VERSION ""

NS_ :

BS_:

BU_: L_DHRR_FD L_UWB_BLE_MST_FD L_UWB_RR_FD L_UWB_BLE_SLV_FD L_UWB_FR_FD L_ROA_FR_FD L_ROA_FD L_DHRL_FD L_UWB_TRNK_FD L_UWB_FRNK_FD L_EDT_FD L_UWB_FL_FD GW_BDC_FD L_UWB_RL_FD L_SAL_FD L_WPC_FD L_TPMS_FD L_DHL_FD L_DHR_FD

BO_ 2348810498 L_TP_BDC_FD_L_UWB_BLE_SLV_FD: 32 GW_BDC_FD
 SG_ L_TP_BDC_FD_L_UWB_BLE_SLV_FD_Byt : 0|8@1+ (1,0) [0|0] ""  L_UWB_BLE_SLV_FD
 SG_ L_TP_BDC_FD_L_UWB_BLE_SLV_F_0000 : 104|8@1+ (1,0) [0|0] ""  L_UWB_BLE_SLV_FD
 SG_ L_TP_BDC_FD_L_UWB_BLE_SLV_F_0001 : 112|8@1+ (1,0) [0|0] ""  L_UWB_BLE_SLV_FD
 SG_ L_TP_BDC_FD_L_UWB_BLE_SLV_F_0002 : 120|8@1+ (1,0) [0|0] ""  L_UWB_BLE_SLV_FD
 SG_ L_TP_BDC_FD_L_UWB_BLE_SLV_F_0003 : 128|8@1+ (1,0) [0|0] ""  L_UWB_BLE_SLV_FD
 SG_ L_TP_BDC_FD_L_UWB_BLE_SLV_F_0004 : 136|8@1+ (1,0) [0|0] ""  L_UWB_BLE_SLV_FD
 SG_ L_TP_BDC_FD_L_UWB_BLE_SLV_F_0005 : 144|8@1+ (1,0) [0|0] ""  L_UWB_BLE_SLV_FD
 SG_ L_TP_BDC_FD_L_UWB_BLE_SLV_F_0006 : 152|8@1+ (1,0) [0|0] ""  L_UWB_BLE_SLV_FD
 SG_ L_TP_BDC_FD_L_UWB_BLE_SLV_F_0007 : 16|8@1+ (1,0) [0|0] ""  L_UWB_BLE_SLV_FD
 SG_ L_TP_BDC_FD_L_UWB_BLE_SLV_F_0008 : 160|8@1+ (1,0) [0|0] ""  L_UWB_BLE_SLV_FD
 SG_ L_TP_BDC_FD_L_UWB_BLE_SLV_F_0009 : 168|8@1+ (1,0) [0|0] ""  L_UWB_BLE_SLV_FD
 SG_ L_TP_BDC_FD_L_UWB_BLE_SLV_F_0010 : 176|8@1+ (1,0) [0|0] ""  L_UWB_BLE_SLV_FD
 SG_ L_TP_BDC_FD_L_UWB_BLE_SLV_F_0011 : 184|8@1+ (1,0) [0|0] ""  L_UWB_BLE_SLV_FD
 SG_ L_TP_BDC_FD_L_UWB_BLE_SLV_F_0012 : 192|8@1+ (1,0) [0|0] ""  L_UWB_BLE_SLV_FD
 SG_ L_TP_BDC_FD_L_UWB_BLE_SLV_F_0013 : 200|8@1+ (1,0) [0|0] ""  L_UWB_BLE_SLV_FD
 SG_ L_TP_BDC_FD_L_UWB_BLE_SLV_F_0014 : 208|8@1+ (1,0) [0|0] ""  L_UWB_BLE_SLV_FD
 SG_ L_TP_BDC_FD_L_UWB_BLE_SLV_F_0015 : 216|8@1+ (1,0) [0|0] ""  L_UWB_BLE_SLV_FD
 SG_ L_TP_BDC_FD_L_UWB_BLE_SLV_F_0016 : 224|8@1+ (1,0) [0|0] ""  L_UWB_BLE_SLV_FD
 SG_ L_TP_BDC_FD_L_UWB_BLE_SLV_F_0017 : 232|8@1+ (1,0) [0|0] ""  L_UWB_BLE_SLV_FD
 SG_ L_TP_BDC_FD_L_UWB_BLE_SLV_F_0018 : 24|8@1+ (1,0) [0|0] ""  L_UWB_BLE_SLV_FD
 SG_ L_TP_BDC_FD_L_UWB_BLE_SLV_F_0019 : 240|8@1+ (1,0) [0|0] ""  L_UWB_BLE_SLV_FD
 SG_ L_TP_BDC_FD_L_UWB_BLE_SLV_F_0020 : 248|8@1+ (1,0) [0|0] ""  L_UWB_BLE_SLV_FD
 SG_ L_TP_BDC_FD_L_UWB_BLE_SLV_F_0021 : 32|8@1+ (1,0) [0|0] ""  L_UWB_BLE_SLV_FD
 SG_ L_TP_BDC_FD_L_UWB_BLE_SLV_F_0022 : 40|8@1+ (1,0) [0|0] ""  L_UWB_BLE_SLV_FD
 SG_ L_TP_BDC_FD_L_UWB_BLE_SLV_F_0023 : 48|8@1+ (1,0) [0|0] ""  L_UWB_BLE_SLV_FD
 SG_ L_TP_BDC_FD_L_UWB_BLE_SLV_F_0024 : 56|8@1+ (1,0) [0|0] ""  L_UWB_BLE_SLV_FD
 SG_ L_TP_BDC_FD_L_UWB_BLE_SLV_F_0025 : 64|8@1+ (1,0) [0|0] ""  L_UWB_BLE_SLV_FD
 SG_ L_TP_BDC_FD_L_UWB_BLE_SLV_F_0026 : 72|8@1+ (1,0) [0|0] ""  L_UWB_BLE_SLV_FD
 SG_ L_TP_BDC_FD_L_UWB_BLE_SLV_F_0027 : 8|8@1+ (1,0) [0|0] ""  L_UWB_BLE_SLV_FD
 SG_ L_TP_BDC_FD_L_UWB_BLE_SLV_F_0028 : 80|8@1+ (1,0) [0|0] ""  L_UWB_BLE_SLV_FD
 SG_ L_TP_BDC_FD_L_UWB_BLE_SLV_F_0029 : 88|8@1+ (1,0) [0|0] ""  L_UWB_BLE_SLV_FD
 SG_ L_TP_BDC_FD_L_UWB_BLE_SLV_F_0030 : 96|8@1+ (1,0) [0|0] ""  L_UWB_BLE_SLV_FD

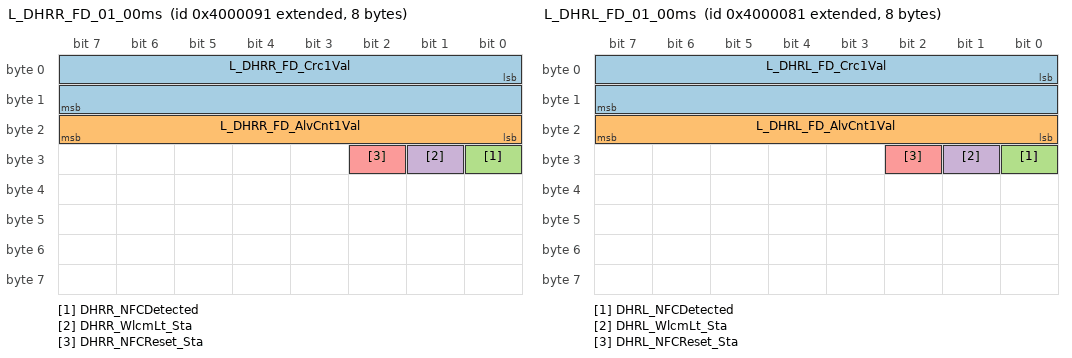
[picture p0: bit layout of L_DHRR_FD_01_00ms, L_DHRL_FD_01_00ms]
BO_ 2214592657 L_DHRR_FD_01_00ms: 8 L_DHRR_FD
 SG_ L_DHRR_FD_Crc1Val : 0|16@1+ (1,0) [0|0] "0" Vector__XXX
 SG_ L_DHRR_FD_AlvCnt1Val : 16|8@1+ (1,0) [0|0] "0" Vector__XXX
 SG_ DHRR_NFCDetected : 24|1@1+ (1,0) [0|0] ""  GW_BDC_FD
 SG_ DHRR_WlcmLt_Sta : 25|1@1+ (1,0) [0|0] ""  GW_BDC_FD
 SG_ DHRR_NFCReset_Sta : 26|1@1+ (1,0) [0|0] ""  GW_BDC_FD

BO_ 2348810497 L_TP_L_UWB_BLE_MST_FD_BDC_FD: 32 L_UWB_BLE_MST_FD
 SG_ L_TP_L_UWB_BLE_MST_FD_BDC_FD_Byt : 0|8@1+ (1,0) [0|0] ""  GW_BDC_FD
 SG_ L_TP_L_UWB_BLE_MST_FD_BDC_F_0000 : 104|8@1+ (1,0) [0|0] ""  GW_BDC_FD
 SG_ L_TP_L_UWB_BLE_MST_FD_BDC_F_0001 : 112|8@1+ (1,0) [0|0] ""  GW_BDC_FD
 SG_ L_TP_L_UWB_BLE_MST_FD_BDC_F_0002 : 120|8@1+ (1,0) [0|0] ""  GW_BDC_FD
 SG_ L_TP_L_UWB_BLE_MST_FD_BDC_F_0003 : 128|8@1+ (1,0) [0|0] ""  GW_BDC_FD
 SG_ L_TP_L_UWB_BLE_MST_FD_BDC_F_0004 : 136|8@1+ (1,0) [0|0] ""  GW_BDC_FD
 SG_ L_TP_L_UWB_BLE_MST_FD_BDC_F_0005 : 144|8@1+ (1,0) [0|0] ""  GW_BDC_FD
 SG_ L_TP_L_UWB_BLE_MST_FD_BDC_F_0006 : 152|8@1+ (1,0) [0|0] ""  GW_BDC_FD
 SG_ L_TP_L_UWB_BLE_MST_FD_BDC_F_0007 : 16|8@1+ (1,0) [0|0] ""  GW_BDC_FD
 SG_ L_TP_L_UWB_BLE_MST_FD_BDC_F_0008 : 160|8@1+ (1,0) [0|0] ""  GW_BDC_FD
 SG_ L_TP_L_UWB_BLE_MST_FD_BDC_F_0009 : 168|8@1+ (1,0) [0|0] ""  GW_BDC_FD
 SG_ L_TP_L_UWB_BLE_MST_FD_BDC_F_0010 : 176|8@1+ (1,0) [0|0] ""  GW_BDC_FD
 SG_ L_TP_L_UWB_BLE_MST_FD_BDC_F_0011 : 184|8@1+ (1,0) [0|0] ""  GW_BDC_FD
 SG_ L_TP_L_UWB_BLE_MST_FD_BDC_F_0012 : 192|8@1+ (1,0) [0|0] ""  GW_BDC_FD
 SG_ L_TP_L_UWB_BLE_MST_FD_BDC_F_0013 : 200|8@1+ (1,0) [0|0] ""  GW_BDC_FD
 SG_ L_TP_L_UWB_BLE_MST_FD_BDC_F_0014 : 208|8@1+ (1,0) [0|0] ""  GW_BDC_FD
 SG_ L_TP_L_UWB_BLE_MST_FD_BDC_F_0015 : 216|8@1+ (1,0) [0|0] ""  GW_BDC_FD
 SG_ L_TP_L_UWB_BLE_MST_FD_BDC_F_0016 : 224|8@1+ (1,0) [0|0] ""  GW_BDC_FD
 SG_ L_TP_L_UWB_BLE_MST_FD_BDC_F_0017 : 232|8@1+ (1,0) [0|0] ""  GW_BDC_FD
 SG_ L_TP_L_UWB_BLE_MST_FD_BDC_F_0018 : 24|8@1+ (1,0) [0|0] ""  GW_BDC_FD
 SG_ L_TP_L_UWB_BLE_MST_FD_BDC_F_0019 : 240|8@1+ (1,0) [0|0] ""  GW_BDC_FD
 SG_ L_TP_L_UWB_BLE_MST_FD_BDC_F_0020 : 248|8@1+ (1,0) [0|0] ""  GW_BDC_FD
 SG_ L_TP_L_UWB_BLE_MST_FD_BDC_F_0021 : 32|8@1+ (1,0) [0|0] ""  GW_BDC_FD
 SG_ L_TP_L_UWB_BLE_MST_FD_BDC_F_0022 : 40|8@1+ (1,0) [0|0] ""  GW_BDC_FD
 SG_ L_TP_L_UWB_BLE_MST_FD_BDC_F_0023 : 48|8@1+ (1,0) [0|0] ""  GW_BDC_FD
 SG_ L_TP_L_UWB_BLE_MST_FD_BDC_F_0024 : 56|8@1+ (1,0) [0|0] ""  GW_BDC_FD
 SG_ L_TP_L_UWB_BLE_MST_FD_BDC_F_0025 : 64|8@1+ (1,0) [0|0] ""  GW_BDC_FD
 SG_ L_TP_L_UWB_BLE_MST_FD_BDC_F_0026 : 72|8@1+ (1,0) [0|0] ""  GW_BDC_FD
 SG_ L_TP_L_UWB_BLE_MST_FD_BDC_F_0027 : 8|8@1+ (1,0) [0|0] ""  GW_BDC_FD
 SG_ L_TP_L_UWB_BLE_MST_FD_BDC_F_0028 : 80|8@1+ (1,0) [0|0] ""  GW_BDC_FD
 SG_ L_TP_L_UWB_BLE_MST_FD_BDC_F_0029 : 88|8@1+ (1,0) [0|0] ""  GW_BDC_FD
 SG_ L_TP_L_UWB_BLE_MST_FD_BDC_F_0030 : 96|8@1+ (1,0) [0|0] ""  GW_BDC_FD

BO_ 2348810496 L_TP_BDC_FD_L_UWB_BLE_MST_FD: 32 GW_BDC_FD
 SG_ L_TP_BDC_FD_L_UWB_BLE_MST_FD_Byt : 0|8@1+ (1,0) [0|0] ""  L_UWB_BLE_MST_FD
 SG_ L_TP_BDC_FD_L_UWB_BLE_MST_F_0000 : 104|8@1+ (1,0) [0|0] ""  L_UWB_BLE_MST_FD
 SG_ L_TP_BDC_FD_L_UWB_BLE_MST_F_0001 : 112|8@1+ (1,0) [0|0] ""  L_UWB_BLE_MST_FD
 SG_ L_TP_BDC_FD_L_UWB_BLE_MST_F_0002 : 120|8@1+ (1,0) [0|0] ""  L_UWB_BLE_MST_FD
 SG_ L_TP_BDC_FD_L_UWB_BLE_MST_F_0003 : 128|8@1+ (1,0) [0|0] ""  L_UWB_BLE_MST_FD
 SG_ L_TP_BDC_FD_L_UWB_BLE_MST_F_0004 : 136|8@1+ (1,0) [0|0] ""  L_UWB_BLE_MST_FD
 SG_ L_TP_BDC_FD_L_UWB_BLE_MST_F_0005 : 144|8@1+ (1,0) [0|0] ""  L_UWB_BLE_MST_FD
 SG_ L_TP_BDC_FD_L_UWB_BLE_MST_F_0006 : 152|8@1+ (1,0) [0|0] ""  L_UWB_BLE_MST_FD
 SG_ L_TP_BDC_FD_L_UWB_BLE_MST_F_0007 : 16|8@1+ (1,0) [0|0] ""  L_UWB_BLE_MST_FD
 SG_ L_TP_BDC_FD_L_UWB_BLE_MST_F_0008 : 160|8@1+ (1,0) [0|0] ""  L_UWB_BLE_MST_FD
 SG_ L_TP_BDC_FD_L_UWB_BLE_MST_F_0009 : 168|8@1+ (1,0) [0|0] ""  L_UWB_BLE_MST_FD
 SG_ L_TP_BDC_FD_L_UWB_BLE_MST_F_0010 : 176|8@1+ (1,0) [0|0] ""  L_UWB_BLE_MST_FD
 SG_ L_TP_BDC_FD_L_UWB_BLE_MST_F_0011 : 184|8@1+ (1,0) [0|0] ""  L_UWB_BLE_MST_FD
 SG_ L_TP_BDC_FD_L_UWB_BLE_MST_F_0012 : 192|8@1+ (1,0) [0|0] ""  L_UWB_BLE_MST_FD
 SG_ L_TP_BDC_FD_L_UWB_BLE_MST_F_0013 : 200|8@1+ (1,0) [0|0] ""  L_UWB_BLE_MST_FD
 SG_ L_TP_BDC_FD_L_UWB_BLE_MST_F_0014 : 208|8@1+ (1,0) [0|0] ""  L_UWB_BLE_MST_FD
 SG_ L_TP_BDC_FD_L_UWB_BLE_MST_F_0015 : 216|8@1+ (1,0) [0|0] ""  L_UWB_BLE_MST_FD
 SG_ L_TP_BDC_FD_L_UWB_BLE_MST_F_0016 : 224|8@1+ (1,0) [0|0] ""  L_UWB_BLE_MST_FD
 SG_ L_TP_BDC_FD_L_UWB_BLE_MST_F_0017 : 232|8@1+ (1,0) [0|0] ""  L_UWB_BLE_MST_FD
 SG_ L_TP_BDC_FD_L_UWB_BLE_MST_F_0018 : 24|8@1+ (1,0) [0|0] ""  L_UWB_BLE_MST_FD
 SG_ L_TP_BDC_FD_L_UWB_BLE_MST_F_0019 : 240|8@1+ (1,0) [0|0] ""  L_UWB_BLE_MST_FD
 SG_ L_TP_BDC_FD_L_UWB_BLE_MST_F_0020 : 248|8@1+ (1,0) [0|0] ""  L_UWB_BLE_MST_FD
 SG_ L_TP_BDC_FD_L_UWB_BLE_MST_F_0021 : 32|8@1+ (1,0) [0|0] ""  L_UWB_BLE_MST_FD
 SG_ L_TP_BDC_FD_L_UWB_BLE_MST_F_0022 : 40|8@1+ (1,0) [0|0] ""  L_UWB_BLE_MST_FD
 SG_ L_TP_BDC_FD_L_UWB_BLE_MST_F_0023 : 48|8@1+ (1,0) [0|0] ""  L_UWB_BLE_MST_FD
 SG_ L_TP_BDC_FD_L_UWB_BLE_MST_F_0024 : 56|8@1+ (1,0) [0|0] ""  L_UWB_BLE_MST_FD
 SG_ L_TP_BDC_FD_L_UWB_BLE_MST_F_0025 : 64|8@1+ (1,0) [0|0] ""  L_UWB_BLE_MST_FD
 SG_ L_TP_BDC_FD_L_UWB_BLE_MST_F_0026 : 72|8@1+ (1,0) [0|0] ""  L_UWB_BLE_MST_FD
 SG_ L_TP_BDC_FD_L_UWB_BLE_MST_F_0027 : 8|8@1+ (1,0) [0|0] ""  L_UWB_BLE_MST_FD
 SG_ L_TP_BDC_FD_L_UWB_BLE_MST_F_0028 : 80|8@1+ (1,0) [0|0] ""  L_UWB_BLE_MST_FD
 SG_ L_TP_BDC_FD_L_UWB_BLE_MST_F_0029 : 88|8@1+ (1,0) [0|0] ""  L_UWB_BLE_MST_FD
 SG_ L_TP_BDC_FD_L_UWB_BLE_MST_F_0030 : 96|8@1+ (1,0) [0|0] ""  L_UWB_BLE_MST_FD

BO_ 2214592645 L_DHRL_FD_Dvp_01_00ms: 32 L_DHRL_FD
 SG_ DHRL_Dvp_Msg : 0|255@1+ (1,0) [0|0] ""  L_EDT_FD

BO_ 2214592644 L_DHL_FD_Dvp_01_00ms: 32 L_DHL_FD
 SG_ DHL_Dvp_Msg : 0|255@1+ (1,0) [0|0] ""  L_EDT_FD

BO_ 2214592641 L_DHRL_FD_01_00ms: 8 L_DHRL_FD
 SG_ L_DHRL_FD_Crc1Val : 0|16@1+ (1,0) [0|0] "0" Vector__XXX
 SG_ L_DHRL_FD_AlvCnt1Val : 16|8@1+ (1,0) [0|0] "0" Vector__XXX
 SG_ DHRL_NFCDetected : 24|1@1+ (1,0) [0|0] ""  GW_BDC_FD
 SG_ DHRL_WlcmLt_Sta : 25|1@1+ (1,0) [0|0] ""  GW_BDC_FD
 SG_ DHRL_NFCReset_Sta : 26|1@1+ (1,0) [0|0] ""  GW_BDC_FD

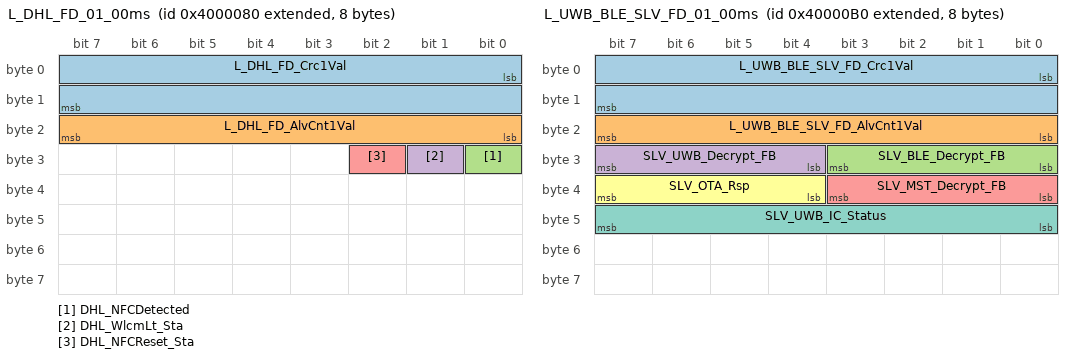
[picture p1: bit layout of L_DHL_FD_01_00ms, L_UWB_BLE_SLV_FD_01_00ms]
BO_ 2214592640 L_DHL_FD_01_00ms: 8 L_DHL_FD
 SG_ L_DHL_FD_Crc1Val : 0|16@1+ (1,0) [0|0] "0" Vector__XXX
 SG_ L_DHL_FD_AlvCnt1Val : 16|8@1+ (1,0) [0|0] "0" Vector__XXX
 SG_ DHL_NFCDetected : 24|1@1+ (1,0) [0|0] ""  GW_BDC_FD
 SG_ DHL_WlcmLt_Sta : 25|1@1+ (1,0) [0|0] ""  GW_BDC_FD
 SG_ DHL_NFCReset_Sta : 26|1@1+ (1,0) [0|0] ""  GW_BDC_FD

BO_ 2529538305 L_UWB_RL_FD_05_00ms: 32 L_UWB_RL_FD
 SG_ L_UWB_RL_FD_Crc5Val : 0|16@1+ (1,0) [0|0] "" Vector__XXX
 SG_ L_UWB_RL_FD_AlvCnt5Val : 16|8@1+ (1,0) [0|0] "" Vector__XXX
 SG_ RL_SWID_3_IVD_2 : 24|24@1+ (1,0) [0|0] ""  L_UWB_BLE_MST_FD

BO_ 2533736705 L_UWB_TRNK_FD_05_00ms: 32 L_UWB_TRNK_FD
 SG_ L_UWB_TRNK_FD_Crc5Val : 0|16@1+ (1,0) [0|0] "" Vector__XXX
 SG_ L_UWB_TRNK_FD_AlvCnt5Val : 16|8@1+ (1,0) [0|0] "" Vector__XXX
 SG_ TRNK_SWID_3_IVD_2 : 24|24@1+ (1,0) [0|0] ""  L_UWB_BLE_MST_FD

BO_ 2214592703 L_UWB_BLE_SLV_FD_Dvp_01_00ms: 32 L_UWB_BLE_SLV_FD
 SG_ SLV_Dvp_Data : 0|255@1+ (1,0) [0|0] ""  L_EDT_FD

BO_ 2214592698 L_UWB_BLE_MST_FD_Dvp_02_00ms: 32 L_UWB_BLE_MST_FD
 SG_ MST_Dvp_Data_02 : 0|255@1+ (1,0) [0|0] "" Vector__XXX

BO_ 2214592699 L_UWB_BLE_MST_FD_Dvp_03_00ms: 32 L_UWB_BLE_MST_FD
 SG_ MST_Dvp_Data_03 : 0|255@1+ (1,0) [0|0] "" Vector__XXX

BO_ 2214592694 L_UWB_BLE_SLV_FD_07_00ms: 32 L_UWB_BLE_SLV_FD
 SG_ L_UWB_BLE_SLV_FD_Crc7Val : 0|16@1+ (1,0) [0|0] "0" Vector__XXX
 SG_ L_UWB_BLE_SLV_FD_AlvCnt7Val : 16|8@1+ (1,0) [0|0] "0" Vector__XXX
 SG_ SLV_To_MST_Enc_Data4 : 24|232@1+ (1,0) [0|0] ""  L_UWB_BLE_MST_FD

BO_ 2214592695 L_UWB_BLE_SLV_FD_08_00ms: 32 L_UWB_BLE_SLV_FD
 SG_ L_UWB_BLE_SLV_FD_Crc8Val : 0|16@1+ (1,0) [0|0] "0" Vector__XXX
 SG_ L_UWB_BLE_SLV_FD_AlvCnt8Val : 16|8@1+ (1,0) [0|0] "0" Vector__XXX
 SG_ SLV_To_MST_Enc_Data5 : 24|232@1+ (1,0) [0|0] ""  L_UWB_BLE_MST_FD

BO_ 2214592692 L_UWB_BLE_SLV_FD_05_00ms: 32 L_UWB_BLE_SLV_FD
 SG_ L_UWB_BLE_SLV_FD_Crc5Val : 0|16@1+ (1,0) [0|0] "0" Vector__XXX
 SG_ L_UWB_BLE_SLV_FD_AlvCnt5Val : 16|8@1+ (1,0) [0|0] "0" Vector__XXX
 SG_ SLV_To_MST_Enc_Data2 : 24|232@1+ (1,0) [0|0] ""  L_UWB_BLE_MST_FD

BO_ 2214592693 L_UWB_BLE_SLV_FD_06_00ms: 32 L_UWB_BLE_SLV_FD
 SG_ L_UWB_BLE_SLV_FD_Crc6Val : 0|16@1+ (1,0) [0|0] "0" Vector__XXX
 SG_ L_UWB_BLE_SLV_FD_AlvCnt6Val : 16|8@1+ (1,0) [0|0] "0" Vector__XXX
 SG_ SLV_To_MST_Enc_Data3 : 24|232@1+ (1,0) [0|0] ""  L_UWB_BLE_MST_FD

BO_ 2214592690 L_UWB_BLE_SLV_FD_03_00ms: 32 L_UWB_BLE_SLV_FD
 SG_ L_UWB_BLE_SLV_FD_Crc3Val : 0|16@1+ (1,0) [0|0] "0" Vector__XXX
 SG_ L_UWB_BLE_SLV_FD_AlvCnt3Val : 16|8@1+ (1,0) [0|0] "0" Vector__XXX
 SG_ SLV_UWB_Ranging_Enc_Result2 : 216|40@1+ (1,0) [0|0] ""  GW_BDC_FD,L_UWB_BLE_MST_FD
 SG_ SLV_UWB_Ranging_Enc_Result : 24|192@1+ (1,0) [0|0] ""  GW_BDC_FD,L_UWB_BLE_MST_FD

BO_ 2214592691 L_UWB_BLE_SLV_FD_04_00ms: 32 L_UWB_BLE_SLV_FD
 SG_ L_UWB_BLE_SLV_FD_Crc4Val : 0|16@1+ (1,0) [0|0] "0" Vector__XXX
 SG_ L_UWB_BLE_SLV_FD_AlvCnt4Val : 16|8@1+ (1,0) [0|0] "0" Vector__XXX
 SG_ SLV_To_MST_Enc_Data1 : 24|232@1+ (1,0) [0|0] ""  L_UWB_BLE_MST_FD

BO_ 2214592688 L_UWB_BLE_SLV_FD_01_00ms: 8 L_UWB_BLE_SLV_FD
 SG_ L_UWB_BLE_SLV_FD_Crc1Val : 0|16@1+ (1,0) [0|0] "0" Vector__XXX
 SG_ L_UWB_BLE_SLV_FD_AlvCnt1Val : 16|8@1+ (1,0) [0|0] "0" Vector__XXX
 SG_ SLV_BLE_Decrypt_FB : 24|4@1+ (1,0) [0|0] ""  GW_BDC_FD
 SG_ SLV_UWB_Decrypt_FB : 28|4@1+ (1,0) [0|0] ""  GW_BDC_FD
 SG_ SLV_MST_Decrypt_FB : 32|4@1+ (1,0) [0|0] ""  L_UWB_BLE_MST_FD
 SG_ SLV_OTA_Rsp : 36|4@1+ (1,0) [0|0] ""  L_UWB_BLE_MST_FD
 SG_ SLV_UWB_IC_Status : 40|8@1+ (1,0) [0|0] ""  L_EDT_FD

BO_ 2214592689 L_UWB_BLE_SLV_FD_02_00ms: 16 L_UWB_BLE_SLV_FD
 SG_ L_UWB_BLE_SLV_FD_Crc2Val : 0|16@1+ (1,0) [0|0] "0" Vector__XXX
 SG_ L_UWB_BLE_SLV_FD_AlvCnt2Val : 16|8@1+ (1,0) [0|0] "0" Vector__XXX
 SG_ SLV_UWB_FOB_RSD_Enc_Result : 24|64@1+ (1,0) [0|0] ""  GW_BDC_FD

BO_ 2214592687 L_UWB_BLE_MST_FD_Dvp_01_00ms: 32 L_UWB_BLE_MST_FD
 SG_ MST_Dvp_Data : 0|255@1+ (1,0) [0|0] ""  L_EDT_FD

BO_ 2214592686 L_UWB_BLE_MST_FD_15_00ms: 32 L_UWB_BLE_MST_FD
 SG_ L_UWB_BLE_MST_FD_Crc15Val : 0|16@1+ (1,0) [0|0] "0" Vector__XXX
 SG_ L_UWB_BLE_MST_FD_AlvCnt15Val : 16|8@1+ (1,0) [0|0] "0" Vector__XXX
 SG_ MST_Download_Data : 24|232@1+ (1,0) [0|0] ""  L_UWB_BLE_SLV_FD,L_UWB_FL_FD,L_UWB_FRNK_FD,L_UWB_FR_FD,L_UWB_RL_FD,L_UWB_RR_FD,L_UWB_TRNK_FD

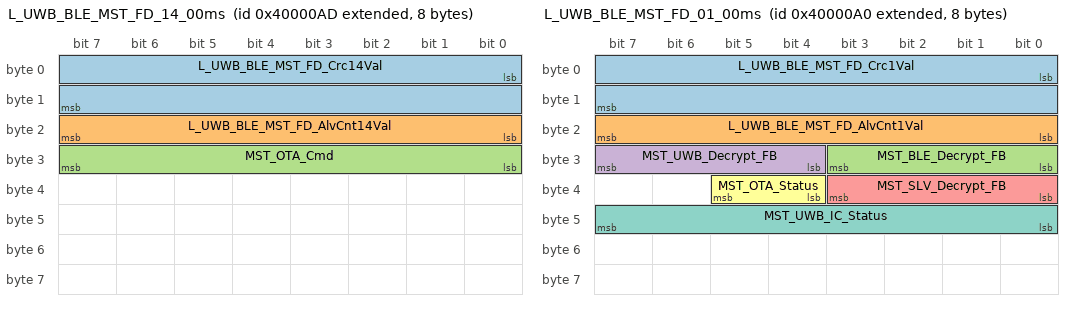
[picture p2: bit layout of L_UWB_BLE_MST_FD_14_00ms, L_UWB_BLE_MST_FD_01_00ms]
BO_ 2214592685 L_UWB_BLE_MST_FD_14_00ms: 8 L_UWB_BLE_MST_FD
 SG_ L_UWB_BLE_MST_FD_Crc14Val : 0|16@1+ (1,0) [0|0] "0" Vector__XXX
 SG_ L_UWB_BLE_MST_FD_AlvCnt14Val : 16|8@1+ (1,0) [0|0] "0" Vector__XXX
 SG_ MST_OTA_Cmd : 24|8@1+ (1,0) [0|0] ""  L_UWB_BLE_SLV_FD,L_UWB_FL_FD,L_UWB_FRNK_FD,L_UWB_FR_FD,L_UWB_RL_FD,L_UWB_RR_FD,L_UWB_TRNK_FD

BO_ 2214592684 L_UWB_BLE_MST_FD_13_200ms: 32 L_UWB_BLE_MST_FD
 SG_ L_UWB_BLE_MST_FD_Crc13Val : 0|16@1+ (1,0) [0|0] "0" Vector__XXX
 SG_ L_UWB_BLE_MST_FD_AlvCnt13Val : 16|8@1+ (1,0) [0|0] "0" Vector__XXX
 SG_ MST_To_BDC_Loc_Enc_Data2 : 24|232@1+ (1,0) [0|0] ""  GW_BDC_FD

BO_ 2214592683 L_UWB_BLE_MST_FD_12_200ms: 32 L_UWB_BLE_MST_FD
 SG_ L_UWB_BLE_MST_FD_Crc12Val : 0|16@1+ (1,0) [0|0] "0" Vector__XXX
 SG_ L_UWB_BLE_MST_FD_AlvCnt12Val : 16|8@1+ (1,0) [0|0] "0" Vector__XXX
 SG_ MST_To_BDC_Loc_Enc_Data1 : 24|232@1+ (1,0) [0|0] ""  GW_BDC_FD

BO_ 2214592682 L_UWB_BLE_MST_FD_11_00ms: 32 L_UWB_BLE_MST_FD
 SG_ L_UWB_BLE_MST_FD_Crc11Val : 0|16@1+ (1,0) [0|0] "0" Vector__XXX
 SG_ L_UWB_BLE_MST_FD_AlvCnt11Val : 16|8@1+ (1,0) [0|0] "0" Vector__XXX
 SG_ MST_BLE_To_BDC_Enc_Data2 : 24|232@1+ (1,0) [0|0] ""  GW_BDC_FD

BO_ 2214592681 L_UWB_BLE_MST_FD_10_00ms: 32 L_UWB_BLE_MST_FD
 SG_ L_UWB_BLE_MST_FD_Crc10Val : 0|16@1+ (1,0) [0|0] "0" Vector__XXX
 SG_ L_UWB_BLE_MST_FD_AlvCnt10Val : 16|8@1+ (1,0) [0|0] "0" Vector__XXX
 SG_ MST_BLE_To_BDC_Enc_Data1 : 24|232@1+ (1,0) [0|0] ""  GW_BDC_FD

BO_ 2214592680 L_UWB_BLE_MST_FD_09_00ms: 32 L_UWB_BLE_MST_FD
 SG_ L_UWB_BLE_MST_FD_Crc9Val : 0|16@1+ (1,0) [0|0] "0" Vector__XXX
 SG_ L_UWB_BLE_MST_FD_AlvCnt9Val : 16|8@1+ (1,0) [0|0] "0" Vector__XXX
 SG_ MST_To_UWB_Enc_Data5 : 24|232@1+ (1,0) [0|0] ""  L_UWB_BLE_SLV_FD,L_UWB_FL_FD,L_UWB_FRNK_FD,L_UWB_FR_FD,L_UWB_RL_FD,L_UWB_RR_FD,L_UWB_TRNK_FD

BO_ 2214592679 L_UWB_BLE_MST_FD_08_00ms: 32 L_UWB_BLE_MST_FD
 SG_ L_UWB_BLE_MST_FD_Crc8Val : 0|16@1+ (1,0) [0|0] "0" Vector__XXX
 SG_ L_UWB_BLE_MST_FD_AlvCnt8Val : 16|8@1+ (1,0) [0|0] "0" Vector__XXX
 SG_ MST_To_UWB_Enc_Data4 : 24|232@1+ (1,0) [0|0] ""  L_UWB_BLE_SLV_FD,L_UWB_FL_FD,L_UWB_FRNK_FD,L_UWB_FR_FD,L_UWB_RL_FD,L_UWB_RR_FD,L_UWB_TRNK_FD

BO_ 2214592678 L_UWB_BLE_MST_FD_07_00ms: 32 L_UWB_BLE_MST_FD
 SG_ L_UWB_BLE_MST_FD_Crc7Val : 0|16@1+ (1,0) [0|0] "0" Vector__XXX
 SG_ L_UWB_BLE_MST_FD_AlvCnt7Val : 16|8@1+ (1,0) [0|0] "0" Vector__XXX
 SG_ MST_To_UWB_Enc_Data3 : 24|232@1+ (1,0) [0|0] ""  L_UWB_BLE_SLV_FD,L_UWB_FL_FD,L_UWB_FRNK_FD,L_UWB_FR_FD,L_UWB_RL_FD,L_UWB_RR_FD,L_UWB_TRNK_FD

BO_ 2529538817 L_UWB_RL_FD_07_00ms: 32 L_UWB_RL_FD
 SG_ L_UWB_RL_FD_Crc7Val : 0|16@1+ (1,0) [0|0] "" Vector__XXX
 SG_ L_UWB_RL_FD_AlvCnt7Val : 16|8@1+ (1,0) [0|0] "" Vector__XXX
 SG_ RL_SWID_4_IVD_2 : 24|24@1+ (1,0) [0|0] ""  L_UWB_BLE_MST_FD

BO_ 2214592677 L_UWB_BLE_MST_FD_06_00ms: 32 L_UWB_BLE_MST_FD
 SG_ L_UWB_BLE_MST_FD_Crc6Val : 0|16@1+ (1,0) [0|0] "0" Vector__XXX
 SG_ L_UWB_BLE_MST_FD_AlvCnt6Val : 16|8@1+ (1,0) [0|0] "0" Vector__XXX
 SG_ MST_To_UWB_Enc_Data2 : 24|232@1+ (1,0) [0|0] ""  L_UWB_BLE_SLV_FD,L_UWB_FL_FD,L_UWB_FRNK_FD,L_UWB_FR_FD,L_UWB_RL_FD,L_UWB_RR_FD,L_UWB_TRNK_FD

BO_ 2214592676 L_UWB_BLE_MST_FD_05_00ms: 32 L_UWB_BLE_MST_FD
 SG_ L_UWB_BLE_MST_FD_Crc5Val : 0|16@1+ (1,0) [0|0] "0" Vector__XXX
 SG_ L_UWB_BLE_MST_FD_AlvCnt5Val : 16|8@1+ (1,0) [0|0] "0" Vector__XXX
 SG_ MST_To_UWB_Enc_Data1 : 24|232@1+ (1,0) [0|0] ""  L_UWB_BLE_SLV_FD,L_UWB_FL_FD,L_UWB_FRNK_FD,L_UWB_FR_FD,L_UWB_RL_FD,L_UWB_RR_FD,L_UWB_TRNK_FD

BO_ 2533737217 L_UWB_TRNK_FD_07_00ms: 32 L_UWB_TRNK_FD
 SG_ L_UWB_TRNK_FD_Crc7Val : 0|16@1+ (1,0) [0|0] "" Vector__XXX
 SG_ L_UWB_TRNK_FD_AlvCnt7Val : 16|8@1+ (1,0) [0|0] "" Vector__XXX
 SG_ TRNK_SWID_4_IVD_2 : 24|24@1+ (1,0) [0|0] ""  L_UWB_BLE_MST_FD

BO_ 2214592675 L_UWB_BLE_MST_FD_04_00ms: 16 L_UWB_BLE_MST_FD
 SG_ L_UWB_BLE_MST_FD_Crc4Val : 0|16@1+ (1,0) [0|0] "0" Vector__XXX
 SG_ L_UWB_BLE_MST_FD_AlvCnt4Val : 16|8@1+ (1,0) [0|0] "0" Vector__XXX
 SG_ MST_RndNum_Trgt : 24|4@1+ (1,0) [0|0] ""  L_UWB_BLE_SLV_FD,L_UWB_FL_FD,L_UWB_FRNK_FD,L_UWB_FR_FD,L_UWB_RL_FD,L_UWB_RR_FD,L_UWB_TRNK_FD
 SG_ MST_RndNum_TRCode : 28|4@1+ (1,0) [0|0] ""  L_UWB_BLE_SLV_FD,L_UWB_FL_FD,L_UWB_FRNK_FD,L_UWB_FR_FD,L_UWB_RL_FD,L_UWB_RR_FD,L_UWB_TRNK_FD
 SG_ MST_RndNum_Cmd : 32|4@1+ (1,0) [0|0] ""  L_UWB_BLE_SLV_FD,L_UWB_FL_FD,L_UWB_FRNK_FD,L_UWB_FR_FD,L_UWB_RL_FD,L_UWB_RR_FD,L_UWB_TRNK_FD
 SG_ MST_RndNum : 40|48@1+ (1,0) [0|0] ""  L_UWB_BLE_SLV_FD,L_UWB_FL_FD,L_UWB_FRNK_FD,L_UWB_FR_FD,L_UWB_RL_FD,L_UWB_RR_FD,L_UWB_TRNK_FD

BO_ 2214592674 L_UWB_BLE_MST_FD_03_00ms: 32 L_UWB_BLE_MST_FD
 SG_ L_UWB_BLE_MST_FD_Crc3Val : 0|16@1+ (1,0) [0|0] "0" Vector__XXX
 SG_ L_UWB_BLE_MST_FD_AlvCnt3Val : 16|8@1+ (1,0) [0|0] "0" Vector__XXX
 SG_ MST_UWB_Ranging_Enc_Result2 : 216|40@1+ (1,0) [0|0] ""  GW_BDC_FD
 SG_ MST_UWB_Ranging_Enc_Result : 24|192@1+ (1,0) [0|0] ""  GW_BDC_FD

BO_ 2214592673 L_UWB_BLE_MST_FD_02_00ms: 16 L_UWB_BLE_MST_FD
 SG_ L_UWB_BLE_MST_FD_Crc2Val : 0|16@1+ (1,0) [0|0] "0" Vector__XXX
 SG_ L_UWB_BLE_MST_FD_AlvCnt2Val : 16|8@1+ (1,0) [0|0] "0" Vector__XXX
 SG_ MST_UWB_FOB_RSD_Enc_Result : 24|64@1+ (1,0) [0|0] ""  GW_BDC_FD

BO_ 2214592672 L_UWB_BLE_MST_FD_01_00ms: 8 L_UWB_BLE_MST_FD
 SG_ L_UWB_BLE_MST_FD_Crc1Val : 0|16@1+ (1,0) [0|0] "0" Vector__XXX
 SG_ L_UWB_BLE_MST_FD_AlvCnt1Val : 16|8@1+ (1,0) [0|0] "0" Vector__XXX
 SG_ MST_BLE_Decrypt_FB : 24|4@1+ (1,0) [0|0] ""  GW_BDC_FD
 SG_ MST_UWB_Decrypt_FB : 28|4@1+ (1,0) [0|0] ""  GW_BDC_FD
 SG_ MST_SLV_Decrypt_FB : 32|4@1+ (1,0) [0|0] ""  L_UWB_BLE_SLV_FD
 SG_ MST_OTA_Status : 36|2@1+ (1,0) [0|0] ""  GW_BDC_FD
 SG_ MST_UWB_IC_Status : 40|8@1+ (1,0) [0|0] ""  L_EDT_FD

BO_ 2525342465 L_UWB_FR_FD_07_00ms: 32 L_UWB_FR_FD
 SG_ L_UWB_FR_FD_Crc7Val : 0|16@1+ (1,0) [0|0] "" Vector__XXX
 SG_ L_UWB_FR_FD_AlvCnt7Val : 16|8@1+ (1,0) [0|0] "" Vector__XXX
 SG_ FR_SWID_4_IVD_2 : 24|24@1+ (1,0) [0|0] ""  L_UWB_BLE_MST_FD

BO_ 829 SBCM_RR_FD_01_200ms: 24 GW_BDC_FD
 SG_ SBCM_RR_FD_Crc1Val : 0|16@1+ (1,0) [0|0] "" Vector__XXX
 SG_ USM_RRGhostDoorSta_Copy_0 : 100|2@1+ (1,0) [0|0] "" Vector__XXX
 SG_ DoorLock_PDSLkSwSta_RR_Copy_0 : 104|2@1+ (1,0) [0|0] "" Vector__XXX
 SG_ PDS_TypeOption_RR_Copy_0 : 106|2@1+ (1,0) [0|0] "" Vector__XXX
 SG_ RR_CrashMRActAlarm_Copy_0 : 138|2@1+ (1,0) [0|0] "" Vector__XXX
 SG_ PwrDRBuzzerOut_RR_Copy_0 : 140|2@1+ (1,0) [0|0] "" Vector__XXX
 SG_ PwrDRClosingRRDrSta_Copy_0 : 144|3@1+ (1,0) [0|0] "" Vector__XXX
 SG_ AFH_RR_FldUnfldSta_Copy_0 : 150|2@1+ (1,0) [0|0] "" Vector__XXX
 SG_ SBCM_RR_FD_AlvCnt1Val : 16|8@1+ (1,0) [0|0] "" Vector__XXX
 SG_ DoorLock_RrRtLkOutSta_SBCM_Copy_ : 166|2@1+ (1,0) [0|0] "" Vector__XXX
 SG_ RrRt_DrLkRetryFail_SBCM_Copy_0 : 171|2@1+ (1,0) [0|0] "" Vector__XXX
 SG_ RR_DetectObj_warn : 24|2@1+ (1,0) [0|0] "" Vector__XXX
 SG_ RRRrDrCurtainPosition : 26|2@1+ (1,0) [0|0] "" Vector__XXX
 SG_ RRRrDrCurtainDownInitState : 28|2@1+ (1,0) [0|0] "" Vector__XXX
 SG_ PwrDrSta_RrRt : 30|2@1+ (1,0) [0|0] "" Vector__XXX
 SG_ PwrDRBuzzerOut_RR_New : 32|3@1+ (1,0) [0|0] "" Vector__XXX
 SG_ SBCM_RR_SlidePosition : 40|8@1+ (1,0) [0|0] "%" Vector__XXX
 SG_ SBCM_RR_DoorAngle : 48|7@1+ (1,0) [0|0] "вк" Vector__XXX
 SG_ RRDoorPushAlarm_Copy_0 : 72|2@1+ (1,0) [0|0] "" Vector__XXX
 SG_ RR_CrashUnlockCmd_Copy_0 : 74|1@1+ (1,0) [0|0] "" Vector__XXX
 SG_ Warn_RrRtDrSwSta_SBCM_Copy_0 : 80|2@1+ (1,0) [0|0] ""  L_UWB_BLE_MST_FD
 SG_ DoorLock_RrRtDrUnLkSta_SBCM_Copy : 82|2@1+ (1,0) [0|0] ""  L_UWB_BLE_MST_FD
 SG_ RR_SEAActivated_Copy_0 : 84|2@1+ (1,0) [0|0] "" Vector__XXX
 SG_ RR_SEAWarn_Copy_0 : 86|2@1+ (1,0) [0|0] "" Vector__XXX
 SG_ RR_SEWWarn_Copy_0 : 88|2@1+ (1,0) [0|0] "" Vector__XXX
 SG_ RR_ReleaseWarn_Copy_0 : 90|2@1+ (1,0) [0|0] "" Vector__XXX
 SG_ RR_SWFailAlarm_Copy_0 : 92|2@1+ (1,0) [0|0] "" Vector__XXX
 SG_ RR_ChildLock_ActnFlSta_Copy_0 : 94|2@1+ (1,0) [0|0] "" Vector__XXX
 SG_ RR_MRActivationAlarm_Copy_0 : 96|2@1+ (1,0) [0|0] "" Vector__XXX
 SG_ RR_ChildLock_Status_Copy_0 : 98|2@1+ (1,0) [0|0] "" Vector__XXX

CM_ BO_ 2348810498 "[TP] Transport Protocol";
CM_ BO_ 2214592657 "[EC] On Event and On Change";
CM_ SG_ 2214592657 L_DHRR_FD_Crc1Val "L_DHRR_FD_CyclicRedundancyCheck1Value";
CM_ SG_ 2214592657 L_DHRR_FD_AlvCnt1Val "L_DHRR_FD_AliveCounter1Value";
CM_ SG_ 2214592657 DHRR_NFCDetected "Rear RH Door NFC Sensor Input";
CM_ SG_ 2214592657 DHRR_WlcmLt_Sta "Rear RH Door Welcome Light Status";
CM_ SG_ 2214592657 DHRR_NFCReset_Sta "Rear RH Door NFC DeSelect Result";
CM_ BO_ 2348810497 "[TP] Transport Protocol";
CM_ BO_ 2348810496 "[TP] Transport Protocol";
CM_ BO_ 2214592645 "[EW] On Event and On Write";
CM_ SG_ 2214592645 DHRL_Dvp_Msg "Rear LH Door Development Message";
CM_ BO_ 2214592644 "[EW] On Event and On Write";
CM_ SG_ 2214592644 DHL_Dvp_Msg "Development Message";
CM_ BO_ 2214592641 "[EC] On Event and On Change";
CM_ SG_ 2214592641 L_DHRL_FD_Crc1Val "L_DHRL_FD_CyclicRedundancyCheck1Value";
CM_ SG_ 2214592641 L_DHRL_FD_AlvCnt1Val "L_DHRL_FD_AliveCounter1Value";
CM_ SG_ 2214592641 DHRL_NFCDetected "Rear LH Door NFC Sensor Input";
CM_ SG_ 2214592641 DHRL_WlcmLt_Sta "Rear LH Door Welcome Light Status";
CM_ SG_ 2214592641 DHRL_NFCReset_Sta "Rear LH Door NFC DeSelect Result";
CM_ BO_ 2214592640 "[EC] On Event and On Change";
CM_ SG_ 2214592640 L_DHL_FD_Crc1Val "L_DHL_FD_CyclicRedundancyCheck1Value";
CM_ SG_ 2214592640 L_DHL_FD_AlvCnt1Val "L_DHL_FD_AliveCounter1Value";
CM_ SG_ 2214592640 DHL_NFCDetected "LH Door NFC Sensor Input";
CM_ SG_ 2214592640 DHL_WlcmLt_Sta "LH Door Welcome Light Status";
CM_ SG_ 2214592640 DHL_NFCReset_Sta "LH Door NFC DeSelect Result";
CM_ BO_ 2529538305 "[EW] On Event and On Write";
CM_ SG_ 2529538305 L_UWB_RL_FD_Crc5Val "L_UWB_RL_FD_CyclicRedundancyCheck5Value";
CM_ SG_ 2529538305 L_UWB_RL_FD_AlvCnt5Val "L_UWB_RL_FD_AliveCounter5Value";
CM_ SG_ 2529538305 RL_SWID_3_IVD_2 "UWB RL SW Unit 3 IVD2";
CM_ BO_ 2533736705 "[EW] On Event and On Write";
CM_ SG_ 2533736705 L_UWB_TRNK_FD_Crc5Val "L_UWB_TRNK_FD_CyclicRedundancyCheck5Value";
CM_ SG_ 2533736705 L_UWB_TRNK_FD_AlvCnt5Val "L_UWB_TRNK_FD_AliveCounter5Value";
CM_ SG_ 2533736705 TRNK_SWID_3_IVD_2 "UWB TRNK SW Unit 3 IVD2";
CM_ BO_ 2214592703 "[EW] On Event and On Write";
CM_ SG_ 2214592703 SLV_Dvp_Data "Development Message";
CM_ BO_ 2214592698 "[EW] On Event and On Write";
CM_ SG_ 2214592698 MST_Dvp_Data_02 "Development Message";
CM_ BO_ 2214592699 "[EW] On Event and On Write";
CM_ SG_ 2214592699 MST_Dvp_Data_03 "Development Message";
CM_ BO_ 2214592694 "[EC] On Event and On Change";
CM_ SG_ 2214592694 L_UWB_BLE_SLV_FD_Crc7Val "L_UWB_BLE_SLV_FD_CyclicRedundancyCheck7Value";
CM_ SG_ 2214592694 L_UWB_BLE_SLV_FD_AlvCnt7Val "L_UWB_BLE_SLV_FD_AliveCounter7Value";
CM_ SG_ 2214592694 SLV_To_MST_Enc_Data4 "Encryption Data From Slave to Master";
CM_ BO_ 2214592695 "[EC] On Event and On Change";
CM_ SG_ 2214592695 L_UWB_BLE_SLV_FD_Crc8Val "L_UWB_BLE_SLV_FD_CyclicRedundancyCheck8Value";
CM_ SG_ 2214592695 L_UWB_BLE_SLV_FD_AlvCnt8Val "L_UWB_BLE_SLV_FD_AliveCounter8Value";
CM_ SG_ 2214592695 SLV_To_MST_Enc_Data5 "Encryption Data From Slave to Master";
CM_ BO_ 2214592692 "[EC] On Event and On Change";
CM_ SG_ 2214592692 L_UWB_BLE_SLV_FD_Crc5Val "L_UWB_BLE_SLV_FD_CyclicRedundancyCheck5Value";
CM_ SG_ 2214592692 L_UWB_BLE_SLV_FD_AlvCnt5Val "L_UWB_BLE_SLV_FD_AliveCounter5Value";
CM_ SG_ 2214592692 SLV_To_MST_Enc_Data2 "Encryption Data From Slave to Master";
CM_ BO_ 2214592693 "[EC] On Event and On Change";
CM_ SG_ 2214592693 L_UWB_BLE_SLV_FD_Crc6Val "L_UWB_BLE_SLV_FD_CyclicRedundancyCheck6Value";
CM_ SG_ 2214592693 L_UWB_BLE_SLV_FD_AlvCnt6Val "L_UWB_BLE_SLV_FD_AliveCounter6Value";
CM_ SG_ 2214592693 SLV_To_MST_Enc_Data3 "Encryption Data From Slave to Master";
CM_ BO_ 2214592690 "[EW] On Event and On Write";
CM_ SG_ 2214592690 L_UWB_BLE_SLV_FD_Crc3Val "L_UWB_BLE_SLV_FD_CyclicRedundancyCheck3Value";
CM_ SG_ 2214592690 L_UWB_BLE_SLV_FD_AlvCnt3Val "L_UWB_BLE_SLV_FD_AliveCounter3Value";
CM_ SG_ 2214592690 SLV_UWB_Ranging_Enc_Result2 "UWB Ranging Result2(Encrypted Data) with DK";
CM_ SG_ 2214592690 SLV_UWB_Ranging_Enc_Result "UWB Ranging Result with DK";
CM_ BO_ 2214592691 "[EC] On Event and On Change";
CM_ SG_ 2214592691 L_UWB_BLE_SLV_FD_Crc4Val "L_UWB_BLE_SLV_FD_CyclicRedundancyCheck4Value";
CM_ SG_ 2214592691 L_UWB_BLE_SLV_FD_AlvCnt4Val "L_UWB_BLE_SLV_FD_AliveCounter4Value";
CM_ SG_ 2214592691 SLV_To_MST_Enc_Data1 "Encryption Data From Slave to Master";
CM_ BO_ 2214592688 "[EC] On Event and On Change";
CM_ SG_ 2214592688 L_UWB_BLE_SLV_FD_Crc1Val "L_UWB_BLE_SLV_FD_CyclicRedundancyCheck1Value";
CM_ SG_ 2214592688 L_UWB_BLE_SLV_FD_AlvCnt1Val "L_UWB_BLE_SLV_FD_AliveCounter1Value";
CM_ SG_ 2214592688 SLV_BLE_Decrypt_FB "Decryption Feed back for BLE  (to BDC)";
CM_ SG_ 2214592688 SLV_UWB_Decrypt_FB "Decryption Feed back for UWB (to BDC)";
CM_ SG_ 2214592688 SLV_MST_Decrypt_FB "UWB Master Decryption Feed Back";
CM_ SG_ 2214592688 SLV_OTA_Rsp "Slave OTA response";
CM_ SG_ 2214592688 SLV_UWB_IC_Status "UWB IC Status Message";
CM_ BO_ 2214592689 "[EC] On Event and On Change";
CM_ SG_ 2214592689 L_UWB_BLE_SLV_FD_Crc2Val "L_UWB_BLE_SLV_FD_CyclicRedundancyCheck2Value";
CM_ SG_ 2214592689 L_UWB_BLE_SLV_FD_AlvCnt2Val "L_UWB_BLE_SLV_FD_AliveCounter2Value";
CM_ SG_ 2214592689 SLV_UWB_FOB_RSD_Enc_Result "UWB Ranging Result with FOB";
CM_ BO_ 2214592687 "[EW] On Event and On Write";
CM_ SG_ 2214592687 MST_Dvp_Data "Development Message";
CM_ BO_ 2214592686 "[EC] On Event and On Change";
CM_ SG_ 2214592686 L_UWB_BLE_MST_FD_Crc15Val "L_UWB_BLE_MST_FD_CyclicRedundancyCheck15Value";
CM_ SG_ 2214592686 L_UWB_BLE_MST_FD_AlvCnt15Val "L_UWB_BLE_MST_FD_AliveCounter15Value";
CM_ SG_ 2214592686 MST_Download_Data "Reprogramming Download Data";
CM_ BO_ 2214592685 "[EC] On Event and On Change";
CM_ SG_ 2214592685 L_UWB_BLE_MST_FD_Crc14Val "L_UWB_BLE_MST_FD_CyclicRedundancyCheck14Value";
CM_ SG_ 2214592685 L_UWB_BLE_MST_FD_AlvCnt14Val "L_UWB_BLE_MST_FD_AliveCounter14Value";
CM_ SG_ 2214592685 MST_OTA_Cmd "BDC Command for UWB BLE";
CM_ BO_ 2214592684 "[PE] Periodic and On Event";
CM_ SG_ 2214592684 L_UWB_BLE_MST_FD_Crc13Val "L_UWB_BLE_MST_FD_CyclicRedundancyCheck13Value";
CM_ SG_ 2214592684 L_UWB_BLE_MST_FD_AlvCnt13Val "L_UWB_BLE_MST_FD_AliveCounter13Value";
CM_ SG_ 2214592684 MST_To_BDC_Loc_Enc_Data2 "Encryption Data(Localization) From BLE to BDC";
CM_ BO_ 2214592683 "[PE] Periodic and On Event";
CM_ SG_ 2214592683 L_UWB_BLE_MST_FD_Crc12Val "L_UWB_BLE_MST_FD_CyclicRedundancyCheck12Value";
CM_ SG_ 2214592683 L_UWB_BLE_MST_FD_AlvCnt12Val "L_UWB_BLE_MST_FD_AliveCounter12Value";
CM_ SG_ 2214592683 MST_To_BDC_Loc_Enc_Data1 "Encryption Data(Localization) From BLE to BDC";
CM_ BO_ 2214592682 "[EC] On Event and On Change";
CM_ SG_ 2214592682 L_UWB_BLE_MST_FD_Crc11Val "L_UWB_BLE_MST_FD_CyclicRedundancyCheck11Value";
CM_ SG_ 2214592682 L_UWB_BLE_MST_FD_AlvCnt11Val "L_UWB_BLE_MST_FD_AliveCounter11Value";
CM_ SG_ 2214592682 MST_BLE_To_BDC_Enc_Data2 "Encryption Data From Master_BLE to BDC";
CM_ BO_ 2214592681 "[EC] On Event and On Change";
CM_ SG_ 2214592681 L_UWB_BLE_MST_FD_Crc10Val "L_UWB_BLE_MST_FD_CyclicRedundancyCheck10Value";
CM_ SG_ 2214592681 L_UWB_BLE_MST_FD_AlvCnt10Val "L_UWB_BLE_MST_FD_AliveCounter10Value";
CM_ SG_ 2214592681 MST_BLE_To_BDC_Enc_Data1 "Encryption Data From Master_BLE to BDC";
CM_ BO_ 2214592680 "[EC] On Event and On Change";
CM_ SG_ 2214592680 L_UWB_BLE_MST_FD_Crc9Val "L_UWB_BLE_MST_FD_CyclicRedundancyCheck9Value";
CM_ SG_ 2214592680 L_UWB_BLE_MST_FD_AlvCnt9Val "L_UWB_BLE_MST_FD_AliveCounter9Value";
CM_ SG_ 2214592680 MST_To_UWB_Enc_Data5 "Encryption Data From Master to Slave and UWB ALL";
CM_ BO_ 2214592679 "[EC] On Event and On Change";
CM_ SG_ 2214592679 L_UWB_BLE_MST_FD_Crc8Val "L_UWB_BLE_MST_FD_CyclicRedundancyCheck8Value";
CM_ SG_ 2214592679 L_UWB_BLE_MST_FD_AlvCnt8Val "L_UWB_BLE_MST_FD_AliveCounter8Value";
CM_ SG_ 2214592679 MST_To_UWB_Enc_Data4 "Encryption Data From Master to Slave and UWB ALL";
CM_ BO_ 2214592678 "[EC] On Event and On Change";
CM_ SG_ 2214592678 L_UWB_BLE_MST_FD_Crc7Val "L_UWB_BLE_MST_FD_CyclicRedundancyCheck7Value";
CM_ SG_ 2214592678 L_UWB_BLE_MST_FD_AlvCnt7Val "L_UWB_BLE_MST_FD_AliveCounter7Value";
CM_ SG_ 2214592678 MST_To_UWB_Enc_Data3 "Encryption Data From Master to Slave and UWB ALL";
CM_ BO_ 2529538817 "[EW] On Event and On Write";
CM_ SG_ 2529538817 L_UWB_RL_FD_Crc7Val "L_UWB_RL_FD_CyclicRedundancyCheck7Value";
CM_ SG_ 2529538817 L_UWB_RL_FD_AlvCnt7Val "L_UWB_RL_FD_AliveCounter7Value";
CM_ SG_ 2529538817 RL_SWID_4_IVD_2 "UWB RL SW Unit 4 IVD2";
CM_ BO_ 2214592677 "[EC] On Event and On Change";
CM_ SG_ 2214592677 L_UWB_BLE_MST_FD_Crc6Val "L_UWB_BLE_MST_FD_CyclicRedundancyCheck6Value";
CM_ SG_ 2214592677 L_UWB_BLE_MST_FD_AlvCnt6Val "L_UWB_BLE_MST_FD_AliveCounter6Value";
CM_ SG_ 2214592677 MST_To_UWB_Enc_Data2 "Encryption Data From Master to Slave and UWB ALL";
CM_ BO_ 2214592676 "[EC] On Event and On Change";
CM_ SG_ 2214592676 L_UWB_BLE_MST_FD_Crc5Val "L_UWB_BLE_MST_FD_CyclicRedundancyCheck5Value";
CM_ SG_ 2214592676 L_UWB_BLE_MST_FD_AlvCnt5Val "L_UWB_BLE_MST_FD_AliveCounter5Value";
CM_ SG_ 2214592676 MST_To_UWB_Enc_Data1 "Encryption Data From Master to Slave and UWB ALL";
CM_ BO_ 2533737217 "[EW] On Event and On Write";
CM_ SG_ 2533737217 L_UWB_TRNK_FD_Crc7Val "L_UWB_TRNK_FD_CyclicRedundancyCheck7Value";
CM_ SG_ 2533737217 L_UWB_TRNK_FD_AlvCnt7Val "L_UWB_TRNK_FD_AliveCounter7Value";
CM_ SG_ 2533737217 TRNK_SWID_4_IVD_2 "UWB TRNK SW Unit 4 IVD2";
CM_ BO_ 2214592675 "[EC] On Event and On Change";
CM_ SG_ 2214592675 L_UWB_BLE_MST_FD_Crc4Val "L_UWB_BLE_MST_FD_CyclicRedundancyCheck4Value";
CM_ SG_ 2214592675 L_UWB_BLE_MST_FD_AlvCnt4Val "L_UWB_BLE_MST_FD_AliveCounter4Value";
CM_ SG_ 2214592675 MST_RndNum_Trgt "Local Random Number Target Define";
CM_ SG_ 2214592675 MST_RndNum_TRCode "Local Random Number TRCode";
CM_ SG_ 2214592675 MST_RndNum_Cmd "Local Random Number CMD";
CM_ SG_ 2214592675 MST_RndNum "Random Number for Encyption to IAU Local CAN Modules";
CM_ BO_ 2214592674 "[EW] On Event and On Write";
CM_ SG_ 2214592674 L_UWB_BLE_MST_FD_Crc3Val "L_UWB_BLE_MST_FD_CyclicRedundancyCheck3Value";
CM_ SG_ 2214592674 L_UWB_BLE_MST_FD_AlvCnt3Val "L_UWB_BLE_MST_FD_AliveCounter3Value";
CM_ SG_ 2214592674 MST_UWB_Ranging_Enc_Result2 "UWB Ranging Result2(Encrypted Data) with DK";
CM_ SG_ 2214592674 MST_UWB_Ranging_Enc_Result "UWB Ranging Result with DK";
CM_ BO_ 2214592673 "[EC] On Event and On Change";
CM_ SG_ 2214592673 L_UWB_BLE_MST_FD_Crc2Val "L_UWB_BLE_MST_FD_CyclicRedundancyCheck2Value";
CM_ SG_ 2214592673 L_UWB_BLE_MST_FD_AlvCnt2Val "L_UWB_BLE_MST_FD_AliveCounter2Value";
CM_ SG_ 2214592673 MST_UWB_FOB_RSD_Enc_Result "UWB Ranging Result with FOB";
CM_ BO_ 2214592672 "[EC] On Event and On Change";
CM_ SG_ 2214592672 L_UWB_BLE_MST_FD_Crc1Val "L_UWB_BLE_MST_FD_CyclicRedundancyCheck1Value";
CM_ SG_ 2214592672 L_UWB_BLE_MST_FD_AlvCnt1Val "L_UWB_BLE_MST_FD_AliveCounter1Value";
CM_ SG_ 2214592672 MST_BLE_Decrypt_FB "Decryption Feed back for BLE  (to BDC)";
CM_ SG_ 2214592672 MST_UWB_Decrypt_FB "Decryption Feed back for UWB (to BDC)";
CM_ SG_ 2214592672 MST_SLV_Decrypt_FB "UWB Master Decryption Feed Back";
CM_ SG_ 2214592672 MST_OTA_Status "UWB_BLE_Master OTA Status";
CM_ SG_ 2214592672 MST_UWB_IC_Status "UWB IC Status Message";
CM_ BO_ 2525342465 "[EW] On Event and On Write";
CM_ SG_ 2525342465 L_UWB_FR_FD_Crc7Val "L_UWB_FR_FD_CyclicRedundancyCheck7Value";
CM_ SG_ 2525342465 L_UWB_FR_FD_AlvCnt7Val "L_UWB_FR_FD_AliveCounter7Value";
CM_ SG_ 2525342465 FR_SWID_4_IVD_2 "UWB FR SW Unit 4 IVD2";
CM_ BO_ 829 "[PE] Periodic and On Event";
CM_ SG_ 829 SBCM_RR_FD_Crc1Val "SBCM_RR_FD_CyclicRedundancyCheck1Value";
CM_ SG_ 829 SBCM_RR_FD_AlvCnt1Val "SBCM_RR_FD_AliveCounter1Value";
CM_ SG_ 829 RR_CrashUnlockCmd_Copy_0 "Rear Right Crash Unlock Command";
CM_ SG_ 829 Warn_RrRtDrSwSta_SBCM_Copy_0 "Warn_RearRightDoorSwitchStatus ##2G## -  - C_RRDrSw,CF_Gway_RRDrSw,Warn_RrRtDrSwSta";
CM_ SG_ 829 DoorLock_RrRtDrUnLkSta_SBCM_Copy "DoorLock_RearRightDoorUnLockStatus ##2G## -  - C_RRUnlockState,DoorLock_RrRtDrUnLkSta";
CM_ SG_ 829 RR_SEAActivated_Copy_0 "Rear Right SEA Activated";
CM_ SG_ 829 RR_SEAWarn_Copy_0 "Rear Righr SEA Warning";
BA_DEF_ BO_  "CANFD_BRS" ENUM  "0","1";
BA_DEF_ BO_  "GenMsgEVName" STRING ;
BA_DEF_ BO_  "NmAsrMessage" ENUM  "No","Yes";
BA_DEF_ BO_  "DiagState" ENUM  "No","Yes";
BA_DEF_ BO_  "DiagResponse" ENUM  "No","Yes";
BA_DEF_ BO_  "DiagRequest" ENUM  "No","Yes";
BA_DEF_ BO_  "TpMessage" ENUM  "No","Yes";
BA_DEF_ BO_  "UsrMsgIDSforwardDeviation" INT 0 100;
BA_DEF_ BO_  "UsrMsgIDSbackwardDeviation" INT 50 1000;
BA_DEF_ BO_  "GenMsgCycleTime" INT 0 2000;
BA_DEF_ BO_  "GenMsgStartDelayTime" INT 0 2000;
BA_DEF_ BO_  "GenMsgSendType" ENUM  "Cyclic","NoMsgSendType";
BA_DEF_ BO_  "GenMsgCycleTimeFast" INT 0 500;
BA_DEF_ BO_  "GenMsgDelayTime" INT 0 20;
BA_DEF_ BO_  "GenMsgILSupport" ENUM  "No","Yes";
BA_DEF_ BO_  "GenMsgNrOfRepetition" INT 0 3;
BA_DEF_ BO_  "TpTxIndex" INT 0 65535;
BA_DEF_ BO_  "VFrameFormat" ENUM  "StandardCAN","ExtendedCAN","reserved","reserved","reserved","reserved","reserved","reserved","reserved","reserved","reserved","reserved","reserved","reserved","StandardCAN_FD","ExtendedCAN_FD";
BA_DEF_ SG_  "UserSigValidity" ENUM  "B+","ACC","IG","IG1","IG2","IG3","IG1 or IG2","IG1 or IG3","Undef";
BA_DEF_ SG_  "TimeoutValue" STRING ;
BA_DEF_ SG_  "UsrSigPurpose" ENUM  "Undef","FN","DIAG","DIAG(Req)","DIAG(Res)","DIAG(Func)","DEV","CCP","NM","TP";
BA_DEF_ SG_  "GenSigStartValue" INT 0 1215752192;
BA_DEF_ SG_  "NetworkRequest" ENUM  "Yes","No";
BA_DEF_ SG_  "NetworkRequestHoldingTime" INT 0 65535;
BA_DEF_ SG_  "Description" STRING ;
BA_DEF_ SG_  "Version" STRING ;
BA_DEF_ SG_  "GenSigEnvVarType" ENUM  "Int","Float","Undef";
BA_DEF_ SG_  "GenSigSendType" ENUM  "Cyclic","OnWrite","OnWriteWithRepetition","OnChange","OnChangeWithRepetition","IfActive","IfActiveWithRepetition","NoSigSendType","OnChangeAndIfActive","OnChangeAndIfActiveWithRepetition";
BA_DEF_ SG_  "GwSigLatencyTime" INT 0 65536;
BA_DEF_ SG_  "GwSigMissingSourceType" ENUM  "Undef","OldValue","DefaultValue","InitialValue";
BA_DEF_ SG_  "NWM-WakeupAllowed" ENUM  "<n.a.>";
BA_DEF_ SG_  "RoutingFactor" INT 1 1215752192;
BA_DEF_ SG_  "SystemSignalLongSymbol" STRING ;
BA_DEF_REL_ BU_SG_REL_  "GenSigTimeoutTime" INT 0 7000;
BA_DEF_DEF_  "CANFD_BRS" "1";
BA_DEF_DEF_  "GenMsgEVName" "@Signame";
BA_DEF_DEF_  "NmAsrMessage" "No";
BA_DEF_DEF_  "DiagState" "No";
BA_DEF_DEF_  "DiagResponse" "No";
BA_DEF_DEF_  "DiagRequest" "No";
BA_DEF_DEF_  "TpMessage" "No";
BA_DEF_DEF_  "UsrMsgIDSforwardDeviation" 10;
BA_DEF_DEF_  "UsrMsgIDSbackwardDeviation" 100;
BA_DEF_DEF_  "GenMsgCycleTime" 200;
BA_DEF_DEF_  "GenMsgStartDelayTime" 0;
BA_DEF_DEF_  "GenMsgSendType" "NoMsgSendType";
BA_DEF_DEF_  "GenMsgCycleTimeFast" 40;
BA_DEF_DEF_  "GenMsgDelayTime" 20;
BA_DEF_DEF_  "GenMsgILSupport" "Yes";
BA_DEF_DEF_  "GenMsgNrOfRepetition" 3;
BA_DEF_DEF_  "TpTxIndex" 0;
BA_DEF_DEF_  "VFrameFormat" "StandardCAN";
BA_DEF_DEF_  "UserSigValidity" "IG";
BA_DEF_DEF_  "TimeoutValue" "";
BA_DEF_DEF_  "UsrSigPurpose" "FN";
BA_DEF_DEF_  "GenSigStartValue" 0;
BA_DEF_DEF_  "NetworkRequest" "No";
BA_DEF_DEF_  "NetworkRequestHoldingTime" 0;
BA_DEF_DEF_  "Description" "";
BA_DEF_DEF_  "Version" "";
BA_DEF_DEF_  "GenSigEnvVarType" "Undef";
BA_DEF_DEF_  "GenSigSendType" "NoSigSendType";
BA_DEF_DEF_  "GwSigLatencyTime" 40;
BA_DEF_DEF_  "GwSigMissingSourceType" "Undef";
BA_DEF_DEF_  "NWM-WakeupAllowed" "<n.a.>";
BA_DEF_DEF_  "RoutingFactor" 1;
BA_DEF_DEF_REL_ "GenSigTimeoutTime" 500;
BA_DEF_DEF_  "SystemSignalLongSymbol" "";
BA_ "TpTxIndex" BO_ 2348810498 271;
BA_ "TpMessage" BO_ 2348810498 1;
BA_ "GenMsgILSupport" BO_ 2348810498 0;
BA_ "GenMsgNrOfRepetition" BO_ 2348810498 0;
BA_ "GenMsgCycleTimeFast" BO_ 2348810498 0;
BA_ "GenMsgCycleTime" BO_ 2348810498 0;
BA_ "VFrameFormat" BO_ 2348810498 15;
BA_ "GenMsgCycleTime" BO_ 2214592657 0;
BA_ "VFrameFormat" BO_ 2214592657 15;
BA_ "TpTxIndex" BO_ 2348810497 270;
BA_ "TpMessage" BO_ 2348810497 1;
BA_ "GenMsgILSupport" BO_ 2348810497 0;
BA_ "GenMsgNrOfRepetition" BO_ 2348810497 0;
BA_ "GenMsgCycleTimeFast" BO_ 2348810497 0;
BA_ "GenMsgCycleTime" BO_ 2348810497 0;
BA_ "VFrameFormat" BO_ 2348810497 15;
BA_ "TpTxIndex" BO_ 2348810496 270;
BA_ "TpMessage" BO_ 2348810496 1;
BA_ "GenMsgILSupport" BO_ 2348810496 0;
BA_ "GenMsgNrOfRepetition" BO_ 2348810496 0;
BA_ "GenMsgCycleTimeFast" BO_ 2348810496 0;
BA_ "GenMsgCycleTime" BO_ 2348810496 0;
BA_ "VFrameFormat" BO_ 2348810496 15;
BA_ "GenMsgDelayTime" BO_ 2214592645 10;
BA_ "GenMsgCycleTime" BO_ 2214592645 0;
BA_ "VFrameFormat" BO_ 2214592645 15;
BA_ "GenMsgDelayTime" BO_ 2214592644 10;
BA_ "GenMsgCycleTime" BO_ 2214592644 0;
BA_ "VFrameFormat" BO_ 2214592644 15;
BA_ "GenMsgCycleTime" BO_ 2214592641 0;
BA_ "VFrameFormat" BO_ 2214592641 15;
BA_ "GenMsgCycleTime" BO_ 2214592640 0;
BA_ "VFrameFormat" BO_ 2214592640 15;
BA_ "GenMsgDelayTime" BO_ 2529538305 10;
BA_ "GenMsgCycleTime" BO_ 2529538305 0;
BA_ "VFrameFormat" BO_ 2529538305 15;
BA_ "GenMsgDelayTime" BO_ 2533736705 10;
BA_ "GenMsgCycleTime" BO_ 2533736705 0;
BA_ "VFrameFormat" BO_ 2533736705 15;
BA_ "GenMsgDelayTime" BO_ 2214592703 10;
BA_ "GenMsgCycleTime" BO_ 2214592703 0;
BA_ "VFrameFormat" BO_ 2214592703 15;
BA_ "GenMsgDelayTime" BO_ 2214592698 10;
BA_ "GenMsgCycleTime" BO_ 2214592698 0;
BA_ "VFrameFormat" BO_ 2214592698 15;
BA_ "GenMsgDelayTime" BO_ 2214592699 10;
BA_ "GenMsgCycleTime" BO_ 2214592699 0;
BA_ "VFrameFormat" BO_ 2214592699 15;
BA_ "GenMsgCycleTime" BO_ 2214592694 0;
BA_ "VFrameFormat" BO_ 2214592694 15;
BA_ "GenMsgCycleTime" BO_ 2214592695 0;
BA_ "VFrameFormat" BO_ 2214592695 15;
BA_ "GenMsgCycleTime" BO_ 2214592692 0;
BA_ "VFrameFormat" BO_ 2214592692 15;
BA_ "GenMsgCycleTime" BO_ 2214592693 0;
BA_ "VFrameFormat" BO_ 2214592693 15;
BA_ "GenMsgDelayTime" BO_ 2214592690 10;
BA_ "GenMsgCycleTime" BO_ 2214592690 0;
BA_ "VFrameFormat" BO_ 2214592690 15;
BA_ "GenMsgCycleTime" BO_ 2214592691 0;
BA_ "VFrameFormat" BO_ 2214592691 15;
BA_ "GenMsgCycleTime" BO_ 2214592688 0;
BA_ "VFrameFormat" BO_ 2214592688 15;
BA_ "GenMsgCycleTime" BO_ 2214592689 0;
BA_ "VFrameFormat" BO_ 2214592689 15;
BA_ "GenMsgDelayTime" BO_ 2214592687 10;
BA_ "GenMsgCycleTime" BO_ 2214592687 0;
BA_ "VFrameFormat" BO_ 2214592687 15;
BA_ "GenMsgCycleTime" BO_ 2214592686 0;
BA_ "VFrameFormat" BO_ 2214592686 15;
BA_ "GenMsgCycleTime" BO_ 2214592685 0;
BA_ "VFrameFormat" BO_ 2214592685 15;
BA_ "GenMsgSendType" BO_ 2214592684 0;
BA_ "VFrameFormat" BO_ 2214592684 15;
BA_ "GenMsgSendType" BO_ 2214592683 0;
BA_ "VFrameFormat" BO_ 2214592683 15;
BA_ "GenMsgCycleTime" BO_ 2214592682 0;
BA_ "VFrameFormat" BO_ 2214592682 15;
BA_ "GenMsgCycleTime" BO_ 2214592681 0;
BA_ "VFrameFormat" BO_ 2214592681 15;
BA_ "GenMsgCycleTime" BO_ 2214592680 0;
BA_ "VFrameFormat" BO_ 2214592680 15;
BA_ "GenMsgCycleTime" BO_ 2214592679 0;
BA_ "VFrameFormat" BO_ 2214592679 15;
BA_ "GenMsgCycleTime" BO_ 2214592678 0;
BA_ "VFrameFormat" BO_ 2214592678 15;
BA_ "GenMsgDelayTime" BO_ 2529538817 10;
BA_ "GenMsgCycleTime" BO_ 2529538817 0;
BA_ "VFrameFormat" BO_ 2529538817 15;
BA_ "GenMsgCycleTime" BO_ 2214592677 0;
BA_ "VFrameFormat" BO_ 2214592677 15;
BA_ "GenMsgCycleTime" BO_ 2214592676 0;
BA_ "VFrameFormat" BO_ 2214592676 15;
BA_ "GenMsgDelayTime" BO_ 2533737217 10;
BA_ "GenMsgCycleTime" BO_ 2533737217 0;
BA_ "VFrameFormat" BO_ 2533737217 15;
BA_ "GenMsgCycleTime" BO_ 2214592675 0;
BA_ "VFrameFormat" BO_ 2214592675 15;
BA_ "GenMsgDelayTime" BO_ 2214592674 10;
BA_ "GenMsgCycleTime" BO_ 2214592674 0;
BA_ "VFrameFormat" BO_ 2214592674 15;
BA_ "GenMsgCycleTime" BO_ 2214592673 0;
BA_ "VFrameFormat" BO_ 2214592673 15;
BA_ "GenMsgCycleTime" BO_ 2214592672 0;
BA_ "VFrameFormat" BO_ 2214592672 15;
BA_ "GenMsgDelayTime" BO_ 2525342465 10;
BA_ "GenMsgCycleTime" BO_ 2525342465 0;
BA_ "VFrameFormat" BO_ 2525342465 15;
BA_ "GenMsgSendType" BO_ 829 0;
BA_ "VFrameFormat" BO_ 829 14;
BA_ "Version" SG_ 2348810498 L_TP_BDC_FD_L_UWB_BLE_SLV_FD_Byt "23.01.02";
BA_ "NetworkRequestHoldingTime" SG_ 2348810498 L_TP_BDC_FD_L_UWB_BLE_SLV_FD_Byt 5000;
BA_ "NetworkRequest" SG_ 2348810498 L_TP_BDC_FD_L_UWB_BLE_SLV_FD_Byt 0;
BA_ "UserSigValidity" SG_ 2348810498 L_TP_BDC_FD_L_UWB_BLE_SLV_FD_Byt 0;
BA_ "UsrSigPurpose" SG_ 2348810498 L_TP_BDC_FD_L_UWB_BLE_SLV_FD_Byt 9;
BA_ "Description" SG_ 2348810498 L_TP_BDC_FD_L_UWB_BLE_SLV_FD_Byt "TP Index : 271";
BA_ "SystemSignalLongSymbol" SG_ 2348810498 L_TP_BDC_FD_L_UWB_BLE_SLV_FD_Byt "L_TP_BDC_FD_L_UWB_BLE_SLV_FD_Byte0";
BA_ "Version" SG_ 2348810498 L_TP_BDC_FD_L_UWB_BLE_SLV_F_0000 "23.01.02";
BA_ "NetworkRequestHoldingTime" SG_ 2348810498 L_TP_BDC_FD_L_UWB_BLE_SLV_F_0000 5000;
BA_ "NetworkRequest" SG_ 2348810498 L_TP_BDC_FD_L_UWB_BLE_SLV_F_0000 0;
BA_ "UserSigValidity" SG_ 2348810498 L_TP_BDC_FD_L_UWB_BLE_SLV_F_0000 0;
BA_ "UsrSigPurpose" SG_ 2348810498 L_TP_BDC_FD_L_UWB_BLE_SLV_F_0000 9;
BA_ "Description" SG_ 2348810498 L_TP_BDC_FD_L_UWB_BLE_SLV_F_0000 "TP Index : 271";
BA_ "SystemSignalLongSymbol" SG_ 2348810498 L_TP_BDC_FD_L_UWB_BLE_SLV_F_0000 "L_TP_BDC_FD_L_UWB_BLE_SLV_FD_Byte13";
BA_ "Version" SG_ 2348810498 L_TP_BDC_FD_L_UWB_BLE_SLV_F_0001 "23.01.02";
BA_ "NetworkRequestHoldingTime" SG_ 2348810498 L_TP_BDC_FD_L_UWB_BLE_SLV_F_0001 5000;
BA_ "NetworkRequest" SG_ 2348810498 L_TP_BDC_FD_L_UWB_BLE_SLV_F_0001 0;
BA_ "UserSigValidity" SG_ 2348810498 L_TP_BDC_FD_L_UWB_BLE_SLV_F_0001 0;
BA_ "UsrSigPurpose" SG_ 2348810498 L_TP_BDC_FD_L_UWB_BLE_SLV_F_0001 9;
BA_ "Description" SG_ 2348810498 L_TP_BDC_FD_L_UWB_BLE_SLV_F_0001 "TP Index : 271";
BA_ "SystemSignalLongSymbol" SG_ 2348810498 L_TP_BDC_FD_L_UWB_BLE_SLV_F_0001 "L_TP_BDC_FD_L_UWB_BLE_SLV_FD_Byte14";
BA_ "Version" SG_ 2348810498 L_TP_BDC_FD_L_UWB_BLE_SLV_F_0002 "23.01.02";
BA_ "NetworkRequestHoldingTime" SG_ 2348810498 L_TP_BDC_FD_L_UWB_BLE_SLV_F_0002 5000;
BA_ "NetworkRequest" SG_ 2348810498 L_TP_BDC_FD_L_UWB_BLE_SLV_F_0002 0;
BA_ "UserSigValidity" SG_ 2348810498 L_TP_BDC_FD_L_UWB_BLE_SLV_F_0002 0;
BA_ "UsrSigPurpose" SG_ 2348810498 L_TP_BDC_FD_L_UWB_BLE_SLV_F_0002 9;
BA_ "Description" SG_ 2348810498 L_TP_BDC_FD_L_UWB_BLE_SLV_F_0002 "TP Index : 271";
BA_ "SystemSignalLongSymbol" SG_ 2348810498 L_TP_BDC_FD_L_UWB_BLE_SLV_F_0002 "L_TP_BDC_FD_L_UWB_BLE_SLV_FD_Byte15";
BA_ "Version" SG_ 2348810498 L_TP_BDC_FD_L_UWB_BLE_SLV_F_0003 "23.01.02";
BA_ "NetworkRequestHoldingTime" SG_ 2348810498 L_TP_BDC_FD_L_UWB_BLE_SLV_F_0003 5000;
BA_ "NetworkRequest" SG_ 2348810498 L_TP_BDC_FD_L_UWB_BLE_SLV_F_0003 0;
BA_ "UserSigValidity" SG_ 2348810498 L_TP_BDC_FD_L_UWB_BLE_SLV_F_0003 0;
BA_ "UsrSigPurpose" SG_ 2348810498 L_TP_BDC_FD_L_UWB_BLE_SLV_F_0003 9;
BA_ "Description" SG_ 2348810498 L_TP_BDC_FD_L_UWB_BLE_SLV_F_0003 "TP Index : 271";
BA_ "SystemSignalLongSymbol" SG_ 2348810498 L_TP_BDC_FD_L_UWB_BLE_SLV_F_0003 "L_TP_BDC_FD_L_UWB_BLE_SLV_FD_Byte16";
BA_ "Version" SG_ 2348810498 L_TP_BDC_FD_L_UWB_BLE_SLV_F_0004 "23.01.02";
BA_ "NetworkRequestHoldingTime" SG_ 2348810498 L_TP_BDC_FD_L_UWB_BLE_SLV_F_0004 5000;
BA_ "NetworkRequest" SG_ 2348810498 L_TP_BDC_FD_L_UWB_BLE_SLV_F_0004 0;
BA_ "UserSigValidity" SG_ 2348810498 L_TP_BDC_FD_L_UWB_BLE_SLV_F_0004 0;
BA_ "UsrSigPurpose" SG_ 2348810498 L_TP_BDC_FD_L_UWB_BLE_SLV_F_0004 9;
BA_ "Description" SG_ 2348810498 L_TP_BDC_FD_L_UWB_BLE_SLV_F_0004 "TP Index : 271";
BA_ "SystemSignalLongSymbol" SG_ 2348810498 L_TP_BDC_FD_L_UWB_BLE_SLV_F_0004 "L_TP_BDC_FD_L_UWB_BLE_SLV_FD_Byte17";
BA_ "Version" SG_ 2348810498 L_TP_BDC_FD_L_UWB_BLE_SLV_F_0005 "23.01.02";
BA_ "NetworkRequestHoldingTime" SG_ 2348810498 L_TP_BDC_FD_L_UWB_BLE_SLV_F_0005 5000;
BA_ "NetworkRequest" SG_ 2348810498 L_TP_BDC_FD_L_UWB_BLE_SLV_F_0005 0;
BA_ "UserSigValidity" SG_ 2348810498 L_TP_BDC_FD_L_UWB_BLE_SLV_F_0005 0;
BA_ "UsrSigPurpose" SG_ 2348810498 L_TP_BDC_FD_L_UWB_BLE_SLV_F_0005 9;
BA_ "Description" SG_ 2348810498 L_TP_BDC_FD_L_UWB_BLE_SLV_F_0005 "TP Index : 271";
BA_ "SystemSignalLongSymbol" SG_ 2348810498 L_TP_BDC_FD_L_UWB_BLE_SLV_F_0005 "L_TP_BDC_FD_L_UWB_BLE_SLV_FD_Byte18";
BA_ "Version" SG_ 2348810498 L_TP_BDC_FD_L_UWB_BLE_SLV_F_0006 "23.01.02";
BA_ "NetworkRequestHoldingTime" SG_ 2348810498 L_TP_BDC_FD_L_UWB_BLE_SLV_F_0006 5000;
BA_ "NetworkRequest" SG_ 2348810498 L_TP_BDC_FD_L_UWB_BLE_SLV_F_0006 0;
BA_ "UserSigValidity" SG_ 2348810498 L_TP_BDC_FD_L_UWB_BLE_SLV_F_0006 0;
BA_ "UsrSigPurpose" SG_ 2348810498 L_TP_BDC_FD_L_UWB_BLE_SLV_F_0006 9;
BA_ "Description" SG_ 2348810498 L_TP_BDC_FD_L_UWB_BLE_SLV_F_0006 "TP Index : 271";
BA_ "SystemSignalLongSymbol" SG_ 2348810498 L_TP_BDC_FD_L_UWB_BLE_SLV_F_0006 "L_TP_BDC_FD_L_UWB_BLE_SLV_FD_Byte19";
BA_ "Version" SG_ 2348810498 L_TP_BDC_FD_L_UWB_BLE_SLV_F_0007 "23.01.02";
BA_ "NetworkRequestHoldingTime" SG_ 2348810498 L_TP_BDC_FD_L_UWB_BLE_SLV_F_0007 5000;
BA_ "NetworkRequest" SG_ 2348810498 L_TP_BDC_FD_L_UWB_BLE_SLV_F_0007 0;
BA_ "UserSigValidity" SG_ 2348810498 L_TP_BDC_FD_L_UWB_BLE_SLV_F_0007 0;
BA_ "UsrSigPurpose" SG_ 2348810498 L_TP_BDC_FD_L_UWB_BLE_SLV_F_0007 9;
BA_ "Description" SG_ 2348810498 L_TP_BDC_FD_L_UWB_BLE_SLV_F_0007 "TP Index : 271";
BA_ "SystemSignalLongSymbol" SG_ 2348810498 L_TP_BDC_FD_L_UWB_BLE_SLV_F_0007 "L_TP_BDC_FD_L_UWB_BLE_SLV_FD_Byte2";
BA_ "Version" SG_ 2348810498 L_TP_BDC_FD_L_UWB_BLE_SLV_F_0008 "23.01.02";
BA_ "NetworkRequestHoldingTime" SG_ 2348810498 L_TP_BDC_FD_L_UWB_BLE_SLV_F_0008 5000;
BA_ "NetworkRequest" SG_ 2348810498 L_TP_BDC_FD_L_UWB_BLE_SLV_F_0008 0;
BA_ "UserSigValidity" SG_ 2348810498 L_TP_BDC_FD_L_UWB_BLE_SLV_F_0008 0;
BA_ "UsrSigPurpose" SG_ 2348810498 L_TP_BDC_FD_L_UWB_BLE_SLV_F_0008 9;
BA_ "Description" SG_ 2348810498 L_TP_BDC_FD_L_UWB_BLE_SLV_F_0008 "TP Index : 271";
BA_ "SystemSignalLongSymbol" SG_ 2348810498 L_TP_BDC_FD_L_UWB_BLE_SLV_F_0008 "L_TP_BDC_FD_L_UWB_BLE_SLV_FD_Byte20";
BA_ "Version" SG_ 2348810498 L_TP_BDC_FD_L_UWB_BLE_SLV_F_0009 "23.01.02";
BA_ "NetworkRequestHoldingTime" SG_ 2348810498 L_TP_BDC_FD_L_UWB_BLE_SLV_F_0009 5000;
BA_ "NetworkRequest" SG_ 2348810498 L_TP_BDC_FD_L_UWB_BLE_SLV_F_0009 0;
BA_ "UserSigValidity" SG_ 2348810498 L_TP_BDC_FD_L_UWB_BLE_SLV_F_0009 0;
BA_ "UsrSigPurpose" SG_ 2348810498 L_TP_BDC_FD_L_UWB_BLE_SLV_F_0009 9;
BA_ "Description" SG_ 2348810498 L_TP_BDC_FD_L_UWB_BLE_SLV_F_0009 "TP Index : 271";
BA_ "SystemSignalLongSymbol" SG_ 2348810498 L_TP_BDC_FD_L_UWB_BLE_SLV_F_0009 "L_TP_BDC_FD_L_UWB_BLE_SLV_FD_Byte21";
BA_ "Version" SG_ 2348810498 L_TP_BDC_FD_L_UWB_BLE_SLV_F_0010 "23.01.02";
BA_ "NetworkRequestHoldingTime" SG_ 2348810498 L_TP_BDC_FD_L_UWB_BLE_SLV_F_0010 5000;
BA_ "NetworkRequest" SG_ 2348810498 L_TP_BDC_FD_L_UWB_BLE_SLV_F_0010 0;
BA_ "UserSigValidity" SG_ 2348810498 L_TP_BDC_FD_L_UWB_BLE_SLV_F_0010 0;
BA_ "UsrSigPurpose" SG_ 2348810498 L_TP_BDC_FD_L_UWB_BLE_SLV_F_0010 9;
BA_ "Description" SG_ 2348810498 L_TP_BDC_FD_L_UWB_BLE_SLV_F_0010 "TP Index : 271";
BA_ "SystemSignalLongSymbol" SG_ 2348810498 L_TP_BDC_FD_L_UWB_BLE_SLV_F_0010 "L_TP_BDC_FD_L_UWB_BLE_SLV_FD_Byte22";
BA_ "Version" SG_ 2348810498 L_TP_BDC_FD_L_UWB_BLE_SLV_F_0011 "23.01.02";
BA_ "NetworkRequestHoldingTime" SG_ 2348810498 L_TP_BDC_FD_L_UWB_BLE_SLV_F_0011 5000;
BA_ "NetworkRequest" SG_ 2348810498 L_TP_BDC_FD_L_UWB_BLE_SLV_F_0011 0;
BA_ "UserSigValidity" SG_ 2348810498 L_TP_BDC_FD_L_UWB_BLE_SLV_F_0011 0;
BA_ "UsrSigPurpose" SG_ 2348810498 L_TP_BDC_FD_L_UWB_BLE_SLV_F_0011 9;
BA_ "Description" SG_ 2348810498 L_TP_BDC_FD_L_UWB_BLE_SLV_F_0011 "TP Index : 271";
BA_ "SystemSignalLongSymbol" SG_ 2348810498 L_TP_BDC_FD_L_UWB_BLE_SLV_F_0011 "L_TP_BDC_FD_L_UWB_BLE_SLV_FD_Byte23";
BA_ "Version" SG_ 2348810498 L_TP_BDC_FD_L_UWB_BLE_SLV_F_0012 "23.01.02";
BA_ "NetworkRequestHoldingTime" SG_ 2348810498 L_TP_BDC_FD_L_UWB_BLE_SLV_F_0012 5000;
BA_ "NetworkRequest" SG_ 2348810498 L_TP_BDC_FD_L_UWB_BLE_SLV_F_0012 0;
BA_ "UserSigValidity" SG_ 2348810498 L_TP_BDC_FD_L_UWB_BLE_SLV_F_0012 0;
BA_ "UsrSigPurpose" SG_ 2348810498 L_TP_BDC_FD_L_UWB_BLE_SLV_F_0012 9;
BA_ "Description" SG_ 2348810498 L_TP_BDC_FD_L_UWB_BLE_SLV_F_0012 "TP Index : 271";
BA_ "SystemSignalLongSymbol" SG_ 2348810498 L_TP_BDC_FD_L_UWB_BLE_SLV_F_0012 "L_TP_BDC_FD_L_UWB_BLE_SLV_FD_Byte24";
BA_ "Version" SG_ 2348810498 L_TP_BDC_FD_L_UWB_BLE_SLV_F_0013 "23.01.02";
BA_ "NetworkRequestHoldingTime" SG_ 2348810498 L_TP_BDC_FD_L_UWB_BLE_SLV_F_0013 5000;
BA_ "NetworkRequest" SG_ 2348810498 L_TP_BDC_FD_L_UWB_BLE_SLV_F_0013 0;
BA_ "UserSigValidity" SG_ 2348810498 L_TP_BDC_FD_L_UWB_BLE_SLV_F_0013 0;
BA_ "UsrSigPurpose" SG_ 2348810498 L_TP_BDC_FD_L_UWB_BLE_SLV_F_0013 9;
BA_ "Description" SG_ 2348810498 L_TP_BDC_FD_L_UWB_BLE_SLV_F_0013 "TP Index : 271";
BA_ "SystemSignalLongSymbol" SG_ 2348810498 L_TP_BDC_FD_L_UWB_BLE_SLV_F_0013 "L_TP_BDC_FD_L_UWB_BLE_SLV_FD_Byte25";
BA_ "Version" SG_ 2348810498 L_TP_BDC_FD_L_UWB_BLE_SLV_F_0014 "23.01.02";
BA_ "NetworkRequestHoldingTime" SG_ 2348810498 L_TP_BDC_FD_L_UWB_BLE_SLV_F_0014 5000;
BA_ "NetworkRequest" SG_ 2348810498 L_TP_BDC_FD_L_UWB_BLE_SLV_F_0014 0;
BA_ "UserSigValidity" SG_ 2348810498 L_TP_BDC_FD_L_UWB_BLE_SLV_F_0014 0;
BA_ "UsrSigPurpose" SG_ 2348810498 L_TP_BDC_FD_L_UWB_BLE_SLV_F_0014 9;
BA_ "Description" SG_ 2348810498 L_TP_BDC_FD_L_UWB_BLE_SLV_F_0014 "TP Index : 271";
BA_ "SystemSignalLongSymbol" SG_ 2348810498 L_TP_BDC_FD_L_UWB_BLE_SLV_F_0014 "L_TP_BDC_FD_L_UWB_BLE_SLV_FD_Byte26";
BA_ "Version" SG_ 2348810498 L_TP_BDC_FD_L_UWB_BLE_SLV_F_0015 "23.01.02";
BA_ "NetworkRequestHoldingTime" SG_ 2348810498 L_TP_BDC_FD_L_UWB_BLE_SLV_F_0015 5000;
BA_ "NetworkRequest" SG_ 2348810498 L_TP_BDC_FD_L_UWB_BLE_SLV_F_0015 0;
BA_ "UserSigValidity" SG_ 2348810498 L_TP_BDC_FD_L_UWB_BLE_SLV_F_0015 0;
BA_ "UsrSigPurpose" SG_ 2348810498 L_TP_BDC_FD_L_UWB_BLE_SLV_F_0015 9;
BA_ "Description" SG_ 2348810498 L_TP_BDC_FD_L_UWB_BLE_SLV_F_0015 "TP Index : 271";
BA_ "SystemSignalLongSymbol" SG_ 2348810498 L_TP_BDC_FD_L_UWB_BLE_SLV_F_0015 "L_TP_BDC_FD_L_UWB_BLE_SLV_FD_Byte27";
BA_ "Version" SG_ 2348810498 L_TP_BDC_FD_L_UWB_BLE_SLV_F_0016 "23.01.02";
BA_ "NetworkRequestHoldingTime" SG_ 2348810498 L_TP_BDC_FD_L_UWB_BLE_SLV_F_0016 5000;
BA_ "NetworkRequest" SG_ 2348810498 L_TP_BDC_FD_L_UWB_BLE_SLV_F_0016 0;
BA_ "UserSigValidity" SG_ 2348810498 L_TP_BDC_FD_L_UWB_BLE_SLV_F_0016 0;
BA_ "UsrSigPurpose" SG_ 2348810498 L_TP_BDC_FD_L_UWB_BLE_SLV_F_0016 9;
BA_ "Description" SG_ 2348810498 L_TP_BDC_FD_L_UWB_BLE_SLV_F_0016 "TP Index : 271";
BA_ "SystemSignalLongSymbol" SG_ 2348810498 L_TP_BDC_FD_L_UWB_BLE_SLV_F_0016 "L_TP_BDC_FD_L_UWB_BLE_SLV_FD_Byte28";
BA_ "Version" SG_ 2348810498 L_TP_BDC_FD_L_UWB_BLE_SLV_F_0017 "23.01.02";
BA_ "NetworkRequestHoldingTime" SG_ 2348810498 L_TP_BDC_FD_L_UWB_BLE_SLV_F_0017 5000;
BA_ "NetworkRequest" SG_ 2348810498 L_TP_BDC_FD_L_UWB_BLE_SLV_F_0017 0;
BA_ "UserSigValidity" SG_ 2348810498 L_TP_BDC_FD_L_UWB_BLE_SLV_F_0017 0;
BA_ "UsrSigPurpose" SG_ 2348810498 L_TP_BDC_FD_L_UWB_BLE_SLV_F_0017 9;
BA_ "Description" SG_ 2348810498 L_TP_BDC_FD_L_UWB_BLE_SLV_F_0017 "TP Index : 271";
BA_ "SystemSignalLongSymbol" SG_ 2348810498 L_TP_BDC_FD_L_UWB_BLE_SLV_F_0017 "L_TP_BDC_FD_L_UWB_BLE_SLV_FD_Byte29";
BA_ "Version" SG_ 2348810498 L_TP_BDC_FD_L_UWB_BLE_SLV_F_0018 "23.01.02";
BA_ "NetworkRequestHoldingTime" SG_ 2348810498 L_TP_BDC_FD_L_UWB_BLE_SLV_F_0018 5000;
BA_ "NetworkRequest" SG_ 2348810498 L_TP_BDC_FD_L_UWB_BLE_SLV_F_0018 0;
BA_ "UserSigValidity" SG_ 2348810498 L_TP_BDC_FD_L_UWB_BLE_SLV_F_0018 0;
BA_ "UsrSigPurpose" SG_ 2348810498 L_TP_BDC_FD_L_UWB_BLE_SLV_F_0018 9;
BA_ "Description" SG_ 2348810498 L_TP_BDC_FD_L_UWB_BLE_SLV_F_0018 "TP Index : 271";
BA_ "SystemSignalLongSymbol" SG_ 2348810498 L_TP_BDC_FD_L_UWB_BLE_SLV_F_0018 "L_TP_BDC_FD_L_UWB_BLE_SLV_FD_Byte3";
BA_ "Version" SG_ 2348810498 L_TP_BDC_FD_L_UWB_BLE_SLV_F_0019 "23.01.02";
BA_ "NetworkRequestHoldingTime" SG_ 2348810498 L_TP_BDC_FD_L_UWB_BLE_SLV_F_0019 5000;
BA_ "NetworkRequest" SG_ 2348810498 L_TP_BDC_FD_L_UWB_BLE_SLV_F_0019 0;
BA_ "UserSigValidity" SG_ 2348810498 L_TP_BDC_FD_L_UWB_BLE_SLV_F_0019 0;
BA_ "UsrSigPurpose" SG_ 2348810498 L_TP_BDC_FD_L_UWB_BLE_SLV_F_0019 9;
BA_ "Description" SG_ 2348810498 L_TP_BDC_FD_L_UWB_BLE_SLV_F_0019 "TP Index : 271";
BA_ "SystemSignalLongSymbol" SG_ 2348810498 L_TP_BDC_FD_L_UWB_BLE_SLV_F_0019 "L_TP_BDC_FD_L_UWB_BLE_SLV_FD_Byte30";
BA_ "Version" SG_ 2348810498 L_TP_BDC_FD_L_UWB_BLE_SLV_F_0020 "23.01.02";
BA_ "NetworkRequestHoldingTime" SG_ 2348810498 L_TP_BDC_FD_L_UWB_BLE_SLV_F_0020 5000;
BA_ "NetworkRequest" SG_ 2348810498 L_TP_BDC_FD_L_UWB_BLE_SLV_F_0020 0;
BA_ "UserSigValidity" SG_ 2348810498 L_TP_BDC_FD_L_UWB_BLE_SLV_F_0020 0;
BA_ "UsrSigPurpose" SG_ 2348810498 L_TP_BDC_FD_L_UWB_BLE_SLV_F_0020 9;
BA_ "Description" SG_ 2348810498 L_TP_BDC_FD_L_UWB_BLE_SLV_F_0020 "TP Index : 271";
BA_ "SystemSignalLongSymbol" SG_ 2348810498 L_TP_BDC_FD_L_UWB_BLE_SLV_F_0020 "L_TP_BDC_FD_L_UWB_BLE_SLV_FD_Byte31";
BA_ "Version" SG_ 2348810498 L_TP_BDC_FD_L_UWB_BLE_SLV_F_0021 "23.01.02";
BA_ "NetworkRequestHoldingTime" SG_ 2348810498 L_TP_BDC_FD_L_UWB_BLE_SLV_F_0021 5000;
BA_ "NetworkRequest" SG_ 2348810498 L_TP_BDC_FD_L_UWB_BLE_SLV_F_0021 0;
BA_ "UserSigValidity" SG_ 2348810498 L_TP_BDC_FD_L_UWB_BLE_SLV_F_0021 0;
BA_ "UsrSigPurpose" SG_ 2348810498 L_TP_BDC_FD_L_UWB_BLE_SLV_F_0021 9;
BA_ "Description" SG_ 2348810498 L_TP_BDC_FD_L_UWB_BLE_SLV_F_0021 "TP Index : 271";
BA_ "SystemSignalLongSymbol" SG_ 2348810498 L_TP_BDC_FD_L_UWB_BLE_SLV_F_0021 "L_TP_BDC_FD_L_UWB_BLE_SLV_FD_Byte4";
BA_ "Version" SG_ 2348810498 L_TP_BDC_FD_L_UWB_BLE_SLV_F_0022 "23.01.02";
BA_ "NetworkRequestHoldingTime" SG_ 2348810498 L_TP_BDC_FD_L_UWB_BLE_SLV_F_0022 5000;
BA_ "NetworkRequest" SG_ 2348810498 L_TP_BDC_FD_L_UWB_BLE_SLV_F_0022 0;
BA_ "UserSigValidity" SG_ 2348810498 L_TP_BDC_FD_L_UWB_BLE_SLV_F_0022 0;
BA_ "UsrSigPurpose" SG_ 2348810498 L_TP_BDC_FD_L_UWB_BLE_SLV_F_0022 9;
BA_ "Description" SG_ 2348810498 L_TP_BDC_FD_L_UWB_BLE_SLV_F_0022 "TP Index : 271";
BA_ "SystemSignalLongSymbol" SG_ 2348810498 L_TP_BDC_FD_L_UWB_BLE_SLV_F_0022 "L_TP_BDC_FD_L_UWB_BLE_SLV_FD_Byte5";
BA_ "Version" SG_ 2348810498 L_TP_BDC_FD_L_UWB_BLE_SLV_F_0023 "23.01.02";
BA_ "NetworkRequestHoldingTime" SG_ 2348810498 L_TP_BDC_FD_L_UWB_BLE_SLV_F_0023 5000;
BA_ "NetworkRequest" SG_ 2348810498 L_TP_BDC_FD_L_UWB_BLE_SLV_F_0023 0;
BA_ "UserSigValidity" SG_ 2348810498 L_TP_BDC_FD_L_UWB_BLE_SLV_F_0023 0;
BA_ "UsrSigPurpose" SG_ 2348810498 L_TP_BDC_FD_L_UWB_BLE_SLV_F_0023 9;
BA_ "Description" SG_ 2348810498 L_TP_BDC_FD_L_UWB_BLE_SLV_F_0023 "TP Index : 271";
BA_ "SystemSignalLongSymbol" SG_ 2348810498 L_TP_BDC_FD_L_UWB_BLE_SLV_F_0023 "L_TP_BDC_FD_L_UWB_BLE_SLV_FD_Byte6";
BA_ "Version" SG_ 2348810498 L_TP_BDC_FD_L_UWB_BLE_SLV_F_0024 "23.01.02";
BA_ "NetworkRequestHoldingTime" SG_ 2348810498 L_TP_BDC_FD_L_UWB_BLE_SLV_F_0024 5000;
BA_ "NetworkRequest" SG_ 2348810498 L_TP_BDC_FD_L_UWB_BLE_SLV_F_0024 0;
BA_ "UserSigValidity" SG_ 2348810498 L_TP_BDC_FD_L_UWB_BLE_SLV_F_0024 0;
BA_ "UsrSigPurpose" SG_ 2348810498 L_TP_BDC_FD_L_UWB_BLE_SLV_F_0024 9;
BA_ "Description" SG_ 2348810498 L_TP_BDC_FD_L_UWB_BLE_SLV_F_0024 "TP Index : 271";
BA_ "SystemSignalLongSymbol" SG_ 2348810498 L_TP_BDC_FD_L_UWB_BLE_SLV_F_0024 "L_TP_BDC_FD_L_UWB_BLE_SLV_FD_Byte7";
BA_ "Version" SG_ 2348810498 L_TP_BDC_FD_L_UWB_BLE_SLV_F_0025 "23.01.02";
BA_ "NetworkRequestHoldingTime" SG_ 2348810498 L_TP_BDC_FD_L_UWB_BLE_SLV_F_0025 5000;
BA_ "NetworkRequest" SG_ 2348810498 L_TP_BDC_FD_L_UWB_BLE_SLV_F_0025 0;
BA_ "UserSigValidity" SG_ 2348810498 L_TP_BDC_FD_L_UWB_BLE_SLV_F_0025 0;
BA_ "UsrSigPurpose" SG_ 2348810498 L_TP_BDC_FD_L_UWB_BLE_SLV_F_0025 9;
BA_ "Description" SG_ 2348810498 L_TP_BDC_FD_L_UWB_BLE_SLV_F_0025 "TP Index : 271";
BA_ "SystemSignalLongSymbol" SG_ 2348810498 L_TP_BDC_FD_L_UWB_BLE_SLV_F_0025 "L_TP_BDC_FD_L_UWB_BLE_SLV_FD_Byte8";
BA_ "Version" SG_ 2348810498 L_TP_BDC_FD_L_UWB_BLE_SLV_F_0026 "23.01.02";
BA_ "NetworkRequestHoldingTime" SG_ 2348810498 L_TP_BDC_FD_L_UWB_BLE_SLV_F_0026 5000;
BA_ "NetworkRequest" SG_ 2348810498 L_TP_BDC_FD_L_UWB_BLE_SLV_F_0026 0;
BA_ "UserSigValidity" SG_ 2348810498 L_TP_BDC_FD_L_UWB_BLE_SLV_F_0026 0;
BA_ "UsrSigPurpose" SG_ 2348810498 L_TP_BDC_FD_L_UWB_BLE_SLV_F_0026 9;
BA_ "Description" SG_ 2348810498 L_TP_BDC_FD_L_UWB_BLE_SLV_F_0026 "TP Index : 271";
BA_ "SystemSignalLongSymbol" SG_ 2348810498 L_TP_BDC_FD_L_UWB_BLE_SLV_F_0026 "L_TP_BDC_FD_L_UWB_BLE_SLV_FD_Byte9";
BA_ "Version" SG_ 2348810498 L_TP_BDC_FD_L_UWB_BLE_SLV_F_0027 "23.01.02";
BA_ "NetworkRequestHoldingTime" SG_ 2348810498 L_TP_BDC_FD_L_UWB_BLE_SLV_F_0027 5000;
BA_ "NetworkRequest" SG_ 2348810498 L_TP_BDC_FD_L_UWB_BLE_SLV_F_0027 0;
BA_ "UserSigValidity" SG_ 2348810498 L_TP_BDC_FD_L_UWB_BLE_SLV_F_0027 0;
BA_ "UsrSigPurpose" SG_ 2348810498 L_TP_BDC_FD_L_UWB_BLE_SLV_F_0027 9;
BA_ "Description" SG_ 2348810498 L_TP_BDC_FD_L_UWB_BLE_SLV_F_0027 "TP Index : 271";
BA_ "SystemSignalLongSymbol" SG_ 2348810498 L_TP_BDC_FD_L_UWB_BLE_SLV_F_0027 "L_TP_BDC_FD_L_UWB_BLE_SLV_FD_Byte1";
BA_ "Version" SG_ 2348810498 L_TP_BDC_FD_L_UWB_BLE_SLV_F_0028 "23.01.02";
BA_ "NetworkRequestHoldingTime" SG_ 2348810498 L_TP_BDC_FD_L_UWB_BLE_SLV_F_0028 5000;
BA_ "NetworkRequest" SG_ 2348810498 L_TP_BDC_FD_L_UWB_BLE_SLV_F_0028 0;
BA_ "UserSigValidity" SG_ 2348810498 L_TP_BDC_FD_L_UWB_BLE_SLV_F_0028 0;
BA_ "UsrSigPurpose" SG_ 2348810498 L_TP_BDC_FD_L_UWB_BLE_SLV_F_0028 9;
BA_ "Description" SG_ 2348810498 L_TP_BDC_FD_L_UWB_BLE_SLV_F_0028 "TP Index : 271";
BA_ "SystemSignalLongSymbol" SG_ 2348810498 L_TP_BDC_FD_L_UWB_BLE_SLV_F_0028 "L_TP_BDC_FD_L_UWB_BLE_SLV_FD_Byte10";
BA_ "Version" SG_ 2348810498 L_TP_BDC_FD_L_UWB_BLE_SLV_F_0029 "23.01.02";
BA_ "NetworkRequestHoldingTime" SG_ 2348810498 L_TP_BDC_FD_L_UWB_BLE_SLV_F_0029 5000;
BA_ "NetworkRequest" SG_ 2348810498 L_TP_BDC_FD_L_UWB_BLE_SLV_F_0029 0;
BA_ "UserSigValidity" SG_ 2348810498 L_TP_BDC_FD_L_UWB_BLE_SLV_F_0029 0;
BA_ "UsrSigPurpose" SG_ 2348810498 L_TP_BDC_FD_L_UWB_BLE_SLV_F_0029 9;
BA_ "Description" SG_ 2348810498 L_TP_BDC_FD_L_UWB_BLE_SLV_F_0029 "TP Index : 271";
BA_ "SystemSignalLongSymbol" SG_ 2348810498 L_TP_BDC_FD_L_UWB_BLE_SLV_F_0029 "L_TP_BDC_FD_L_UWB_BLE_SLV_FD_Byte11";
BA_ "Version" SG_ 2348810498 L_TP_BDC_FD_L_UWB_BLE_SLV_F_0030 "23.01.02";
BA_ "NetworkRequestHoldingTime" SG_ 2348810498 L_TP_BDC_FD_L_UWB_BLE_SLV_F_0030 5000;
BA_ "NetworkRequest" SG_ 2348810498 L_TP_BDC_FD_L_UWB_BLE_SLV_F_0030 0;
BA_ "UserSigValidity" SG_ 2348810498 L_TP_BDC_FD_L_UWB_BLE_SLV_F_0030 0;
BA_ "UsrSigPurpose" SG_ 2348810498 L_TP_BDC_FD_L_UWB_BLE_SLV_F_0030 9;
BA_ "Description" SG_ 2348810498 L_TP_BDC_FD_L_UWB_BLE_SLV_F_0030 "TP Index : 271";
BA_ "SystemSignalLongSymbol" SG_ 2348810498 L_TP_BDC_FD_L_UWB_BLE_SLV_F_0030 "L_TP_BDC_FD_L_UWB_BLE_SLV_FD_Byte12";
BA_ "Version" SG_ 2214592657 L_DHRR_FD_Crc1Val "23.06.01";
BA_ "UserSigValidity" SG_ 2214592657 L_DHRR_FD_Crc1Val 3;
BA_ "GenSigStartValue" SG_ 2214592657 L_DHRR_FD_Crc1Val 65535;
BA_ "GenSigSendType" SG_ 2214592657 L_DHRR_FD_Crc1Val 4;
BA_ "Description" SG_ 2214592657 L_DHRR_FD_Crc1Val "The data area for CRC calculation is based on the data length (DLC) of the message DB.

The CRC shall be calculated over the entire data block (excluding the CRC bytes) including the user data, alive counter and Data ID



- CRC Polynomial (0x1021) , Ini";
BA_ "Version" SG_ 2214592657 L_DHRR_FD_AlvCnt1Val "23.06.01";
BA_ "UserSigValidity" SG_ 2214592657 L_DHRR_FD_AlvCnt1Val 3;
BA_ "GenSigSendType" SG_ 2214592657 L_DHRR_FD_AlvCnt1Val 4;
BA_ "Description" SG_ 2214592657 L_DHRR_FD_AlvCnt1Val "For the first transmission request for a data element the counter shall be initialized with 0 and shall be incremented by 1 for every subsequent send request. 

When the counter reaches the maximum value(0xFF), then it shall restart with 0 for the next s";
BA_ "Version" SG_ 2214592657 DHRR_NFCDetected "23.06.01";
BA_ "UserSigValidity" SG_ 2214592657 DHRR_NFCDetected 0;
BA_ "GenSigSendType" SG_ 2214592657 DHRR_NFCDetected 4;
BA_ "Version" SG_ 2214592657 DHRR_WlcmLt_Sta "23.06.01";
BA_ "UserSigValidity" SG_ 2214592657 DHRR_WlcmLt_Sta 0;
BA_ "GenSigSendType" SG_ 2214592657 DHRR_WlcmLt_Sta 4;
BA_ "Version" SG_ 2214592657 DHRR_NFCReset_Sta "23.06.01";
BA_ "UserSigValidity" SG_ 2214592657 DHRR_NFCReset_Sta 0;
BA_ "GenSigSendType" SG_ 2214592657 DHRR_NFCReset_Sta 4;
BA_ "Version" SG_ 2348810497 L_TP_L_UWB_BLE_MST_FD_BDC_FD_Byt "23.01.02";
BA_ "NetworkRequestHoldingTime" SG_ 2348810497 L_TP_L_UWB_BLE_MST_FD_BDC_FD_Byt 5000;
BA_ "NetworkRequest" SG_ 2348810497 L_TP_L_UWB_BLE_MST_FD_BDC_FD_Byt 0;
BA_ "UserSigValidity" SG_ 2348810497 L_TP_L_UWB_BLE_MST_FD_BDC_FD_Byt 0;
BA_ "UsrSigPurpose" SG_ 2348810497 L_TP_L_UWB_BLE_MST_FD_BDC_FD_Byt 9;
BA_ "Description" SG_ 2348810497 L_TP_L_UWB_BLE_MST_FD_BDC_FD_Byt "TP Index : 270";
BA_ "SystemSignalLongSymbol" SG_ 2348810497 L_TP_L_UWB_BLE_MST_FD_BDC_FD_Byt "L_TP_L_UWB_BLE_MST_FD_BDC_FD_Byte0";
BA_ "Version" SG_ 2348810497 L_TP_L_UWB_BLE_MST_FD_BDC_F_0000 "23.01.02";
BA_ "NetworkRequestHoldingTime" SG_ 2348810497 L_TP_L_UWB_BLE_MST_FD_BDC_F_0000 5000;
BA_ "NetworkRequest" SG_ 2348810497 L_TP_L_UWB_BLE_MST_FD_BDC_F_0000 0;
BA_ "UserSigValidity" SG_ 2348810497 L_TP_L_UWB_BLE_MST_FD_BDC_F_0000 0;
BA_ "UsrSigPurpose" SG_ 2348810497 L_TP_L_UWB_BLE_MST_FD_BDC_F_0000 9;
BA_ "Description" SG_ 2348810497 L_TP_L_UWB_BLE_MST_FD_BDC_F_0000 "TP Index : 270";
BA_ "SystemSignalLongSymbol" SG_ 2348810497 L_TP_L_UWB_BLE_MST_FD_BDC_F_0000 "L_TP_L_UWB_BLE_MST_FD_BDC_FD_Byte13";
BA_ "Version" SG_ 2348810497 L_TP_L_UWB_BLE_MST_FD_BDC_F_0001 "23.01.02";
BA_ "NetworkRequestHoldingTime" SG_ 2348810497 L_TP_L_UWB_BLE_MST_FD_BDC_F_0001 5000;
BA_ "NetworkRequest" SG_ 2348810497 L_TP_L_UWB_BLE_MST_FD_BDC_F_0001 0;
BA_ "UserSigValidity" SG_ 2348810497 L_TP_L_UWB_BLE_MST_FD_BDC_F_0001 0;
BA_ "UsrSigPurpose" SG_ 2348810497 L_TP_L_UWB_BLE_MST_FD_BDC_F_0001 9;
BA_ "Description" SG_ 2348810497 L_TP_L_UWB_BLE_MST_FD_BDC_F_0001 "TP Index : 270";
BA_ "SystemSignalLongSymbol" SG_ 2348810497 L_TP_L_UWB_BLE_MST_FD_BDC_F_0001 "L_TP_L_UWB_BLE_MST_FD_BDC_FD_Byte14";
BA_ "Version" SG_ 2348810497 L_TP_L_UWB_BLE_MST_FD_BDC_F_0002 "23.01.02";
BA_ "NetworkRequestHoldingTime" SG_ 2348810497 L_TP_L_UWB_BLE_MST_FD_BDC_F_0002 5000;
BA_ "NetworkRequest" SG_ 2348810497 L_TP_L_UWB_BLE_MST_FD_BDC_F_0002 0;
BA_ "UserSigValidity" SG_ 2348810497 L_TP_L_UWB_BLE_MST_FD_BDC_F_0002 0;
BA_ "UsrSigPurpose" SG_ 2348810497 L_TP_L_UWB_BLE_MST_FD_BDC_F_0002 9;
BA_ "Description" SG_ 2348810497 L_TP_L_UWB_BLE_MST_FD_BDC_F_0002 "TP Index : 270";
BA_ "SystemSignalLongSymbol" SG_ 2348810497 L_TP_L_UWB_BLE_MST_FD_BDC_F_0002 "L_TP_L_UWB_BLE_MST_FD_BDC_FD_Byte15";
BA_ "Version" SG_ 2348810497 L_TP_L_UWB_BLE_MST_FD_BDC_F_0003 "23.01.02";
BA_ "NetworkRequestHoldingTime" SG_ 2348810497 L_TP_L_UWB_BLE_MST_FD_BDC_F_0003 5000;
BA_ "NetworkRequest" SG_ 2348810497 L_TP_L_UWB_BLE_MST_FD_BDC_F_0003 0;
BA_ "UserSigValidity" SG_ 2348810497 L_TP_L_UWB_BLE_MST_FD_BDC_F_0003 0;
BA_ "UsrSigPurpose" SG_ 2348810497 L_TP_L_UWB_BLE_MST_FD_BDC_F_0003 9;
BA_ "Description" SG_ 2348810497 L_TP_L_UWB_BLE_MST_FD_BDC_F_0003 "TP Index : 270";
BA_ "SystemSignalLongSymbol" SG_ 2348810497 L_TP_L_UWB_BLE_MST_FD_BDC_F_0003 "L_TP_L_UWB_BLE_MST_FD_BDC_FD_Byte16";
BA_ "Version" SG_ 2348810497 L_TP_L_UWB_BLE_MST_FD_BDC_F_0004 "23.01.02";
BA_ "NetworkRequestHoldingTime" SG_ 2348810497 L_TP_L_UWB_BLE_MST_FD_BDC_F_0004 5000;
BA_ "NetworkRequest" SG_ 2348810497 L_TP_L_UWB_BLE_MST_FD_BDC_F_0004 0;
BA_ "UserSigValidity" SG_ 2348810497 L_TP_L_UWB_BLE_MST_FD_BDC_F_0004 0;
BA_ "UsrSigPurpose" SG_ 2348810497 L_TP_L_UWB_BLE_MST_FD_BDC_F_0004 9;
BA_ "Description" SG_ 2348810497 L_TP_L_UWB_BLE_MST_FD_BDC_F_0004 "TP Index : 270";
BA_ "SystemSignalLongSymbol" SG_ 2348810497 L_TP_L_UWB_BLE_MST_FD_BDC_F_0004 "L_TP_L_UWB_BLE_MST_FD_BDC_FD_Byte17";
BA_ "Version" SG_ 2348810497 L_TP_L_UWB_BLE_MST_FD_BDC_F_0005 "23.01.02";
BA_ "NetworkRequestHoldingTime" SG_ 2348810497 L_TP_L_UWB_BLE_MST_FD_BDC_F_0005 5000;
BA_ "NetworkRequest" SG_ 2348810497 L_TP_L_UWB_BLE_MST_FD_BDC_F_0005 0;
BA_ "UserSigValidity" SG_ 2348810497 L_TP_L_UWB_BLE_MST_FD_BDC_F_0005 0;
BA_ "UsrSigPurpose" SG_ 2348810497 L_TP_L_UWB_BLE_MST_FD_BDC_F_0005 9;
BA_ "Description" SG_ 2348810497 L_TP_L_UWB_BLE_MST_FD_BDC_F_0005 "TP Index : 270";
BA_ "SystemSignalLongSymbol" SG_ 2348810497 L_TP_L_UWB_BLE_MST_FD_BDC_F_0005 "L_TP_L_UWB_BLE_MST_FD_BDC_FD_Byte18";
BA_ "Version" SG_ 2348810497 L_TP_L_UWB_BLE_MST_FD_BDC_F_0006 "23.01.02";
BA_ "NetworkRequestHoldingTime" SG_ 2348810497 L_TP_L_UWB_BLE_MST_FD_BDC_F_0006 5000;
BA_ "NetworkRequest" SG_ 2348810497 L_TP_L_UWB_BLE_MST_FD_BDC_F_0006 0;
BA_ "UserSigValidity" SG_ 2348810497 L_TP_L_UWB_BLE_MST_FD_BDC_F_0006 0;
BA_ "UsrSigPurpose" SG_ 2348810497 L_TP_L_UWB_BLE_MST_FD_BDC_F_0006 9;
BA_ "Description" SG_ 2348810497 L_TP_L_UWB_BLE_MST_FD_BDC_F_0006 "TP Index : 270";
BA_ "SystemSignalLongSymbol" SG_ 2348810497 L_TP_L_UWB_BLE_MST_FD_BDC_F_0006 "L_TP_L_UWB_BLE_MST_FD_BDC_FD_Byte19";
BA_ "Version" SG_ 2348810497 L_TP_L_UWB_BLE_MST_FD_BDC_F_0007 "23.01.02";
BA_ "NetworkRequestHoldingTime" SG_ 2348810497 L_TP_L_UWB_BLE_MST_FD_BDC_F_0007 5000;
BA_ "NetworkRequest" SG_ 2348810497 L_TP_L_UWB_BLE_MST_FD_BDC_F_0007 0;
BA_ "UserSigValidity" SG_ 2348810497 L_TP_L_UWB_BLE_MST_FD_BDC_F_0007 0;
BA_ "UsrSigPurpose" SG_ 2348810497 L_TP_L_UWB_BLE_MST_FD_BDC_F_0007 9;
BA_ "Description" SG_ 2348810497 L_TP_L_UWB_BLE_MST_FD_BDC_F_0007 "TP Index : 270";
BA_ "SystemSignalLongSymbol" SG_ 2348810497 L_TP_L_UWB_BLE_MST_FD_BDC_F_0007 "L_TP_L_UWB_BLE_MST_FD_BDC_FD_Byte2";
BA_ "Version" SG_ 2348810497 L_TP_L_UWB_BLE_MST_FD_BDC_F_0008 "23.01.02";
BA_ "NetworkRequestHoldingTime" SG_ 2348810497 L_TP_L_UWB_BLE_MST_FD_BDC_F_0008 5000;
BA_ "NetworkRequest" SG_ 2348810497 L_TP_L_UWB_BLE_MST_FD_BDC_F_0008 0;
BA_ "UserSigValidity" SG_ 2348810497 L_TP_L_UWB_BLE_MST_FD_BDC_F_0008 0;
BA_ "UsrSigPurpose" SG_ 2348810497 L_TP_L_UWB_BLE_MST_FD_BDC_F_0008 9;
BA_ "Description" SG_ 2348810497 L_TP_L_UWB_BLE_MST_FD_BDC_F_0008 "TP Index : 270";
BA_ "SystemSignalLongSymbol" SG_ 2348810497 L_TP_L_UWB_BLE_MST_FD_BDC_F_0008 "L_TP_L_UWB_BLE_MST_FD_BDC_FD_Byte20";
BA_ "Version" SG_ 2348810497 L_TP_L_UWB_BLE_MST_FD_BDC_F_0009 "23.01.02";
BA_ "NetworkRequestHoldingTime" SG_ 2348810497 L_TP_L_UWB_BLE_MST_FD_BDC_F_0009 5000;
BA_ "NetworkRequest" SG_ 2348810497 L_TP_L_UWB_BLE_MST_FD_BDC_F_0009 0;
BA_ "UserSigValidity" SG_ 2348810497 L_TP_L_UWB_BLE_MST_FD_BDC_F_0009 0;
BA_ "UsrSigPurpose" SG_ 2348810497 L_TP_L_UWB_BLE_MST_FD_BDC_F_0009 9;
BA_ "Description" SG_ 2348810497 L_TP_L_UWB_BLE_MST_FD_BDC_F_0009 "TP Index : 270";
BA_ "SystemSignalLongSymbol" SG_ 2348810497 L_TP_L_UWB_BLE_MST_FD_BDC_F_0009 "L_TP_L_UWB_BLE_MST_FD_BDC_FD_Byte21";
BA_ "Version" SG_ 2348810497 L_TP_L_UWB_BLE_MST_FD_BDC_F_0010 "23.01.02";
BA_ "NetworkRequestHoldingTime" SG_ 2348810497 L_TP_L_UWB_BLE_MST_FD_BDC_F_0010 5000;
BA_ "NetworkRequest" SG_ 2348810497 L_TP_L_UWB_BLE_MST_FD_BDC_F_0010 0;
BA_ "UserSigValidity" SG_ 2348810497 L_TP_L_UWB_BLE_MST_FD_BDC_F_0010 0;
BA_ "UsrSigPurpose" SG_ 2348810497 L_TP_L_UWB_BLE_MST_FD_BDC_F_0010 9;
BA_ "Description" SG_ 2348810497 L_TP_L_UWB_BLE_MST_FD_BDC_F_0010 "TP Index : 270";
BA_ "SystemSignalLongSymbol" SG_ 2348810497 L_TP_L_UWB_BLE_MST_FD_BDC_F_0010 "L_TP_L_UWB_BLE_MST_FD_BDC_FD_Byte22";
BA_ "Version" SG_ 2348810497 L_TP_L_UWB_BLE_MST_FD_BDC_F_0011 "23.01.02";
BA_ "NetworkRequestHoldingTime" SG_ 2348810497 L_TP_L_UWB_BLE_MST_FD_BDC_F_0011 5000;
BA_ "NetworkRequest" SG_ 2348810497 L_TP_L_UWB_BLE_MST_FD_BDC_F_0011 0;
BA_ "UserSigValidity" SG_ 2348810497 L_TP_L_UWB_BLE_MST_FD_BDC_F_0011 0;
BA_ "UsrSigPurpose" SG_ 2348810497 L_TP_L_UWB_BLE_MST_FD_BDC_F_0011 9;
BA_ "Description" SG_ 2348810497 L_TP_L_UWB_BLE_MST_FD_BDC_F_0011 "TP Index : 270";
BA_ "SystemSignalLongSymbol" SG_ 2348810497 L_TP_L_UWB_BLE_MST_FD_BDC_F_0011 "L_TP_L_UWB_BLE_MST_FD_BDC_FD_Byte23";
BA_ "Version" SG_ 2348810497 L_TP_L_UWB_BLE_MST_FD_BDC_F_0012 "23.01.02";
BA_ "NetworkRequestHoldingTime" SG_ 2348810497 L_TP_L_UWB_BLE_MST_FD_BDC_F_0012 5000;
BA_ "NetworkRequest" SG_ 2348810497 L_TP_L_UWB_BLE_MST_FD_BDC_F_0012 0;
BA_ "UserSigValidity" SG_ 2348810497 L_TP_L_UWB_BLE_MST_FD_BDC_F_0012 0;
BA_ "UsrSigPurpose" SG_ 2348810497 L_TP_L_UWB_BLE_MST_FD_BDC_F_0012 9;
BA_ "Description" SG_ 2348810497 L_TP_L_UWB_BLE_MST_FD_BDC_F_0012 "TP Index : 270";
BA_ "SystemSignalLongSymbol" SG_ 2348810497 L_TP_L_UWB_BLE_MST_FD_BDC_F_0012 "L_TP_L_UWB_BLE_MST_FD_BDC_FD_Byte24";
BA_ "Version" SG_ 2348810497 L_TP_L_UWB_BLE_MST_FD_BDC_F_0013 "23.01.02";
BA_ "NetworkRequestHoldingTime" SG_ 2348810497 L_TP_L_UWB_BLE_MST_FD_BDC_F_0013 5000;
BA_ "NetworkRequest" SG_ 2348810497 L_TP_L_UWB_BLE_MST_FD_BDC_F_0013 0;
BA_ "UserSigValidity" SG_ 2348810497 L_TP_L_UWB_BLE_MST_FD_BDC_F_0013 0;
BA_ "UsrSigPurpose" SG_ 2348810497 L_TP_L_UWB_BLE_MST_FD_BDC_F_0013 9;
BA_ "Description" SG_ 2348810497 L_TP_L_UWB_BLE_MST_FD_BDC_F_0013 "TP Index : 270";
BA_ "SystemSignalLongSymbol" SG_ 2348810497 L_TP_L_UWB_BLE_MST_FD_BDC_F_0013 "L_TP_L_UWB_BLE_MST_FD_BDC_FD_Byte25";
BA_ "Version" SG_ 2348810497 L_TP_L_UWB_BLE_MST_FD_BDC_F_0014 "23.01.02";
BA_ "NetworkRequestHoldingTime" SG_ 2348810497 L_TP_L_UWB_BLE_MST_FD_BDC_F_0014 5000;
BA_ "NetworkRequest" SG_ 2348810497 L_TP_L_UWB_BLE_MST_FD_BDC_F_0014 0;
BA_ "UserSigValidity" SG_ 2348810497 L_TP_L_UWB_BLE_MST_FD_BDC_F_0014 0;
BA_ "UsrSigPurpose" SG_ 2348810497 L_TP_L_UWB_BLE_MST_FD_BDC_F_0014 9;
BA_ "Description" SG_ 2348810497 L_TP_L_UWB_BLE_MST_FD_BDC_F_0014 "TP Index : 270";
BA_ "SystemSignalLongSymbol" SG_ 2348810497 L_TP_L_UWB_BLE_MST_FD_BDC_F_0014 "L_TP_L_UWB_BLE_MST_FD_BDC_FD_Byte26";
BA_ "Version" SG_ 2348810497 L_TP_L_UWB_BLE_MST_FD_BDC_F_0015 "23.01.02";
BA_ "NetworkRequestHoldingTime" SG_ 2348810497 L_TP_L_UWB_BLE_MST_FD_BDC_F_0015 5000;
BA_ "NetworkRequest" SG_ 2348810497 L_TP_L_UWB_BLE_MST_FD_BDC_F_0015 0;
BA_ "UserSigValidity" SG_ 2348810497 L_TP_L_UWB_BLE_MST_FD_BDC_F_0015 0;
BA_ "UsrSigPurpose" SG_ 2348810497 L_TP_L_UWB_BLE_MST_FD_BDC_F_0015 9;
BA_ "Description" SG_ 2348810497 L_TP_L_UWB_BLE_MST_FD_BDC_F_0015 "TP Index : 270";
BA_ "SystemSignalLongSymbol" SG_ 2348810497 L_TP_L_UWB_BLE_MST_FD_BDC_F_0015 "L_TP_L_UWB_BLE_MST_FD_BDC_FD_Byte27";
BA_ "Version" SG_ 2348810497 L_TP_L_UWB_BLE_MST_FD_BDC_F_0016 "23.01.02";
BA_ "NetworkRequestHoldingTime" SG_ 2348810497 L_TP_L_UWB_BLE_MST_FD_BDC_F_0016 5000;
BA_ "NetworkRequest" SG_ 2348810497 L_TP_L_UWB_BLE_MST_FD_BDC_F_0016 0;
BA_ "UserSigValidity" SG_ 2348810497 L_TP_L_UWB_BLE_MST_FD_BDC_F_0016 0;
BA_ "UsrSigPurpose" SG_ 2348810497 L_TP_L_UWB_BLE_MST_FD_BDC_F_0016 9;
BA_ "Description" SG_ 2348810497 L_TP_L_UWB_BLE_MST_FD_BDC_F_0016 "TP Index : 270";
BA_ "SystemSignalLongSymbol" SG_ 2348810497 L_TP_L_UWB_BLE_MST_FD_BDC_F_0016 "L_TP_L_UWB_BLE_MST_FD_BDC_FD_Byte28";
BA_ "Version" SG_ 2348810497 L_TP_L_UWB_BLE_MST_FD_BDC_F_0017 "23.01.02";
BA_ "NetworkRequestHoldingTime" SG_ 2348810497 L_TP_L_UWB_BLE_MST_FD_BDC_F_0017 5000;
BA_ "NetworkRequest" SG_ 2348810497 L_TP_L_UWB_BLE_MST_FD_BDC_F_0017 0;
BA_ "UserSigValidity" SG_ 2348810497 L_TP_L_UWB_BLE_MST_FD_BDC_F_0017 0;
BA_ "UsrSigPurpose" SG_ 2348810497 L_TP_L_UWB_BLE_MST_FD_BDC_F_0017 9;
BA_ "Description" SG_ 2348810497 L_TP_L_UWB_BLE_MST_FD_BDC_F_0017 "TP Index : 270";
BA_ "SystemSignalLongSymbol" SG_ 2348810497 L_TP_L_UWB_BLE_MST_FD_BDC_F_0017 "L_TP_L_UWB_BLE_MST_FD_BDC_FD_Byte29";
BA_ "Version" SG_ 2348810497 L_TP_L_UWB_BLE_MST_FD_BDC_F_0018 "23.01.02";
BA_ "NetworkRequestHoldingTime" SG_ 2348810497 L_TP_L_UWB_BLE_MST_FD_BDC_F_0018 5000;
BA_ "NetworkRequest" SG_ 2348810497 L_TP_L_UWB_BLE_MST_FD_BDC_F_0018 0;
BA_ "UserSigValidity" SG_ 2348810497 L_TP_L_UWB_BLE_MST_FD_BDC_F_0018 0;
BA_ "UsrSigPurpose" SG_ 2348810497 L_TP_L_UWB_BLE_MST_FD_BDC_F_0018 9;
BA_ "Description" SG_ 2348810497 L_TP_L_UWB_BLE_MST_FD_BDC_F_0018 "TP Index : 270";
BA_ "SystemSignalLongSymbol" SG_ 2348810497 L_TP_L_UWB_BLE_MST_FD_BDC_F_0018 "L_TP_L_UWB_BLE_MST_FD_BDC_FD_Byte3";
BA_ "Version" SG_ 2348810497 L_TP_L_UWB_BLE_MST_FD_BDC_F_0019 "23.01.02";
BA_ "NetworkRequestHoldingTime" SG_ 2348810497 L_TP_L_UWB_BLE_MST_FD_BDC_F_0019 5000;
BA_ "NetworkRequest" SG_ 2348810497 L_TP_L_UWB_BLE_MST_FD_BDC_F_0019 0;
BA_ "UserSigValidity" SG_ 2348810497 L_TP_L_UWB_BLE_MST_FD_BDC_F_0019 0;
BA_ "UsrSigPurpose" SG_ 2348810497 L_TP_L_UWB_BLE_MST_FD_BDC_F_0019 9;
BA_ "Description" SG_ 2348810497 L_TP_L_UWB_BLE_MST_FD_BDC_F_0019 "TP Index : 270";
BA_ "SystemSignalLongSymbol" SG_ 2348810497 L_TP_L_UWB_BLE_MST_FD_BDC_F_0019 "L_TP_L_UWB_BLE_MST_FD_BDC_FD_Byte30";
BA_ "Version" SG_ 2348810497 L_TP_L_UWB_BLE_MST_FD_BDC_F_0020 "23.01.02";
BA_ "NetworkRequestHoldingTime" SG_ 2348810497 L_TP_L_UWB_BLE_MST_FD_BDC_F_0020 5000;
BA_ "NetworkRequest" SG_ 2348810497 L_TP_L_UWB_BLE_MST_FD_BDC_F_0020 0;
BA_ "UserSigValidity" SG_ 2348810497 L_TP_L_UWB_BLE_MST_FD_BDC_F_0020 0;
BA_ "UsrSigPurpose" SG_ 2348810497 L_TP_L_UWB_BLE_MST_FD_BDC_F_0020 9;
BA_ "Description" SG_ 2348810497 L_TP_L_UWB_BLE_MST_FD_BDC_F_0020 "TP Index : 270";
BA_ "SystemSignalLongSymbol" SG_ 2348810497 L_TP_L_UWB_BLE_MST_FD_BDC_F_0020 "L_TP_L_UWB_BLE_MST_FD_BDC_FD_Byte31";
BA_ "Version" SG_ 2348810497 L_TP_L_UWB_BLE_MST_FD_BDC_F_0021 "23.01.02";
BA_ "NetworkRequestHoldingTime" SG_ 2348810497 L_TP_L_UWB_BLE_MST_FD_BDC_F_0021 5000;
BA_ "NetworkRequest" SG_ 2348810497 L_TP_L_UWB_BLE_MST_FD_BDC_F_0021 0;
BA_ "UserSigValidity" SG_ 2348810497 L_TP_L_UWB_BLE_MST_FD_BDC_F_0021 0;
BA_ "UsrSigPurpose" SG_ 2348810497 L_TP_L_UWB_BLE_MST_FD_BDC_F_0021 9;
BA_ "Description" SG_ 2348810497 L_TP_L_UWB_BLE_MST_FD_BDC_F_0021 "TP Index : 270";
BA_ "SystemSignalLongSymbol" SG_ 2348810497 L_TP_L_UWB_BLE_MST_FD_BDC_F_0021 "L_TP_L_UWB_BLE_MST_FD_BDC_FD_Byte4";
BA_ "Version" SG_ 2348810497 L_TP_L_UWB_BLE_MST_FD_BDC_F_0022 "23.01.02";
BA_ "NetworkRequestHoldingTime" SG_ 2348810497 L_TP_L_UWB_BLE_MST_FD_BDC_F_0022 5000;
BA_ "NetworkRequest" SG_ 2348810497 L_TP_L_UWB_BLE_MST_FD_BDC_F_0022 0;
BA_ "UserSigValidity" SG_ 2348810497 L_TP_L_UWB_BLE_MST_FD_BDC_F_0022 0;
BA_ "UsrSigPurpose" SG_ 2348810497 L_TP_L_UWB_BLE_MST_FD_BDC_F_0022 9;
BA_ "Description" SG_ 2348810497 L_TP_L_UWB_BLE_MST_FD_BDC_F_0022 "TP Index : 270";
BA_ "SystemSignalLongSymbol" SG_ 2348810497 L_TP_L_UWB_BLE_MST_FD_BDC_F_0022 "L_TP_L_UWB_BLE_MST_FD_BDC_FD_Byte5";
BA_ "Version" SG_ 2348810497 L_TP_L_UWB_BLE_MST_FD_BDC_F_0023 "23.01.02";
BA_ "NetworkRequestHoldingTime" SG_ 2348810497 L_TP_L_UWB_BLE_MST_FD_BDC_F_0023 5000;
BA_ "NetworkRequest" SG_ 2348810497 L_TP_L_UWB_BLE_MST_FD_BDC_F_0023 0;
BA_ "UserSigValidity" SG_ 2348810497 L_TP_L_UWB_BLE_MST_FD_BDC_F_0023 0;
BA_ "UsrSigPurpose" SG_ 2348810497 L_TP_L_UWB_BLE_MST_FD_BDC_F_0023 9;
BA_ "Description" SG_ 2348810497 L_TP_L_UWB_BLE_MST_FD_BDC_F_0023 "TP Index : 270";
BA_ "SystemSignalLongSymbol" SG_ 2348810497 L_TP_L_UWB_BLE_MST_FD_BDC_F_0023 "L_TP_L_UWB_BLE_MST_FD_BDC_FD_Byte6";
BA_ "Version" SG_ 2348810497 L_TP_L_UWB_BLE_MST_FD_BDC_F_0024 "23.01.02";
BA_ "NetworkRequestHoldingTime" SG_ 2348810497 L_TP_L_UWB_BLE_MST_FD_BDC_F_0024 5000;
BA_ "NetworkRequest" SG_ 2348810497 L_TP_L_UWB_BLE_MST_FD_BDC_F_0024 0;
BA_ "UserSigValidity" SG_ 2348810497 L_TP_L_UWB_BLE_MST_FD_BDC_F_0024 0;
BA_ "UsrSigPurpose" SG_ 2348810497 L_TP_L_UWB_BLE_MST_FD_BDC_F_0024 9;
BA_ "Description" SG_ 2348810497 L_TP_L_UWB_BLE_MST_FD_BDC_F_0024 "TP Index : 270";
BA_ "SystemSignalLongSymbol" SG_ 2348810497 L_TP_L_UWB_BLE_MST_FD_BDC_F_0024 "L_TP_L_UWB_BLE_MST_FD_BDC_FD_Byte7";
BA_ "Version" SG_ 2348810497 L_TP_L_UWB_BLE_MST_FD_BDC_F_0025 "23.01.02";
BA_ "NetworkRequestHoldingTime" SG_ 2348810497 L_TP_L_UWB_BLE_MST_FD_BDC_F_0025 5000;
BA_ "NetworkRequest" SG_ 2348810497 L_TP_L_UWB_BLE_MST_FD_BDC_F_0025 0;
BA_ "UserSigValidity" SG_ 2348810497 L_TP_L_UWB_BLE_MST_FD_BDC_F_0025 0;
BA_ "UsrSigPurpose" SG_ 2348810497 L_TP_L_UWB_BLE_MST_FD_BDC_F_0025 9;
BA_ "Description" SG_ 2348810497 L_TP_L_UWB_BLE_MST_FD_BDC_F_0025 "TP Index : 270";
BA_ "SystemSignalLongSymbol" SG_ 2348810497 L_TP_L_UWB_BLE_MST_FD_BDC_F_0025 "L_TP_L_UWB_BLE_MST_FD_BDC_FD_Byte8";
BA_ "Version" SG_ 2348810497 L_TP_L_UWB_BLE_MST_FD_BDC_F_0026 "23.01.02";
BA_ "NetworkRequestHoldingTime" SG_ 2348810497 L_TP_L_UWB_BLE_MST_FD_BDC_F_0026 5000;
BA_ "NetworkRequest" SG_ 2348810497 L_TP_L_UWB_BLE_MST_FD_BDC_F_0026 0;
BA_ "UserSigValidity" SG_ 2348810497 L_TP_L_UWB_BLE_MST_FD_BDC_F_0026 0;
BA_ "UsrSigPurpose" SG_ 2348810497 L_TP_L_UWB_BLE_MST_FD_BDC_F_0026 9;
BA_ "Description" SG_ 2348810497 L_TP_L_UWB_BLE_MST_FD_BDC_F_0026 "TP Index : 270";
BA_ "SystemSignalLongSymbol" SG_ 2348810497 L_TP_L_UWB_BLE_MST_FD_BDC_F_0026 "L_TP_L_UWB_BLE_MST_FD_BDC_FD_Byte9";
BA_ "Version" SG_ 2348810497 L_TP_L_UWB_BLE_MST_FD_BDC_F_0027 "23.01.02";
BA_ "NetworkRequestHoldingTime" SG_ 2348810497 L_TP_L_UWB_BLE_MST_FD_BDC_F_0027 5000;
BA_ "NetworkRequest" SG_ 2348810497 L_TP_L_UWB_BLE_MST_FD_BDC_F_0027 0;
BA_ "UserSigValidity" SG_ 2348810497 L_TP_L_UWB_BLE_MST_FD_BDC_F_0027 0;
BA_ "UsrSigPurpose" SG_ 2348810497 L_TP_L_UWB_BLE_MST_FD_BDC_F_0027 9;
BA_ "Description" SG_ 2348810497 L_TP_L_UWB_BLE_MST_FD_BDC_F_0027 "TP Index : 270";
BA_ "SystemSignalLongSymbol" SG_ 2348810497 L_TP_L_UWB_BLE_MST_FD_BDC_F_0027 "L_TP_L_UWB_BLE_MST_FD_BDC_FD_Byte1";
BA_ "Version" SG_ 2348810497 L_TP_L_UWB_BLE_MST_FD_BDC_F_0028 "23.01.02";
BA_ "NetworkRequestHoldingTime" SG_ 2348810497 L_TP_L_UWB_BLE_MST_FD_BDC_F_0028 5000;
BA_ "NetworkRequest" SG_ 2348810497 L_TP_L_UWB_BLE_MST_FD_BDC_F_0028 0;
BA_ "UserSigValidity" SG_ 2348810497 L_TP_L_UWB_BLE_MST_FD_BDC_F_0028 0;
BA_ "UsrSigPurpose" SG_ 2348810497 L_TP_L_UWB_BLE_MST_FD_BDC_F_0028 9;
BA_ "Description" SG_ 2348810497 L_TP_L_UWB_BLE_MST_FD_BDC_F_0028 "TP Index : 270";
BA_ "SystemSignalLongSymbol" SG_ 2348810497 L_TP_L_UWB_BLE_MST_FD_BDC_F_0028 "L_TP_L_UWB_BLE_MST_FD_BDC_FD_Byte10";
BA_ "Version" SG_ 2348810497 L_TP_L_UWB_BLE_MST_FD_BDC_F_0029 "23.01.02";
BA_ "NetworkRequestHoldingTime" SG_ 2348810497 L_TP_L_UWB_BLE_MST_FD_BDC_F_0029 5000;
BA_ "NetworkRequest" SG_ 2348810497 L_TP_L_UWB_BLE_MST_FD_BDC_F_0029 0;
BA_ "UserSigValidity" SG_ 2348810497 L_TP_L_UWB_BLE_MST_FD_BDC_F_0029 0;
BA_ "UsrSigPurpose" SG_ 2348810497 L_TP_L_UWB_BLE_MST_FD_BDC_F_0029 9;
BA_ "Description" SG_ 2348810497 L_TP_L_UWB_BLE_MST_FD_BDC_F_0029 "TP Index : 270";
BA_ "SystemSignalLongSymbol" SG_ 2348810497 L_TP_L_UWB_BLE_MST_FD_BDC_F_0029 "L_TP_L_UWB_BLE_MST_FD_BDC_FD_Byte11";
BA_ "Version" SG_ 2348810497 L_TP_L_UWB_BLE_MST_FD_BDC_F_0030 "23.01.02";
BA_ "NetworkRequestHoldingTime" SG_ 2348810497 L_TP_L_UWB_BLE_MST_FD_BDC_F_0030 5000;
BA_ "NetworkRequest" SG_ 2348810497 L_TP_L_UWB_BLE_MST_FD_BDC_F_0030 0;
BA_ "UserSigValidity" SG_ 2348810497 L_TP_L_UWB_BLE_MST_FD_BDC_F_0030 0;
BA_ "UsrSigPurpose" SG_ 2348810497 L_TP_L_UWB_BLE_MST_FD_BDC_F_0030 9;
BA_ "Description" SG_ 2348810497 L_TP_L_UWB_BLE_MST_FD_BDC_F_0030 "TP Index : 270";
BA_ "SystemSignalLongSymbol" SG_ 2348810497 L_TP_L_UWB_BLE_MST_FD_BDC_F_0030 "L_TP_L_UWB_BLE_MST_FD_BDC_FD_Byte12";
BA_ "Version" SG_ 2348810496 L_TP_BDC_FD_L_UWB_BLE_MST_FD_Byt "23.01.02";
BA_ "NetworkRequestHoldingTime" SG_ 2348810496 L_TP_BDC_FD_L_UWB_BLE_MST_FD_Byt 5000;
BA_ "NetworkRequest" SG_ 2348810496 L_TP_BDC_FD_L_UWB_BLE_MST_FD_Byt 0;
BA_ "UserSigValidity" SG_ 2348810496 L_TP_BDC_FD_L_UWB_BLE_MST_FD_Byt 0;
BA_ "UsrSigPurpose" SG_ 2348810496 L_TP_BDC_FD_L_UWB_BLE_MST_FD_Byt 9;
BA_ "Description" SG_ 2348810496 L_TP_BDC_FD_L_UWB_BLE_MST_FD_Byt "TP Index : 270";
BA_ "SystemSignalLongSymbol" SG_ 2348810496 L_TP_BDC_FD_L_UWB_BLE_MST_FD_Byt "L_TP_BDC_FD_L_UWB_BLE_MST_FD_Byte0";
BA_ "Version" SG_ 2348810496 L_TP_BDC_FD_L_UWB_BLE_MST_F_0000 "23.01.02";
BA_ "NetworkRequestHoldingTime" SG_ 2348810496 L_TP_BDC_FD_L_UWB_BLE_MST_F_0000 5000;
BA_ "NetworkRequest" SG_ 2348810496 L_TP_BDC_FD_L_UWB_BLE_MST_F_0000 0;
BA_ "UserSigValidity" SG_ 2348810496 L_TP_BDC_FD_L_UWB_BLE_MST_F_0000 0;
BA_ "UsrSigPurpose" SG_ 2348810496 L_TP_BDC_FD_L_UWB_BLE_MST_F_0000 9;
BA_ "Description" SG_ 2348810496 L_TP_BDC_FD_L_UWB_BLE_MST_F_0000 "TP Index : 270";
BA_ "SystemSignalLongSymbol" SG_ 2348810496 L_TP_BDC_FD_L_UWB_BLE_MST_F_0000 "L_TP_BDC_FD_L_UWB_BLE_MST_FD_Byte13";
BA_ "Version" SG_ 2348810496 L_TP_BDC_FD_L_UWB_BLE_MST_F_0001 "23.01.02";
BA_ "NetworkRequestHoldingTime" SG_ 2348810496 L_TP_BDC_FD_L_UWB_BLE_MST_F_0001 5000;
BA_ "NetworkRequest" SG_ 2348810496 L_TP_BDC_FD_L_UWB_BLE_MST_F_0001 0;
BA_ "UserSigValidity" SG_ 2348810496 L_TP_BDC_FD_L_UWB_BLE_MST_F_0001 0;
BA_ "UsrSigPurpose" SG_ 2348810496 L_TP_BDC_FD_L_UWB_BLE_MST_F_0001 9;
BA_ "Description" SG_ 2348810496 L_TP_BDC_FD_L_UWB_BLE_MST_F_0001 "TP Index : 270";
BA_ "SystemSignalLongSymbol" SG_ 2348810496 L_TP_BDC_FD_L_UWB_BLE_MST_F_0001 "L_TP_BDC_FD_L_UWB_BLE_MST_FD_Byte14";
BA_ "Version" SG_ 2348810496 L_TP_BDC_FD_L_UWB_BLE_MST_F_0002 "23.01.02";
BA_ "NetworkRequestHoldingTime" SG_ 2348810496 L_TP_BDC_FD_L_UWB_BLE_MST_F_0002 5000;
BA_ "NetworkRequest" SG_ 2348810496 L_TP_BDC_FD_L_UWB_BLE_MST_F_0002 0;
BA_ "UserSigValidity" SG_ 2348810496 L_TP_BDC_FD_L_UWB_BLE_MST_F_0002 0;
BA_ "UsrSigPurpose" SG_ 2348810496 L_TP_BDC_FD_L_UWB_BLE_MST_F_0002 9;
BA_ "Description" SG_ 2348810496 L_TP_BDC_FD_L_UWB_BLE_MST_F_0002 "TP Index : 270";
BA_ "SystemSignalLongSymbol" SG_ 2348810496 L_TP_BDC_FD_L_UWB_BLE_MST_F_0002 "L_TP_BDC_FD_L_UWB_BLE_MST_FD_Byte15";
BA_ "Version" SG_ 2348810496 L_TP_BDC_FD_L_UWB_BLE_MST_F_0003 "23.01.02";
BA_ "NetworkRequestHoldingTime" SG_ 2348810496 L_TP_BDC_FD_L_UWB_BLE_MST_F_0003 5000;
BA_ "NetworkRequest" SG_ 2348810496 L_TP_BDC_FD_L_UWB_BLE_MST_F_0003 0;
BA_ "UserSigValidity" SG_ 2348810496 L_TP_BDC_FD_L_UWB_BLE_MST_F_0003 0;
BA_ "UsrSigPurpose" SG_ 2348810496 L_TP_BDC_FD_L_UWB_BLE_MST_F_0003 9;
BA_ "Description" SG_ 2348810496 L_TP_BDC_FD_L_UWB_BLE_MST_F_0003 "TP Index : 270";
BA_ "SystemSignalLongSymbol" SG_ 2348810496 L_TP_BDC_FD_L_UWB_BLE_MST_F_0003 "L_TP_BDC_FD_L_UWB_BLE_MST_FD_Byte16";
BA_ "Version" SG_ 2348810496 L_TP_BDC_FD_L_UWB_BLE_MST_F_0004 "23.01.02";
BA_ "NetworkRequestHoldingTime" SG_ 2348810496 L_TP_BDC_FD_L_UWB_BLE_MST_F_0004 5000;
BA_ "NetworkRequest" SG_ 2348810496 L_TP_BDC_FD_L_UWB_BLE_MST_F_0004 0;
BA_ "UserSigValidity" SG_ 2348810496 L_TP_BDC_FD_L_UWB_BLE_MST_F_0004 0;
BA_ "UsrSigPurpose" SG_ 2348810496 L_TP_BDC_FD_L_UWB_BLE_MST_F_0004 9;
BA_ "Description" SG_ 2348810496 L_TP_BDC_FD_L_UWB_BLE_MST_F_0004 "TP Index : 270";
BA_ "SystemSignalLongSymbol" SG_ 2348810496 L_TP_BDC_FD_L_UWB_BLE_MST_F_0004 "L_TP_BDC_FD_L_UWB_BLE_MST_FD_Byte17";
BA_ "Version" SG_ 2348810496 L_TP_BDC_FD_L_UWB_BLE_MST_F_0005 "23.01.02";
BA_ "NetworkRequestHoldingTime" SG_ 2348810496 L_TP_BDC_FD_L_UWB_BLE_MST_F_0005 5000;
BA_ "NetworkRequest" SG_ 2348810496 L_TP_BDC_FD_L_UWB_BLE_MST_F_0005 0;
BA_ "UserSigValidity" SG_ 2348810496 L_TP_BDC_FD_L_UWB_BLE_MST_F_0005 0;
BA_ "UsrSigPurpose" SG_ 2348810496 L_TP_BDC_FD_L_UWB_BLE_MST_F_0005 9;
BA_ "Description" SG_ 2348810496 L_TP_BDC_FD_L_UWB_BLE_MST_F_0005 "TP Index : 270";
BA_ "SystemSignalLongSymbol" SG_ 2348810496 L_TP_BDC_FD_L_UWB_BLE_MST_F_0005 "L_TP_BDC_FD_L_UWB_BLE_MST_FD_Byte18";
BA_ "Version" SG_ 2348810496 L_TP_BDC_FD_L_UWB_BLE_MST_F_0006 "23.01.02";
BA_ "NetworkRequestHoldingTime" SG_ 2348810496 L_TP_BDC_FD_L_UWB_BLE_MST_F_0006 5000;
BA_ "NetworkRequest" SG_ 2348810496 L_TP_BDC_FD_L_UWB_BLE_MST_F_0006 0;
BA_ "UserSigValidity" SG_ 2348810496 L_TP_BDC_FD_L_UWB_BLE_MST_F_0006 0;
BA_ "UsrSigPurpose" SG_ 2348810496 L_TP_BDC_FD_L_UWB_BLE_MST_F_0006 9;
BA_ "Description" SG_ 2348810496 L_TP_BDC_FD_L_UWB_BLE_MST_F_0006 "TP Index : 270";
BA_ "SystemSignalLongSymbol" SG_ 2348810496 L_TP_BDC_FD_L_UWB_BLE_MST_F_0006 "L_TP_BDC_FD_L_UWB_BLE_MST_FD_Byte19";
BA_ "Version" SG_ 2348810496 L_TP_BDC_FD_L_UWB_BLE_MST_F_0007 "23.01.02";
BA_ "NetworkRequestHoldingTime" SG_ 2348810496 L_TP_BDC_FD_L_UWB_BLE_MST_F_0007 5000;
BA_ "NetworkRequest" SG_ 2348810496 L_TP_BDC_FD_L_UWB_BLE_MST_F_0007 0;
BA_ "UserSigValidity" SG_ 2348810496 L_TP_BDC_FD_L_UWB_BLE_MST_F_0007 0;
BA_ "UsrSigPurpose" SG_ 2348810496 L_TP_BDC_FD_L_UWB_BLE_MST_F_0007 9;
BA_ "Description" SG_ 2348810496 L_TP_BDC_FD_L_UWB_BLE_MST_F_0007 "TP Index : 270";
BA_ "SystemSignalLongSymbol" SG_ 2348810496 L_TP_BDC_FD_L_UWB_BLE_MST_F_0007 "L_TP_BDC_FD_L_UWB_BLE_MST_FD_Byte2";
BA_ "Version" SG_ 2348810496 L_TP_BDC_FD_L_UWB_BLE_MST_F_0008 "23.01.02";
BA_ "NetworkRequestHoldingTime" SG_ 2348810496 L_TP_BDC_FD_L_UWB_BLE_MST_F_0008 5000;
BA_ "NetworkRequest" SG_ 2348810496 L_TP_BDC_FD_L_UWB_BLE_MST_F_0008 0;
BA_ "UserSigValidity" SG_ 2348810496 L_TP_BDC_FD_L_UWB_BLE_MST_F_0008 0;
BA_ "UsrSigPurpose" SG_ 2348810496 L_TP_BDC_FD_L_UWB_BLE_MST_F_0008 9;
BA_ "Description" SG_ 2348810496 L_TP_BDC_FD_L_UWB_BLE_MST_F_0008 "TP Index : 270";
BA_ "SystemSignalLongSymbol" SG_ 2348810496 L_TP_BDC_FD_L_UWB_BLE_MST_F_0008 "L_TP_BDC_FD_L_UWB_BLE_MST_FD_Byte20";
BA_ "Version" SG_ 2348810496 L_TP_BDC_FD_L_UWB_BLE_MST_F_0009 "23.01.02";
BA_ "NetworkRequestHoldingTime" SG_ 2348810496 L_TP_BDC_FD_L_UWB_BLE_MST_F_0009 5000;
BA_ "NetworkRequest" SG_ 2348810496 L_TP_BDC_FD_L_UWB_BLE_MST_F_0009 0;
BA_ "UserSigValidity" SG_ 2348810496 L_TP_BDC_FD_L_UWB_BLE_MST_F_0009 0;
BA_ "UsrSigPurpose" SG_ 2348810496 L_TP_BDC_FD_L_UWB_BLE_MST_F_0009 9;
BA_ "Description" SG_ 2348810496 L_TP_BDC_FD_L_UWB_BLE_MST_F_0009 "TP Index : 270";
BA_ "SystemSignalLongSymbol" SG_ 2348810496 L_TP_BDC_FD_L_UWB_BLE_MST_F_0009 "L_TP_BDC_FD_L_UWB_BLE_MST_FD_Byte21";
BA_ "Version" SG_ 2348810496 L_TP_BDC_FD_L_UWB_BLE_MST_F_0010 "23.01.02";
BA_ "NetworkRequestHoldingTime" SG_ 2348810496 L_TP_BDC_FD_L_UWB_BLE_MST_F_0010 5000;
BA_ "NetworkRequest" SG_ 2348810496 L_TP_BDC_FD_L_UWB_BLE_MST_F_0010 0;
BA_ "UserSigValidity" SG_ 2348810496 L_TP_BDC_FD_L_UWB_BLE_MST_F_0010 0;
BA_ "UsrSigPurpose" SG_ 2348810496 L_TP_BDC_FD_L_UWB_BLE_MST_F_0010 9;
BA_ "Description" SG_ 2348810496 L_TP_BDC_FD_L_UWB_BLE_MST_F_0010 "TP Index : 270";
BA_ "SystemSignalLongSymbol" SG_ 2348810496 L_TP_BDC_FD_L_UWB_BLE_MST_F_0010 "L_TP_BDC_FD_L_UWB_BLE_MST_FD_Byte22";
BA_ "Version" SG_ 2348810496 L_TP_BDC_FD_L_UWB_BLE_MST_F_0011 "23.01.02";
BA_ "NetworkRequestHoldingTime" SG_ 2348810496 L_TP_BDC_FD_L_UWB_BLE_MST_F_0011 5000;
BA_ "NetworkRequest" SG_ 2348810496 L_TP_BDC_FD_L_UWB_BLE_MST_F_0011 0;
BA_ "UserSigValidity" SG_ 2348810496 L_TP_BDC_FD_L_UWB_BLE_MST_F_0011 0;
BA_ "UsrSigPurpose" SG_ 2348810496 L_TP_BDC_FD_L_UWB_BLE_MST_F_0011 9;
BA_ "Description" SG_ 2348810496 L_TP_BDC_FD_L_UWB_BLE_MST_F_0011 "TP Index : 270";
BA_ "SystemSignalLongSymbol" SG_ 2348810496 L_TP_BDC_FD_L_UWB_BLE_MST_F_0011 "L_TP_BDC_FD_L_UWB_BLE_MST_FD_Byte23";
BA_ "Version" SG_ 2348810496 L_TP_BDC_FD_L_UWB_BLE_MST_F_0012 "23.01.02";
BA_ "NetworkRequestHoldingTime" SG_ 2348810496 L_TP_BDC_FD_L_UWB_BLE_MST_F_0012 5000;
BA_ "NetworkRequest" SG_ 2348810496 L_TP_BDC_FD_L_UWB_BLE_MST_F_0012 0;
BA_ "UserSigValidity" SG_ 2348810496 L_TP_BDC_FD_L_UWB_BLE_MST_F_0012 0;
BA_ "UsrSigPurpose" SG_ 2348810496 L_TP_BDC_FD_L_UWB_BLE_MST_F_0012 9;
BA_ "Description" SG_ 2348810496 L_TP_BDC_FD_L_UWB_BLE_MST_F_0012 "TP Index : 270";
BA_ "SystemSignalLongSymbol" SG_ 2348810496 L_TP_BDC_FD_L_UWB_BLE_MST_F_0012 "L_TP_BDC_FD_L_UWB_BLE_MST_FD_Byte24";
BA_ "Version" SG_ 2348810496 L_TP_BDC_FD_L_UWB_BLE_MST_F_0013 "23.01.02";
BA_ "NetworkRequestHoldingTime" SG_ 2348810496 L_TP_BDC_FD_L_UWB_BLE_MST_F_0013 5000;
BA_ "NetworkRequest" SG_ 2348810496 L_TP_BDC_FD_L_UWB_BLE_MST_F_0013 0;
BA_ "UserSigValidity" SG_ 2348810496 L_TP_BDC_FD_L_UWB_BLE_MST_F_0013 0;
BA_ "UsrSigPurpose" SG_ 2348810496 L_TP_BDC_FD_L_UWB_BLE_MST_F_0013 9;
BA_ "Description" SG_ 2348810496 L_TP_BDC_FD_L_UWB_BLE_MST_F_0013 "TP Index : 270";
BA_ "SystemSignalLongSymbol" SG_ 2348810496 L_TP_BDC_FD_L_UWB_BLE_MST_F_0013 "L_TP_BDC_FD_L_UWB_BLE_MST_FD_Byte25";
BA_ "Version" SG_ 2348810496 L_TP_BDC_FD_L_UWB_BLE_MST_F_0014 "23.01.02";
BA_ "NetworkRequestHoldingTime" SG_ 2348810496 L_TP_BDC_FD_L_UWB_BLE_MST_F_0014 5000;
BA_ "NetworkRequest" SG_ 2348810496 L_TP_BDC_FD_L_UWB_BLE_MST_F_0014 0;
BA_ "UserSigValidity" SG_ 2348810496 L_TP_BDC_FD_L_UWB_BLE_MST_F_0014 0;
BA_ "UsrSigPurpose" SG_ 2348810496 L_TP_BDC_FD_L_UWB_BLE_MST_F_0014 9;
BA_ "Description" SG_ 2348810496 L_TP_BDC_FD_L_UWB_BLE_MST_F_0014 "TP Index : 270";
BA_ "SystemSignalLongSymbol" SG_ 2348810496 L_TP_BDC_FD_L_UWB_BLE_MST_F_0014 "L_TP_BDC_FD_L_UWB_BLE_MST_FD_Byte26";
BA_ "Version" SG_ 2348810496 L_TP_BDC_FD_L_UWB_BLE_MST_F_0015 "23.01.02";
BA_ "NetworkRequestHoldingTime" SG_ 2348810496 L_TP_BDC_FD_L_UWB_BLE_MST_F_0015 5000;
BA_ "NetworkRequest" SG_ 2348810496 L_TP_BDC_FD_L_UWB_BLE_MST_F_0015 0;
BA_ "UserSigValidity" SG_ 2348810496 L_TP_BDC_FD_L_UWB_BLE_MST_F_0015 0;
BA_ "UsrSigPurpose" SG_ 2348810496 L_TP_BDC_FD_L_UWB_BLE_MST_F_0015 9;
BA_ "Description" SG_ 2348810496 L_TP_BDC_FD_L_UWB_BLE_MST_F_0015 "TP Index : 270";
BA_ "SystemSignalLongSymbol" SG_ 2348810496 L_TP_BDC_FD_L_UWB_BLE_MST_F_0015 "L_TP_BDC_FD_L_UWB_BLE_MST_FD_Byte27";
BA_ "Version" SG_ 2348810496 L_TP_BDC_FD_L_UWB_BLE_MST_F_0016 "23.01.02";
BA_ "NetworkRequestHoldingTime" SG_ 2348810496 L_TP_BDC_FD_L_UWB_BLE_MST_F_0016 5000;
BA_ "NetworkRequest" SG_ 2348810496 L_TP_BDC_FD_L_UWB_BLE_MST_F_0016 0;
BA_ "UserSigValidity" SG_ 2348810496 L_TP_BDC_FD_L_UWB_BLE_MST_F_0016 0;
BA_ "UsrSigPurpose" SG_ 2348810496 L_TP_BDC_FD_L_UWB_BLE_MST_F_0016 9;
BA_ "Description" SG_ 2348810496 L_TP_BDC_FD_L_UWB_BLE_MST_F_0016 "TP Index : 270";
BA_ "SystemSignalLongSymbol" SG_ 2348810496 L_TP_BDC_FD_L_UWB_BLE_MST_F_0016 "L_TP_BDC_FD_L_UWB_BLE_MST_FD_Byte28";
BA_ "Version" SG_ 2348810496 L_TP_BDC_FD_L_UWB_BLE_MST_F_0017 "23.01.02";
BA_ "NetworkRequestHoldingTime" SG_ 2348810496 L_TP_BDC_FD_L_UWB_BLE_MST_F_0017 5000;
BA_ "NetworkRequest" SG_ 2348810496 L_TP_BDC_FD_L_UWB_BLE_MST_F_0017 0;
BA_ "UserSigValidity" SG_ 2348810496 L_TP_BDC_FD_L_UWB_BLE_MST_F_0017 0;
BA_ "UsrSigPurpose" SG_ 2348810496 L_TP_BDC_FD_L_UWB_BLE_MST_F_0017 9;
BA_ "Description" SG_ 2348810496 L_TP_BDC_FD_L_UWB_BLE_MST_F_0017 "TP Index : 270";
BA_ "SystemSignalLongSymbol" SG_ 2348810496 L_TP_BDC_FD_L_UWB_BLE_MST_F_0017 "L_TP_BDC_FD_L_UWB_BLE_MST_FD_Byte29";
BA_ "Version" SG_ 2348810496 L_TP_BDC_FD_L_UWB_BLE_MST_F_0018 "23.01.02";
BA_ "NetworkRequestHoldingTime" SG_ 2348810496 L_TP_BDC_FD_L_UWB_BLE_MST_F_0018 5000;
BA_ "NetworkRequest" SG_ 2348810496 L_TP_BDC_FD_L_UWB_BLE_MST_F_0018 0;
BA_ "UserSigValidity" SG_ 2348810496 L_TP_BDC_FD_L_UWB_BLE_MST_F_0018 0;
BA_ "UsrSigPurpose" SG_ 2348810496 L_TP_BDC_FD_L_UWB_BLE_MST_F_0018 9;
BA_ "Description" SG_ 2348810496 L_TP_BDC_FD_L_UWB_BLE_MST_F_0018 "TP Index : 270";
BA_ "SystemSignalLongSymbol" SG_ 2348810496 L_TP_BDC_FD_L_UWB_BLE_MST_F_0018 "L_TP_BDC_FD_L_UWB_BLE_MST_FD_Byte3";
BA_ "Version" SG_ 2348810496 L_TP_BDC_FD_L_UWB_BLE_MST_F_0019 "23.01.02";
BA_ "NetworkRequestHoldingTime" SG_ 2348810496 L_TP_BDC_FD_L_UWB_BLE_MST_F_0019 5000;
BA_ "NetworkRequest" SG_ 2348810496 L_TP_BDC_FD_L_UWB_BLE_MST_F_0019 0;
BA_ "UserSigValidity" SG_ 2348810496 L_TP_BDC_FD_L_UWB_BLE_MST_F_0019 0;
BA_ "UsrSigPurpose" SG_ 2348810496 L_TP_BDC_FD_L_UWB_BLE_MST_F_0019 9;
BA_ "Description" SG_ 2348810496 L_TP_BDC_FD_L_UWB_BLE_MST_F_0019 "TP Index : 270";
BA_ "SystemSignalLongSymbol" SG_ 2348810496 L_TP_BDC_FD_L_UWB_BLE_MST_F_0019 "L_TP_BDC_FD_L_UWB_BLE_MST_FD_Byte30";
BA_ "Version" SG_ 2348810496 L_TP_BDC_FD_L_UWB_BLE_MST_F_0020 "23.01.02";
BA_ "NetworkRequestHoldingTime" SG_ 2348810496 L_TP_BDC_FD_L_UWB_BLE_MST_F_0020 5000;
BA_ "NetworkRequest" SG_ 2348810496 L_TP_BDC_FD_L_UWB_BLE_MST_F_0020 0;
BA_ "UserSigValidity" SG_ 2348810496 L_TP_BDC_FD_L_UWB_BLE_MST_F_0020 0;
BA_ "UsrSigPurpose" SG_ 2348810496 L_TP_BDC_FD_L_UWB_BLE_MST_F_0020 9;
BA_ "Description" SG_ 2348810496 L_TP_BDC_FD_L_UWB_BLE_MST_F_0020 "TP Index : 270";
BA_ "SystemSignalLongSymbol" SG_ 2348810496 L_TP_BDC_FD_L_UWB_BLE_MST_F_0020 "L_TP_BDC_FD_L_UWB_BLE_MST_FD_Byte31";
BA_ "Version" SG_ 2348810496 L_TP_BDC_FD_L_UWB_BLE_MST_F_0021 "23.01.02";
BA_ "NetworkRequestHoldingTime" SG_ 2348810496 L_TP_BDC_FD_L_UWB_BLE_MST_F_0021 5000;
BA_ "NetworkRequest" SG_ 2348810496 L_TP_BDC_FD_L_UWB_BLE_MST_F_0021 0;
BA_ "UserSigValidity" SG_ 2348810496 L_TP_BDC_FD_L_UWB_BLE_MST_F_0021 0;
BA_ "UsrSigPurpose" SG_ 2348810496 L_TP_BDC_FD_L_UWB_BLE_MST_F_0021 9;
BA_ "Description" SG_ 2348810496 L_TP_BDC_FD_L_UWB_BLE_MST_F_0021 "TP Index : 270";
BA_ "SystemSignalLongSymbol" SG_ 2348810496 L_TP_BDC_FD_L_UWB_BLE_MST_F_0021 "L_TP_BDC_FD_L_UWB_BLE_MST_FD_Byte4";
BA_ "Version" SG_ 2348810496 L_TP_BDC_FD_L_UWB_BLE_MST_F_0022 "23.01.02";
BA_ "NetworkRequestHoldingTime" SG_ 2348810496 L_TP_BDC_FD_L_UWB_BLE_MST_F_0022 5000;
BA_ "NetworkRequest" SG_ 2348810496 L_TP_BDC_FD_L_UWB_BLE_MST_F_0022 0;
BA_ "UserSigValidity" SG_ 2348810496 L_TP_BDC_FD_L_UWB_BLE_MST_F_0022 0;
BA_ "UsrSigPurpose" SG_ 2348810496 L_TP_BDC_FD_L_UWB_BLE_MST_F_0022 9;
BA_ "Description" SG_ 2348810496 L_TP_BDC_FD_L_UWB_BLE_MST_F_0022 "TP Index : 270";
BA_ "SystemSignalLongSymbol" SG_ 2348810496 L_TP_BDC_FD_L_UWB_BLE_MST_F_0022 "L_TP_BDC_FD_L_UWB_BLE_MST_FD_Byte5";
BA_ "Version" SG_ 2348810496 L_TP_BDC_FD_L_UWB_BLE_MST_F_0023 "23.01.02";
BA_ "NetworkRequestHoldingTime" SG_ 2348810496 L_TP_BDC_FD_L_UWB_BLE_MST_F_0023 5000;
BA_ "NetworkRequest" SG_ 2348810496 L_TP_BDC_FD_L_UWB_BLE_MST_F_0023 0;
BA_ "UserSigValidity" SG_ 2348810496 L_TP_BDC_FD_L_UWB_BLE_MST_F_0023 0;
BA_ "UsrSigPurpose" SG_ 2348810496 L_TP_BDC_FD_L_UWB_BLE_MST_F_0023 9;
BA_ "Description" SG_ 2348810496 L_TP_BDC_FD_L_UWB_BLE_MST_F_0023 "TP Index : 270";
BA_ "SystemSignalLongSymbol" SG_ 2348810496 L_TP_BDC_FD_L_UWB_BLE_MST_F_0023 "L_TP_BDC_FD_L_UWB_BLE_MST_FD_Byte6";
BA_ "Version" SG_ 2348810496 L_TP_BDC_FD_L_UWB_BLE_MST_F_0024 "23.01.02";
BA_ "NetworkRequestHoldingTime" SG_ 2348810496 L_TP_BDC_FD_L_UWB_BLE_MST_F_0024 5000;
BA_ "NetworkRequest" SG_ 2348810496 L_TP_BDC_FD_L_UWB_BLE_MST_F_0024 0;
BA_ "UserSigValidity" SG_ 2348810496 L_TP_BDC_FD_L_UWB_BLE_MST_F_0024 0;
BA_ "UsrSigPurpose" SG_ 2348810496 L_TP_BDC_FD_L_UWB_BLE_MST_F_0024 9;
BA_ "Description" SG_ 2348810496 L_TP_BDC_FD_L_UWB_BLE_MST_F_0024 "TP Index : 270";
BA_ "SystemSignalLongSymbol" SG_ 2348810496 L_TP_BDC_FD_L_UWB_BLE_MST_F_0024 "L_TP_BDC_FD_L_UWB_BLE_MST_FD_Byte7";
BA_ "Version" SG_ 2348810496 L_TP_BDC_FD_L_UWB_BLE_MST_F_0025 "23.01.02";
BA_ "NetworkRequestHoldingTime" SG_ 2348810496 L_TP_BDC_FD_L_UWB_BLE_MST_F_0025 5000;
BA_ "NetworkRequest" SG_ 2348810496 L_TP_BDC_FD_L_UWB_BLE_MST_F_0025 0;
BA_ "UserSigValidity" SG_ 2348810496 L_TP_BDC_FD_L_UWB_BLE_MST_F_0025 0;
BA_ "UsrSigPurpose" SG_ 2348810496 L_TP_BDC_FD_L_UWB_BLE_MST_F_0025 9;
BA_ "Description" SG_ 2348810496 L_TP_BDC_FD_L_UWB_BLE_MST_F_0025 "TP Index : 270";
BA_ "SystemSignalLongSymbol" SG_ 2348810496 L_TP_BDC_FD_L_UWB_BLE_MST_F_0025 "L_TP_BDC_FD_L_UWB_BLE_MST_FD_Byte8";
BA_ "Version" SG_ 2348810496 L_TP_BDC_FD_L_UWB_BLE_MST_F_0026 "23.01.02";
BA_ "NetworkRequestHoldingTime" SG_ 2348810496 L_TP_BDC_FD_L_UWB_BLE_MST_F_0026 5000;
BA_ "NetworkRequest" SG_ 2348810496 L_TP_BDC_FD_L_UWB_BLE_MST_F_0026 0;
BA_ "UserSigValidity" SG_ 2348810496 L_TP_BDC_FD_L_UWB_BLE_MST_F_0026 0;
BA_ "UsrSigPurpose" SG_ 2348810496 L_TP_BDC_FD_L_UWB_BLE_MST_F_0026 9;
BA_ "Description" SG_ 2348810496 L_TP_BDC_FD_L_UWB_BLE_MST_F_0026 "TP Index : 270";
BA_ "SystemSignalLongSymbol" SG_ 2348810496 L_TP_BDC_FD_L_UWB_BLE_MST_F_0026 "L_TP_BDC_FD_L_UWB_BLE_MST_FD_Byte9";
BA_ "Version" SG_ 2348810496 L_TP_BDC_FD_L_UWB_BLE_MST_F_0027 "23.01.02";
BA_ "NetworkRequestHoldingTime" SG_ 2348810496 L_TP_BDC_FD_L_UWB_BLE_MST_F_0027 5000;
BA_ "NetworkRequest" SG_ 2348810496 L_TP_BDC_FD_L_UWB_BLE_MST_F_0027 0;
BA_ "UserSigValidity" SG_ 2348810496 L_TP_BDC_FD_L_UWB_BLE_MST_F_0027 0;
BA_ "UsrSigPurpose" SG_ 2348810496 L_TP_BDC_FD_L_UWB_BLE_MST_F_0027 9;
BA_ "Description" SG_ 2348810496 L_TP_BDC_FD_L_UWB_BLE_MST_F_0027 "TP Index : 270";
BA_ "SystemSignalLongSymbol" SG_ 2348810496 L_TP_BDC_FD_L_UWB_BLE_MST_F_0027 "L_TP_BDC_FD_L_UWB_BLE_MST_FD_Byte1";
BA_ "Version" SG_ 2348810496 L_TP_BDC_FD_L_UWB_BLE_MST_F_0028 "23.01.02";
BA_ "NetworkRequestHoldingTime" SG_ 2348810496 L_TP_BDC_FD_L_UWB_BLE_MST_F_0028 5000;
BA_ "NetworkRequest" SG_ 2348810496 L_TP_BDC_FD_L_UWB_BLE_MST_F_0028 0;
BA_ "UserSigValidity" SG_ 2348810496 L_TP_BDC_FD_L_UWB_BLE_MST_F_0028 0;
BA_ "UsrSigPurpose" SG_ 2348810496 L_TP_BDC_FD_L_UWB_BLE_MST_F_0028 9;
BA_ "Description" SG_ 2348810496 L_TP_BDC_FD_L_UWB_BLE_MST_F_0028 "TP Index : 270";
BA_ "SystemSignalLongSymbol" SG_ 2348810496 L_TP_BDC_FD_L_UWB_BLE_MST_F_0028 "L_TP_BDC_FD_L_UWB_BLE_MST_FD_Byte10";
BA_ "Version" SG_ 2348810496 L_TP_BDC_FD_L_UWB_BLE_MST_F_0029 "23.01.02";
BA_ "NetworkRequestHoldingTime" SG_ 2348810496 L_TP_BDC_FD_L_UWB_BLE_MST_F_0029 5000;
BA_ "NetworkRequest" SG_ 2348810496 L_TP_BDC_FD_L_UWB_BLE_MST_F_0029 0;
BA_ "UserSigValidity" SG_ 2348810496 L_TP_BDC_FD_L_UWB_BLE_MST_F_0029 0;
BA_ "UsrSigPurpose" SG_ 2348810496 L_TP_BDC_FD_L_UWB_BLE_MST_F_0029 9;
BA_ "Description" SG_ 2348810496 L_TP_BDC_FD_L_UWB_BLE_MST_F_0029 "TP Index : 270";
BA_ "SystemSignalLongSymbol" SG_ 2348810496 L_TP_BDC_FD_L_UWB_BLE_MST_F_0029 "L_TP_BDC_FD_L_UWB_BLE_MST_FD_Byte11";
BA_ "Version" SG_ 2348810496 L_TP_BDC_FD_L_UWB_BLE_MST_F_0030 "23.01.02";
BA_ "NetworkRequestHoldingTime" SG_ 2348810496 L_TP_BDC_FD_L_UWB_BLE_MST_F_0030 5000;
BA_ "NetworkRequest" SG_ 2348810496 L_TP_BDC_FD_L_UWB_BLE_MST_F_0030 0;
BA_ "UserSigValidity" SG_ 2348810496 L_TP_BDC_FD_L_UWB_BLE_MST_F_0030 0;
BA_ "UsrSigPurpose" SG_ 2348810496 L_TP_BDC_FD_L_UWB_BLE_MST_F_0030 9;
BA_ "Description" SG_ 2348810496 L_TP_BDC_FD_L_UWB_BLE_MST_F_0030 "TP Index : 270";
BA_ "SystemSignalLongSymbol" SG_ 2348810496 L_TP_BDC_FD_L_UWB_BLE_MST_F_0030 "L_TP_BDC_FD_L_UWB_BLE_MST_FD_Byte12";
BA_ "Version" SG_ 2214592645 DHRL_Dvp_Msg "23.06.01";
BA_ "UserSigValidity" SG_ 2214592645 DHRL_Dvp_Msg 0;
BA_ "GenSigSendType" SG_ 2214592645 DHRL_Dvp_Msg 2;
BA_ "Version" SG_ 2214592644 DHL_Dvp_Msg "23.01.02";
BA_ "UserSigValidity" SG_ 2214592644 DHL_Dvp_Msg 0;
BA_ "GenSigSendType" SG_ 2214592644 DHL_Dvp_Msg 2;
BA_ "Version" SG_ 2214592641 L_DHRL_FD_Crc1Val "23.06.01";
BA_ "UserSigValidity" SG_ 2214592641 L_DHRL_FD_Crc1Val 3;
BA_ "GenSigStartValue" SG_ 2214592641 L_DHRL_FD_Crc1Val 65535;
BA_ "GenSigSendType" SG_ 2214592641 L_DHRL_FD_Crc1Val 4;
BA_ "Description" SG_ 2214592641 L_DHRL_FD_Crc1Val "The data area for CRC calculation is based on the data length (DLC) of the message DB.

The CRC shall be calculated over the entire data block (excluding the CRC bytes) including the user data, alive counter and Data ID



- CRC Polynomial (0x1021) , Ini";
BA_ "Version" SG_ 2214592641 L_DHRL_FD_AlvCnt1Val "23.06.01";
BA_ "UserSigValidity" SG_ 2214592641 L_DHRL_FD_AlvCnt1Val 3;
BA_ "GenSigSendType" SG_ 2214592641 L_DHRL_FD_AlvCnt1Val 4;
BA_ "Description" SG_ 2214592641 L_DHRL_FD_AlvCnt1Val "For the first transmission request for a data element the counter shall be initialized with 0 and shall be incremented by 1 for every subsequent send request. 

When the counter reaches the maximum value(0xFF), then it shall restart with 0 for the next s";
BA_ "Version" SG_ 2214592641 DHRL_NFCDetected "23.06.01";
BA_ "UserSigValidity" SG_ 2214592641 DHRL_NFCDetected 0;
BA_ "GenSigSendType" SG_ 2214592641 DHRL_NFCDetected 4;
BA_ "Version" SG_ 2214592641 DHRL_WlcmLt_Sta "23.06.01";
BA_ "UserSigValidity" SG_ 2214592641 DHRL_WlcmLt_Sta 0;
BA_ "GenSigSendType" SG_ 2214592641 DHRL_WlcmLt_Sta 4;
BA_ "Version" SG_ 2214592641 DHRL_NFCReset_Sta "23.06.01";
BA_ "UserSigValidity" SG_ 2214592641 DHRL_NFCReset_Sta 0;
BA_ "GenSigSendType" SG_ 2214592641 DHRL_NFCReset_Sta 4;
BA_ "Version" SG_ 2214592640 L_DHL_FD_Crc1Val "23.01.02";
BA_ "UserSigValidity" SG_ 2214592640 L_DHL_FD_Crc1Val 3;
BA_ "GenSigStartValue" SG_ 2214592640 L_DHL_FD_Crc1Val 65535;
BA_ "GenSigSendType" SG_ 2214592640 L_DHL_FD_Crc1Val 4;
BA_ "Description" SG_ 2214592640 L_DHL_FD_Crc1Val "The data area for CRC calculation is based on the data length (DLC) of the message DB.

The CRC shall be calculated over the entire data block (excluding the CRC bytes) including the user data, alive counter and Data ID



- CRC Polynomial (0x1021) , Ini";
BA_ "Version" SG_ 2214592640 L_DHL_FD_AlvCnt1Val "23.01.02";
BA_ "UserSigValidity" SG_ 2214592640 L_DHL_FD_AlvCnt1Val 3;
BA_ "GenSigSendType" SG_ 2214592640 L_DHL_FD_AlvCnt1Val 4;
BA_ "Description" SG_ 2214592640 L_DHL_FD_AlvCnt1Val "For the first transmission request for a data element the counter shall be initialized with 0 and shall be incremented by 1 for every subsequent send request. 

When the counter reaches the maximum value(0xFF), then it shall restart with 0 for the next s";
BA_ "Version" SG_ 2214592640 DHL_NFCDetected "23.01.02";
BA_ "UserSigValidity" SG_ 2214592640 DHL_NFCDetected 0;
BA_ "GenSigSendType" SG_ 2214592640 DHL_NFCDetected 4;
BA_ "Version" SG_ 2214592640 DHL_WlcmLt_Sta "23.01.02";
BA_ "UserSigValidity" SG_ 2214592640 DHL_WlcmLt_Sta 0;
BA_ "GenSigSendType" SG_ 2214592640 DHL_WlcmLt_Sta 4;
BA_ "Version" SG_ 2214592640 DHL_NFCReset_Sta "23.01.02";
BA_ "UserSigValidity" SG_ 2214592640 DHL_NFCReset_Sta 0;
BA_ "GenSigSendType" SG_ 2214592640 DHL_NFCReset_Sta 4;
BA_ "Version" SG_ 2529538305 L_UWB_RL_FD_Crc5Val "24.07.05";
BA_ "RoutingFactor" SG_ 2529538305 L_UWB_RL_FD_Crc5Val 0;
BA_ "UserSigValidity" SG_ 2529538305 L_UWB_RL_FD_Crc5Val 3;
BA_ "GenSigStartValue" SG_ 2529538305 L_UWB_RL_FD_Crc5Val 65535;
BA_ "GenSigSendType" SG_ 2529538305 L_UWB_RL_FD_Crc5Val 2;
BA_ "Description" SG_ 2529538305 L_UWB_RL_FD_Crc5Val "The data area for CRC calculation is based on the data length (DLC) of the message DB.

The CRC shall be calculated over the entire data block (excluding the CRC bytes) including the user data, alive counter and Data ID



- CRC Polynomial (0x1021) , Ini";
BA_ "Version" SG_ 2529538305 L_UWB_RL_FD_AlvCnt5Val "24.07.05";
BA_ "RoutingFactor" SG_ 2529538305 L_UWB_RL_FD_AlvCnt5Val 0;
BA_ "UserSigValidity" SG_ 2529538305 L_UWB_RL_FD_AlvCnt5Val 3;
BA_ "GenSigSendType" SG_ 2529538305 L_UWB_RL_FD_AlvCnt5Val 2;
BA_ "Description" SG_ 2529538305 L_UWB_RL_FD_AlvCnt5Val "For the first transmission request for a data element the counter shall be initialized with 0 and shall be incremented by 1 for every subsequent send request. 

When the counter reaches the maximum value(0xFF), then it shall restart with 0 for the next s";
BA_ "Version" SG_ 2529538305 RL_SWID_3_IVD_2 "24.07.05";
BA_ "RoutingFactor" SG_ 2529538305 RL_SWID_3_IVD_2 0;
BA_ "UserSigValidity" SG_ 2529538305 RL_SWID_3_IVD_2 0;
BA_ "GenSigSendType" SG_ 2529538305 RL_SWID_3_IVD_2 2;
BA_ "Version" SG_ 2533736705 L_UWB_TRNK_FD_Crc5Val "24.07.05";
BA_ "RoutingFactor" SG_ 2533736705 L_UWB_TRNK_FD_Crc5Val 0;
BA_ "UserSigValidity" SG_ 2533736705 L_UWB_TRNK_FD_Crc5Val 3;
BA_ "GenSigStartValue" SG_ 2533736705 L_UWB_TRNK_FD_Crc5Val 65535;
BA_ "GenSigSendType" SG_ 2533736705 L_UWB_TRNK_FD_Crc5Val 2;
BA_ "Description" SG_ 2533736705 L_UWB_TRNK_FD_Crc5Val "The data area for CRC calculation is based on the data length (DLC) of the message DB.

The CRC shall be calculated over the entire data block (excluding the CRC bytes) including the user data, alive counter and Data ID



- CRC Polynomial (0x1021) , Ini";
BA_ "Version" SG_ 2533736705 L_UWB_TRNK_FD_AlvCnt5Val "24.07.05";
BA_ "RoutingFactor" SG_ 2533736705 L_UWB_TRNK_FD_AlvCnt5Val 0;
BA_ "UserSigValidity" SG_ 2533736705 L_UWB_TRNK_FD_AlvCnt5Val 3;
BA_ "GenSigSendType" SG_ 2533736705 L_UWB_TRNK_FD_AlvCnt5Val 2;
BA_ "Description" SG_ 2533736705 L_UWB_TRNK_FD_AlvCnt5Val "For the first transmission request for a data element the counter shall be initialized with 0 and shall be incremented by 1 for every subsequent send request. 

When the counter reaches the maximum value(0xFF), then it shall restart with 0 for the next s";
BA_ "Version" SG_ 2533736705 TRNK_SWID_3_IVD_2 "24.07.05";
BA_ "RoutingFactor" SG_ 2533736705 TRNK_SWID_3_IVD_2 0;
BA_ "UserSigValidity" SG_ 2533736705 TRNK_SWID_3_IVD_2 0;
BA_ "GenSigSendType" SG_ 2533736705 TRNK_SWID_3_IVD_2 2;
BA_ "Version" SG_ 2214592703 SLV_Dvp_Data "23.01.02";
BA_ "UserSigValidity" SG_ 2214592703 SLV_Dvp_Data 0;
BA_ "GenSigSendType" SG_ 2214592703 SLV_Dvp_Data 2;
BA_ "Version" SG_ 2214592698 MST_Dvp_Data_02 "23.07.07";
BA_ "UserSigValidity" SG_ 2214592698 MST_Dvp_Data_02 0;
BA_ "GenSigSendType" SG_ 2214592698 MST_Dvp_Data_02 2;
BA_ "Version" SG_ 2214592699 MST_Dvp_Data_03 "23.07.07";
BA_ "UserSigValidity" SG_ 2214592699 MST_Dvp_Data_03 0;
BA_ "GenSigSendType" SG_ 2214592699 MST_Dvp_Data_03 2;
BA_ "Version" SG_ 2214592694 L_UWB_BLE_SLV_FD_Crc7Val "23.01.02";
BA_ "UserSigValidity" SG_ 2214592694 L_UWB_BLE_SLV_FD_Crc7Val 3;
BA_ "GenSigStartValue" SG_ 2214592694 L_UWB_BLE_SLV_FD_Crc7Val 65535;
BA_ "GenSigSendType" SG_ 2214592694 L_UWB_BLE_SLV_FD_Crc7Val 4;
BA_ "Description" SG_ 2214592694 L_UWB_BLE_SLV_FD_Crc7Val "The data area for CRC calculation is based on the data length (DLC) of the message DB.

The CRC shall be calculated over the entire data block (excluding the CRC bytes) including the user data, alive counter and Data ID



- CRC Polynomial (0x1021) , Ini";
BA_ "Version" SG_ 2214592694 L_UWB_BLE_SLV_FD_AlvCnt7Val "23.01.02";
BA_ "UserSigValidity" SG_ 2214592694 L_UWB_BLE_SLV_FD_AlvCnt7Val 3;
BA_ "GenSigSendType" SG_ 2214592694 L_UWB_BLE_SLV_FD_AlvCnt7Val 4;
BA_ "Description" SG_ 2214592694 L_UWB_BLE_SLV_FD_AlvCnt7Val "For the first transmission request for a data element the counter shall be initialized with 0 and shall be incremented by 1 for every subsequent send request. 

When the counter reaches the maximum value(0xFF), then it shall restart with 0 for the next s";
BA_ "Version" SG_ 2214592694 SLV_To_MST_Enc_Data4 "23.01.02";
BA_ "UserSigValidity" SG_ 2214592694 SLV_To_MST_Enc_Data4 0;
BA_ "GenSigSendType" SG_ 2214592694 SLV_To_MST_Enc_Data4 4;
BA_ "Version" SG_ 2214592695 L_UWB_BLE_SLV_FD_Crc8Val "23.01.02";
BA_ "UserSigValidity" SG_ 2214592695 L_UWB_BLE_SLV_FD_Crc8Val 3;
BA_ "GenSigStartValue" SG_ 2214592695 L_UWB_BLE_SLV_FD_Crc8Val 65535;
BA_ "GenSigSendType" SG_ 2214592695 L_UWB_BLE_SLV_FD_Crc8Val 4;
BA_ "Description" SG_ 2214592695 L_UWB_BLE_SLV_FD_Crc8Val "The data area for CRC calculation is based on the data length (DLC) of the message DB.

The CRC shall be calculated over the entire data block (excluding the CRC bytes) including the user data, alive counter and Data ID



- CRC Polynomial (0x1021) , Ini";
BA_ "Version" SG_ 2214592695 L_UWB_BLE_SLV_FD_AlvCnt8Val "23.01.02";
BA_ "UserSigValidity" SG_ 2214592695 L_UWB_BLE_SLV_FD_AlvCnt8Val 3;
BA_ "GenSigSendType" SG_ 2214592695 L_UWB_BLE_SLV_FD_AlvCnt8Val 4;
BA_ "Description" SG_ 2214592695 L_UWB_BLE_SLV_FD_AlvCnt8Val "For the first transmission request for a data element the counter shall be initialized with 0 and shall be incremented by 1 for every subsequent send request. 

When the counter reaches the maximum value(0xFF), then it shall restart with 0 for the next s";
BA_ "Version" SG_ 2214592695 SLV_To_MST_Enc_Data5 "23.01.02";
BA_ "UserSigValidity" SG_ 2214592695 SLV_To_MST_Enc_Data5 0;
BA_ "GenSigSendType" SG_ 2214592695 SLV_To_MST_Enc_Data5 4;
BA_ "Version" SG_ 2214592692 L_UWB_BLE_SLV_FD_Crc5Val "23.01.02";
BA_ "UserSigValidity" SG_ 2214592692 L_UWB_BLE_SLV_FD_Crc5Val 3;
BA_ "GenSigStartValue" SG_ 2214592692 L_UWB_BLE_SLV_FD_Crc5Val 65535;
BA_ "GenSigSendType" SG_ 2214592692 L_UWB_BLE_SLV_FD_Crc5Val 4;
BA_ "Description" SG_ 2214592692 L_UWB_BLE_SLV_FD_Crc5Val "The data area for CRC calculation is based on the data length (DLC) of the message DB.

The CRC shall be calculated over the entire data block (excluding the CRC bytes) including the user data, alive counter and Data ID



- CRC Polynomial (0x1021) , Ini";
BA_ "Version" SG_ 2214592692 L_UWB_BLE_SLV_FD_AlvCnt5Val "23.01.02";
BA_ "UserSigValidity" SG_ 2214592692 L_UWB_BLE_SLV_FD_AlvCnt5Val 3;
BA_ "GenSigSendType" SG_ 2214592692 L_UWB_BLE_SLV_FD_AlvCnt5Val 4;
BA_ "Description" SG_ 2214592692 L_UWB_BLE_SLV_FD_AlvCnt5Val "For the first transmission request for a data element the counter shall be initialized with 0 and shall be incremented by 1 for every subsequent send request. 

When the counter reaches the maximum value(0xFF), then it shall restart with 0 for the next s";
BA_ "Version" SG_ 2214592692 SLV_To_MST_Enc_Data2 "23.01.02";
BA_ "UserSigValidity" SG_ 2214592692 SLV_To_MST_Enc_Data2 0;
BA_ "GenSigSendType" SG_ 2214592692 SLV_To_MST_Enc_Data2 4;
BA_ "Version" SG_ 2214592693 L_UWB_BLE_SLV_FD_Crc6Val "23.01.02";
BA_ "UserSigValidity" SG_ 2214592693 L_UWB_BLE_SLV_FD_Crc6Val 3;
BA_ "GenSigStartValue" SG_ 2214592693 L_UWB_BLE_SLV_FD_Crc6Val 65535;
BA_ "GenSigSendType" SG_ 2214592693 L_UWB_BLE_SLV_FD_Crc6Val 4;
BA_ "Description" SG_ 2214592693 L_UWB_BLE_SLV_FD_Crc6Val "The data area for CRC calculation is based on the data length (DLC) of the message DB.

The CRC shall be calculated over the entire data block (excluding the CRC bytes) including the user data, alive counter and Data ID



- CRC Polynomial (0x1021) , Ini";
BA_ "Version" SG_ 2214592693 L_UWB_BLE_SLV_FD_AlvCnt6Val "23.01.02";
BA_ "UserSigValidity" SG_ 2214592693 L_UWB_BLE_SLV_FD_AlvCnt6Val 3;
BA_ "GenSigSendType" SG_ 2214592693 L_UWB_BLE_SLV_FD_AlvCnt6Val 4;
BA_ "Description" SG_ 2214592693 L_UWB_BLE_SLV_FD_AlvCnt6Val "For the first transmission request for a data element the counter shall be initialized with 0 and shall be incremented by 1 for every subsequent send request. 

When the counter reaches the maximum value(0xFF), then it shall restart with 0 for the next s";
BA_ "Version" SG_ 2214592693 SLV_To_MST_Enc_Data3 "23.01.02";
BA_ "UserSigValidity" SG_ 2214592693 SLV_To_MST_Enc_Data3 0;
BA_ "GenSigSendType" SG_ 2214592693 SLV_To_MST_Enc_Data3 4;
BA_ "Version" SG_ 2214592690 L_UWB_BLE_SLV_FD_Crc3Val "23.01.02";
BA_ "UserSigValidity" SG_ 2214592690 L_UWB_BLE_SLV_FD_Crc3Val 3;
BA_ "GenSigStartValue" SG_ 2214592690 L_UWB_BLE_SLV_FD_Crc3Val 65535;
BA_ "GenSigSendType" SG_ 2214592690 L_UWB_BLE_SLV_FD_Crc3Val 2;
BA_ "Description" SG_ 2214592690 L_UWB_BLE_SLV_FD_Crc3Val "The data area for CRC calculation is based on the data length (DLC) of the message DB.

The CRC shall be calculated over the entire data block (excluding the CRC bytes) including the user data, alive counter and Data ID



- CRC Polynomial (0x1021) , Ini";
BA_ "Version" SG_ 2214592690 L_UWB_BLE_SLV_FD_AlvCnt3Val "23.01.02";
BA_ "UserSigValidity" SG_ 2214592690 L_UWB_BLE_SLV_FD_AlvCnt3Val 3;
BA_ "GenSigSendType" SG_ 2214592690 L_UWB_BLE_SLV_FD_AlvCnt3Val 2;
BA_ "Description" SG_ 2214592690 L_UWB_BLE_SLV_FD_AlvCnt3Val "For the first transmission request for a data element the counter shall be initialized with 0 and shall be incremented by 1 for every subsequent send request. 

When the counter reaches the maximum value(0xFF), then it shall restart with 0 for the next s";
BA_ "Version" SG_ 2214592690 SLV_UWB_Ranging_Enc_Result2 "24.04.06";
BA_ "UserSigValidity" SG_ 2214592690 SLV_UWB_Ranging_Enc_Result2 0;
BA_ "GenSigSendType" SG_ 2214592690 SLV_UWB_Ranging_Enc_Result2 2;
BA_ "Description" SG_ 2214592690 SLV_UWB_Ranging_Enc_Result2 "UWB Ranging Result2(Encrypted Data) with DK";
BA_ "Version" SG_ 2214592690 SLV_UWB_Ranging_Enc_Result "23.01.02";
BA_ "UserSigValidity" SG_ 2214592690 SLV_UWB_Ranging_Enc_Result 0;
BA_ "GenSigSendType" SG_ 2214592690 SLV_UWB_Ranging_Enc_Result 2;
BA_ "Version" SG_ 2214592691 L_UWB_BLE_SLV_FD_Crc4Val "23.01.02";
BA_ "UserSigValidity" SG_ 2214592691 L_UWB_BLE_SLV_FD_Crc4Val 3;
BA_ "GenSigStartValue" SG_ 2214592691 L_UWB_BLE_SLV_FD_Crc4Val 65535;
BA_ "GenSigSendType" SG_ 2214592691 L_UWB_BLE_SLV_FD_Crc4Val 4;
BA_ "Description" SG_ 2214592691 L_UWB_BLE_SLV_FD_Crc4Val "The data area for CRC calculation is based on the data length (DLC) of the message DB.

The CRC shall be calculated over the entire data block (excluding the CRC bytes) including the user data, alive counter and Data ID



- CRC Polynomial (0x1021) , Ini";
BA_ "Version" SG_ 2214592691 L_UWB_BLE_SLV_FD_AlvCnt4Val "23.01.02";
BA_ "UserSigValidity" SG_ 2214592691 L_UWB_BLE_SLV_FD_AlvCnt4Val 3;
BA_ "GenSigSendType" SG_ 2214592691 L_UWB_BLE_SLV_FD_AlvCnt4Val 4;
BA_ "Description" SG_ 2214592691 L_UWB_BLE_SLV_FD_AlvCnt4Val "For the first transmission request for a data element the counter shall be initialized with 0 and shall be incremented by 1 for every subsequent send request. 

When the counter reaches the maximum value(0xFF), then it shall restart with 0 for the next s";
BA_ "Version" SG_ 2214592691 SLV_To_MST_Enc_Data1 "23.01.02";
BA_ "UserSigValidity" SG_ 2214592691 SLV_To_MST_Enc_Data1 0;
BA_ "GenSigSendType" SG_ 2214592691 SLV_To_MST_Enc_Data1 4;
BA_ "Version" SG_ 2214592688 L_UWB_BLE_SLV_FD_Crc1Val "23.01.02";
BA_ "UserSigValidity" SG_ 2214592688 L_UWB_BLE_SLV_FD_Crc1Val 3;
BA_ "GenSigStartValue" SG_ 2214592688 L_UWB_BLE_SLV_FD_Crc1Val 65535;
BA_ "GenSigSendType" SG_ 2214592688 L_UWB_BLE_SLV_FD_Crc1Val 4;
BA_ "Description" SG_ 2214592688 L_UWB_BLE_SLV_FD_Crc1Val "The data area for CRC calculation is based on the data length (DLC) of the message DB.

The CRC shall be calculated over the entire data block (excluding the CRC bytes) including the user data, alive counter and Data ID



- CRC Polynomial (0x1021) , Ini";
BA_ "Version" SG_ 2214592688 L_UWB_BLE_SLV_FD_AlvCnt1Val "23.01.02";
BA_ "UserSigValidity" SG_ 2214592688 L_UWB_BLE_SLV_FD_AlvCnt1Val 3;
BA_ "GenSigSendType" SG_ 2214592688 L_UWB_BLE_SLV_FD_AlvCnt1Val 4;
BA_ "Description" SG_ 2214592688 L_UWB_BLE_SLV_FD_AlvCnt1Val "For the first transmission request for a data element the counter shall be initialized with 0 and shall be incremented by 1 for every subsequent send request. 

When the counter reaches the maximum value(0xFF), then it shall restart with 0 for the next s";
BA_ "Version" SG_ 2214592688 SLV_BLE_Decrypt_FB "23.01.02";
BA_ "UserSigValidity" SG_ 2214592688 SLV_BLE_Decrypt_FB 0;
BA_ "GenSigSendType" SG_ 2214592688 SLV_BLE_Decrypt_FB 4;
BA_ "Version" SG_ 2214592688 SLV_UWB_Decrypt_FB "23.01.02";
BA_ "UserSigValidity" SG_ 2214592688 SLV_UWB_Decrypt_FB 0;
BA_ "GenSigSendType" SG_ 2214592688 SLV_UWB_Decrypt_FB 4;
BA_ "Version" SG_ 2214592688 SLV_MST_Decrypt_FB "23.01.02";
BA_ "UserSigValidity" SG_ 2214592688 SLV_MST_Decrypt_FB 0;
BA_ "GenSigSendType" SG_ 2214592688 SLV_MST_Decrypt_FB 4;
BA_ "Version" SG_ 2214592688 SLV_OTA_Rsp "24.07.05";
BA_ "UserSigValidity" SG_ 2214592688 SLV_OTA_Rsp 0;
BA_ "GenSigSendType" SG_ 2214592688 SLV_OTA_Rsp 4;
BA_ "Description" SG_ 2214592688 SLV_OTA_Rsp "Slave OTA response";
BA_ "Version" SG_ 2214592688 SLV_UWB_IC_Status "24.04.03";
BA_ "UserSigValidity" SG_ 2214592688 SLV_UWB_IC_Status 0;
BA_ "GenSigSendType" SG_ 2214592688 SLV_UWB_IC_Status 4;
BA_ "Description" SG_ 2214592688 SLV_UWB_IC_Status "UWB IC Status Message";
BA_ "Version" SG_ 2214592689 L_UWB_BLE_SLV_FD_Crc2Val "23.01.02";
BA_ "UserSigValidity" SG_ 2214592689 L_UWB_BLE_SLV_FD_Crc2Val 3;
BA_ "GenSigStartValue" SG_ 2214592689 L_UWB_BLE_SLV_FD_Crc2Val 65535;
BA_ "GenSigSendType" SG_ 2214592689 L_UWB_BLE_SLV_FD_Crc2Val 4;
BA_ "Description" SG_ 2214592689 L_UWB_BLE_SLV_FD_Crc2Val "The data area for CRC calculation is based on the data length (DLC) of the message DB.

The CRC shall be calculated over the entire data block (excluding the CRC bytes) including the user data, alive counter and Data ID



- CRC Polynomial (0x1021) , Ini";
BA_ "Version" SG_ 2214592689 L_UWB_BLE_SLV_FD_AlvCnt2Val "23.01.02";
BA_ "UserSigValidity" SG_ 2214592689 L_UWB_BLE_SLV_FD_AlvCnt2Val 3;
BA_ "GenSigSendType" SG_ 2214592689 L_UWB_BLE_SLV_FD_AlvCnt2Val 4;
BA_ "Description" SG_ 2214592689 L_UWB_BLE_SLV_FD_AlvCnt2Val "For the first transmission request for a data element the counter shall be initialized with 0 and shall be incremented by 1 for every subsequent send request. 

When the counter reaches the maximum value(0xFF), then it shall restart with 0 for the next s";
BA_ "Version" SG_ 2214592689 SLV_UWB_FOB_RSD_Enc_Result "23.01.02";
BA_ "UserSigValidity" SG_ 2214592689 SLV_UWB_FOB_RSD_Enc_Result 0;
BA_ "GenSigSendType" SG_ 2214592689 SLV_UWB_FOB_RSD_Enc_Result 4;
BA_ "Version" SG_ 2214592687 MST_Dvp_Data "23.01.02";
BA_ "UserSigValidity" SG_ 2214592687 MST_Dvp_Data 0;
BA_ "GenSigSendType" SG_ 2214592687 MST_Dvp_Data 2;
BA_ "Version" SG_ 2214592686 L_UWB_BLE_MST_FD_Crc15Val "23.01.02";
BA_ "UserSigValidity" SG_ 2214592686 L_UWB_BLE_MST_FD_Crc15Val 3;
BA_ "GenSigStartValue" SG_ 2214592686 L_UWB_BLE_MST_FD_Crc15Val 65535;
BA_ "GenSigSendType" SG_ 2214592686 L_UWB_BLE_MST_FD_Crc15Val 4;
BA_ "Description" SG_ 2214592686 L_UWB_BLE_MST_FD_Crc15Val "The data area for CRC calculation is based on the data length (DLC) of the message DB.

The CRC shall be calculated over the entire data block (excluding the CRC bytes) including the user data, alive counter and Data ID



- CRC Polynomial (0x1021) , Ini";
BA_ "Version" SG_ 2214592686 L_UWB_BLE_MST_FD_AlvCnt15Val "23.01.02";
BA_ "UserSigValidity" SG_ 2214592686 L_UWB_BLE_MST_FD_AlvCnt15Val 3;
BA_ "GenSigSendType" SG_ 2214592686 L_UWB_BLE_MST_FD_AlvCnt15Val 4;
BA_ "Description" SG_ 2214592686 L_UWB_BLE_MST_FD_AlvCnt15Val "For the first transmission request for a data element the counter shall be initialized with 0 and shall be incremented by 1 for every subsequent send request. 

When the counter reaches the maximum value(0xFF), then it shall restart with 0 for the next s";
BA_ "Version" SG_ 2214592686 MST_Download_Data "23.01.02";
BA_ "UserSigValidity" SG_ 2214592686 MST_Download_Data 0;
BA_ "GenSigSendType" SG_ 2214592686 MST_Download_Data 4;
BA_ "Version" SG_ 2214592685 L_UWB_BLE_MST_FD_Crc14Val "23.01.02";
BA_ "UserSigValidity" SG_ 2214592685 L_UWB_BLE_MST_FD_Crc14Val 3;
BA_ "GenSigStartValue" SG_ 2214592685 L_UWB_BLE_MST_FD_Crc14Val 65535;
BA_ "GenSigSendType" SG_ 2214592685 L_UWB_BLE_MST_FD_Crc14Val 4;
BA_ "Description" SG_ 2214592685 L_UWB_BLE_MST_FD_Crc14Val "The data area for CRC calculation is based on the data length (DLC) of the message DB.

The CRC shall be calculated over the entire data block (excluding the CRC bytes) including the user data, alive counter and Data ID



- CRC Polynomial (0x1021) , Ini";
BA_ "Version" SG_ 2214592685 L_UWB_BLE_MST_FD_AlvCnt14Val "23.01.02";
BA_ "UserSigValidity" SG_ 2214592685 L_UWB_BLE_MST_FD_AlvCnt14Val 3;
BA_ "GenSigSendType" SG_ 2214592685 L_UWB_BLE_MST_FD_AlvCnt14Val 4;
BA_ "Description" SG_ 2214592685 L_UWB_BLE_MST_FD_AlvCnt14Val "For the first transmission request for a data element the counter shall be initialized with 0 and shall be incremented by 1 for every subsequent send request. 

When the counter reaches the maximum value(0xFF), then it shall restart with 0 for the next s";
BA_ "Version" SG_ 2214592685 MST_OTA_Cmd "24.07.05";
BA_ "UserSigValidity" SG_ 2214592685 MST_OTA_Cmd 0;
BA_ "GenSigSendType" SG_ 2214592685 MST_OTA_Cmd 4;
BA_ "Description" SG_ 2214592685 MST_OTA_Cmd "OTA Command for UWB_BLE Local";
BA_ "Version" SG_ 2214592684 L_UWB_BLE_MST_FD_Crc13Val "23.02.11";
BA_ "UserSigValidity" SG_ 2214592684 L_UWB_BLE_MST_FD_Crc13Val 3;
BA_ "GenSigStartValue" SG_ 2214592684 L_UWB_BLE_MST_FD_Crc13Val 65535;
BA_ "GenSigSendType" SG_ 2214592684 L_UWB_BLE_MST_FD_Crc13Val 4;
BA_ "Description" SG_ 2214592684 L_UWB_BLE_MST_FD_Crc13Val "The data area for CRC calculation is based on the data length (DLC) of the message DB.

The CRC shall be calculated over the entire data block (excluding the CRC bytes) including the user data, alive counter and Data ID



- CRC Polynomial (0x1021) , Ini";
BA_ "Version" SG_ 2214592684 L_UWB_BLE_MST_FD_AlvCnt13Val "23.02.11";
BA_ "UserSigValidity" SG_ 2214592684 L_UWB_BLE_MST_FD_AlvCnt13Val 3;
BA_ "GenSigSendType" SG_ 2214592684 L_UWB_BLE_MST_FD_AlvCnt13Val 4;
BA_ "Description" SG_ 2214592684 L_UWB_BLE_MST_FD_AlvCnt13Val "For the first transmission request for a data element the counter shall be initialized with 0 and shall be incremented by 1 for every subsequent send request. 

When the counter reaches the maximum value(0xFF), then it shall restart with 0 for the next s";
BA_ "Version" SG_ 2214592684 MST_To_BDC_Loc_Enc_Data2 "23.02.11";
BA_ "UserSigValidity" SG_ 2214592684 MST_To_BDC_Loc_Enc_Data2 0;
BA_ "GenSigSendType" SG_ 2214592684 MST_To_BDC_Loc_Enc_Data2 4;
BA_ "Version" SG_ 2214592683 L_UWB_BLE_MST_FD_Crc12Val "23.02.11";
BA_ "UserSigValidity" SG_ 2214592683 L_UWB_BLE_MST_FD_Crc12Val 3;
BA_ "GenSigStartValue" SG_ 2214592683 L_UWB_BLE_MST_FD_Crc12Val 65535;
BA_ "GenSigSendType" SG_ 2214592683 L_UWB_BLE_MST_FD_Crc12Val 4;
BA_ "Description" SG_ 2214592683 L_UWB_BLE_MST_FD_Crc12Val "The data area for CRC calculation is based on the data length (DLC) of the message DB.

The CRC shall be calculated over the entire data block (excluding the CRC bytes) including the user data, alive counter and Data ID



- CRC Polynomial (0x1021) , Ini";
BA_ "Version" SG_ 2214592683 L_UWB_BLE_MST_FD_AlvCnt12Val "23.02.11";
BA_ "UserSigValidity" SG_ 2214592683 L_UWB_BLE_MST_FD_AlvCnt12Val 3;
BA_ "GenSigSendType" SG_ 2214592683 L_UWB_BLE_MST_FD_AlvCnt12Val 4;
BA_ "Description" SG_ 2214592683 L_UWB_BLE_MST_FD_AlvCnt12Val "For the first transmission request for a data element the counter shall be initialized with 0 and shall be incremented by 1 for every subsequent send request. 

When the counter reaches the maximum value(0xFF), then it shall restart with 0 for the next s";
BA_ "Version" SG_ 2214592683 MST_To_BDC_Loc_Enc_Data1 "23.02.11";
BA_ "UserSigValidity" SG_ 2214592683 MST_To_BDC_Loc_Enc_Data1 0;
BA_ "GenSigSendType" SG_ 2214592683 MST_To_BDC_Loc_Enc_Data1 4;
BA_ "Version" SG_ 2214592682 L_UWB_BLE_MST_FD_Crc11Val "23.01.02";
BA_ "UserSigValidity" SG_ 2214592682 L_UWB_BLE_MST_FD_Crc11Val 3;
BA_ "GenSigStartValue" SG_ 2214592682 L_UWB_BLE_MST_FD_Crc11Val 65535;
BA_ "GenSigSendType" SG_ 2214592682 L_UWB_BLE_MST_FD_Crc11Val 4;
BA_ "Description" SG_ 2214592682 L_UWB_BLE_MST_FD_Crc11Val "The data area for CRC calculation is based on the data length (DLC) of the message DB.

The CRC shall be calculated over the entire data block (excluding the CRC bytes) including the user data, alive counter and Data ID



- CRC Polynomial (0x1021) , Ini";
BA_ "Version" SG_ 2214592682 L_UWB_BLE_MST_FD_AlvCnt11Val "23.01.02";
BA_ "UserSigValidity" SG_ 2214592682 L_UWB_BLE_MST_FD_AlvCnt11Val 3;
BA_ "GenSigSendType" SG_ 2214592682 L_UWB_BLE_MST_FD_AlvCnt11Val 4;
BA_ "Description" SG_ 2214592682 L_UWB_BLE_MST_FD_AlvCnt11Val "For the first transmission request for a data element the counter shall be initialized with 0 and shall be incremented by 1 for every subsequent send request. 

When the counter reaches the maximum value(0xFF), then it shall restart with 0 for the next s";
BA_ "Version" SG_ 2214592682 MST_BLE_To_BDC_Enc_Data2 "23.01.02";
BA_ "UserSigValidity" SG_ 2214592682 MST_BLE_To_BDC_Enc_Data2 0;
BA_ "GenSigSendType" SG_ 2214592682 MST_BLE_To_BDC_Enc_Data2 4;
BA_ "Version" SG_ 2214592681 L_UWB_BLE_MST_FD_Crc10Val "23.01.02";
BA_ "UserSigValidity" SG_ 2214592681 L_UWB_BLE_MST_FD_Crc10Val 3;
BA_ "GenSigStartValue" SG_ 2214592681 L_UWB_BLE_MST_FD_Crc10Val 65535;
BA_ "GenSigSendType" SG_ 2214592681 L_UWB_BLE_MST_FD_Crc10Val 4;
BA_ "Description" SG_ 2214592681 L_UWB_BLE_MST_FD_Crc10Val "The data area for CRC calculation is based on the data length (DLC) of the message DB.

The CRC shall be calculated over the entire data block (excluding the CRC bytes) including the user data, alive counter and Data ID



- CRC Polynomial (0x1021) , Ini";
BA_ "Version" SG_ 2214592681 L_UWB_BLE_MST_FD_AlvCnt10Val "23.01.02";
BA_ "UserSigValidity" SG_ 2214592681 L_UWB_BLE_MST_FD_AlvCnt10Val 3;
BA_ "GenSigSendType" SG_ 2214592681 L_UWB_BLE_MST_FD_AlvCnt10Val 4;
BA_ "Description" SG_ 2214592681 L_UWB_BLE_MST_FD_AlvCnt10Val "For the first transmission request for a data element the counter shall be initialized with 0 and shall be incremented by 1 for every subsequent send request. 

When the counter reaches the maximum value(0xFF), then it shall restart with 0 for the next s";
BA_ "Version" SG_ 2214592681 MST_BLE_To_BDC_Enc_Data1 "23.01.02";
BA_ "UserSigValidity" SG_ 2214592681 MST_BLE_To_BDC_Enc_Data1 0;
BA_ "GenSigSendType" SG_ 2214592681 MST_BLE_To_BDC_Enc_Data1 4;
BA_ "Version" SG_ 2214592680 L_UWB_BLE_MST_FD_Crc9Val "23.01.02";
BA_ "UserSigValidity" SG_ 2214592680 L_UWB_BLE_MST_FD_Crc9Val 3;
BA_ "GenSigStartValue" SG_ 2214592680 L_UWB_BLE_MST_FD_Crc9Val 65535;
BA_ "GenSigSendType" SG_ 2214592680 L_UWB_BLE_MST_FD_Crc9Val 4;
BA_ "Description" SG_ 2214592680 L_UWB_BLE_MST_FD_Crc9Val "The data area for CRC calculation is based on the data length (DLC) of the message DB.

The CRC shall be calculated over the entire data block (excluding the CRC bytes) including the user data, alive counter and Data ID



- CRC Polynomial (0x1021) , Ini";
BA_ "Version" SG_ 2214592680 L_UWB_BLE_MST_FD_AlvCnt9Val "23.01.02";
BA_ "UserSigValidity" SG_ 2214592680 L_UWB_BLE_MST_FD_AlvCnt9Val 3;
BA_ "GenSigSendType" SG_ 2214592680 L_UWB_BLE_MST_FD_AlvCnt9Val 4;
BA_ "Description" SG_ 2214592680 L_UWB_BLE_MST_FD_AlvCnt9Val "For the first transmission request for a data element the counter shall be initialized with 0 and shall be incremented by 1 for every subsequent send request. 

When the counter reaches the maximum value(0xFF), then it shall restart with 0 for the next s";
BA_ "Version" SG_ 2214592680 MST_To_UWB_Enc_Data5 "23.01.02";
BA_ "UserSigValidity" SG_ 2214592680 MST_To_UWB_Enc_Data5 0;
BA_ "GenSigSendType" SG_ 2214592680 MST_To_UWB_Enc_Data5 4;
BA_ "Version" SG_ 2214592679 L_UWB_BLE_MST_FD_Crc8Val "23.01.02";
BA_ "UserSigValidity" SG_ 2214592679 L_UWB_BLE_MST_FD_Crc8Val 3;
BA_ "GenSigStartValue" SG_ 2214592679 L_UWB_BLE_MST_FD_Crc8Val 65535;
BA_ "GenSigSendType" SG_ 2214592679 L_UWB_BLE_MST_FD_Crc8Val 4;
BA_ "Description" SG_ 2214592679 L_UWB_BLE_MST_FD_Crc8Val "The data area for CRC calculation is based on the data length (DLC) of the message DB.

The CRC shall be calculated over the entire data block (excluding the CRC bytes) including the user data, alive counter and Data ID



- CRC Polynomial (0x1021) , Ini";
BA_ "Version" SG_ 2214592679 L_UWB_BLE_MST_FD_AlvCnt8Val "23.01.02";
BA_ "UserSigValidity" SG_ 2214592679 L_UWB_BLE_MST_FD_AlvCnt8Val 3;
BA_ "GenSigSendType" SG_ 2214592679 L_UWB_BLE_MST_FD_AlvCnt8Val 4;
BA_ "Description" SG_ 2214592679 L_UWB_BLE_MST_FD_AlvCnt8Val "For the first transmission request for a data element the counter shall be initialized with 0 and shall be incremented by 1 for every subsequent send request. 

When the counter reaches the maximum value(0xFF), then it shall restart with 0 for the next s";
BA_ "Version" SG_ 2214592679 MST_To_UWB_Enc_Data4 "23.01.02";
BA_ "UserSigValidity" SG_ 2214592679 MST_To_UWB_Enc_Data4 0;
BA_ "GenSigSendType" SG_ 2214592679 MST_To_UWB_Enc_Data4 4;
BA_ "Version" SG_ 2214592678 L_UWB_BLE_MST_FD_Crc7Val "23.01.02";
BA_ "UserSigValidity" SG_ 2214592678 L_UWB_BLE_MST_FD_Crc7Val 3;
BA_ "GenSigStartValue" SG_ 2214592678 L_UWB_BLE_MST_FD_Crc7Val 65535;
BA_ "GenSigSendType" SG_ 2214592678 L_UWB_BLE_MST_FD_Crc7Val 4;
BA_ "Description" SG_ 2214592678 L_UWB_BLE_MST_FD_Crc7Val "The data area for CRC calculation is based on the data length (DLC) of the message DB.

The CRC shall be calculated over the entire data block (excluding the CRC bytes) including the user data, alive counter and Data ID



- CRC Polynomial (0x1021) , Ini";
BA_ "Version" SG_ 2214592678 L_UWB_BLE_MST_FD_AlvCnt7Val "23.01.02";
BA_ "UserSigValidity" SG_ 2214592678 L_UWB_BLE_MST_FD_AlvCnt7Val 3;
BA_ "GenSigSendType" SG_ 2214592678 L_UWB_BLE_MST_FD_AlvCnt7Val 4;
BA_ "Description" SG_ 2214592678 L_UWB_BLE_MST_FD_AlvCnt7Val "For the first transmission request for a data element the counter shall be initialized with 0 and shall be incremented by 1 for every subsequent send request. 

When the counter reaches the maximum value(0xFF), then it shall restart with 0 for the next s";
BA_ "Version" SG_ 2214592678 MST_To_UWB_Enc_Data3 "23.01.02";
BA_ "UserSigValidity" SG_ 2214592678 MST_To_UWB_Enc_Data3 0;
BA_ "GenSigSendType" SG_ 2214592678 MST_To_UWB_Enc_Data3 4;
BA_ "Version" SG_ 2529538817 L_UWB_RL_FD_Crc7Val "24.07.05";
BA_ "RoutingFactor" SG_ 2529538817 L_UWB_RL_FD_Crc7Val 0;
BA_ "UserSigValidity" SG_ 2529538817 L_UWB_RL_FD_Crc7Val 3;
BA_ "GenSigStartValue" SG_ 2529538817 L_UWB_RL_FD_Crc7Val 65535;
BA_ "GenSigSendType" SG_ 2529538817 L_UWB_RL_FD_Crc7Val 2;
BA_ "Description" SG_ 2529538817 L_UWB_RL_FD_Crc7Val "The data area for CRC calculation is based on the data length (DLC) of the message DB.

The CRC shall be calculated over the entire data block (excluding the CRC bytes) including the user data, alive counter and Data ID



- CRC Polynomial (0x1021) , Ini";
BA_ "Version" SG_ 2529538817 L_UWB_RL_FD_AlvCnt7Val "24.07.05";
BA_ "RoutingFactor" SG_ 2529538817 L_UWB_RL_FD_AlvCnt7Val 0;
BA_ "UserSigValidity" SG_ 2529538817 L_UWB_RL_FD_AlvCnt7Val 3;
BA_ "GenSigSendType" SG_ 2529538817 L_UWB_RL_FD_AlvCnt7Val 2;
BA_ "Description" SG_ 2529538817 L_UWB_RL_FD_AlvCnt7Val "For the first transmission request for a data element the counter shall be initialized with 0 and shall be incremented by 1 for every subsequent send request. 

When the counter reaches the maximum value(0xFF), then it shall restart with 0 for the next s";
BA_ "Version" SG_ 2529538817 RL_SWID_4_IVD_2 "24.07.05";
BA_ "RoutingFactor" SG_ 2529538817 RL_SWID_4_IVD_2 0;
BA_ "UserSigValidity" SG_ 2529538817 RL_SWID_4_IVD_2 0;
BA_ "GenSigSendType" SG_ 2529538817 RL_SWID_4_IVD_2 2;
BA_ "Version" SG_ 2214592677 L_UWB_BLE_MST_FD_Crc6Val "23.01.02";
BA_ "UserSigValidity" SG_ 2214592677 L_UWB_BLE_MST_FD_Crc6Val 3;
BA_ "GenSigStartValue" SG_ 2214592677 L_UWB_BLE_MST_FD_Crc6Val 65535;
BA_ "GenSigSendType" SG_ 2214592677 L_UWB_BLE_MST_FD_Crc6Val 4;
BA_ "Description" SG_ 2214592677 L_UWB_BLE_MST_FD_Crc6Val "The data area for CRC calculation is based on the data length (DLC) of the message DB.

The CRC shall be calculated over the entire data block (excluding the CRC bytes) including the user data, alive counter and Data ID



- CRC Polynomial (0x1021) , Ini";
BA_ "Version" SG_ 2214592677 L_UWB_BLE_MST_FD_AlvCnt6Val "23.01.02";
BA_ "UserSigValidity" SG_ 2214592677 L_UWB_BLE_MST_FD_AlvCnt6Val 3;
BA_ "GenSigSendType" SG_ 2214592677 L_UWB_BLE_MST_FD_AlvCnt6Val 4;
BA_ "Description" SG_ 2214592677 L_UWB_BLE_MST_FD_AlvCnt6Val "For the first transmission request for a data element the counter shall be initialized with 0 and shall be incremented by 1 for every subsequent send request. 

When the counter reaches the maximum value(0xFF), then it shall restart with 0 for the next s";
BA_ "Version" SG_ 2214592677 MST_To_UWB_Enc_Data2 "23.01.02";
BA_ "UserSigValidity" SG_ 2214592677 MST_To_UWB_Enc_Data2 0;
BA_ "GenSigSendType" SG_ 2214592677 MST_To_UWB_Enc_Data2 4;
BA_ "Version" SG_ 2214592676 L_UWB_BLE_MST_FD_Crc5Val "23.01.02";
BA_ "UserSigValidity" SG_ 2214592676 L_UWB_BLE_MST_FD_Crc5Val 3;
BA_ "GenSigStartValue" SG_ 2214592676 L_UWB_BLE_MST_FD_Crc5Val 65535;
BA_ "GenSigSendType" SG_ 2214592676 L_UWB_BLE_MST_FD_Crc5Val 4;
BA_ "Description" SG_ 2214592676 L_UWB_BLE_MST_FD_Crc5Val "The data area for CRC calculation is based on the data length (DLC) of the message DB.

The CRC shall be calculated over the entire data block (excluding the CRC bytes) including the user data, alive counter and Data ID



- CRC Polynomial (0x1021) , Ini";
BA_ "Version" SG_ 2214592676 L_UWB_BLE_MST_FD_AlvCnt5Val "23.01.02";
BA_ "UserSigValidity" SG_ 2214592676 L_UWB_BLE_MST_FD_AlvCnt5Val 3;
BA_ "GenSigSendType" SG_ 2214592676 L_UWB_BLE_MST_FD_AlvCnt5Val 4;
BA_ "Description" SG_ 2214592676 L_UWB_BLE_MST_FD_AlvCnt5Val "For the first transmission request for a data element the counter shall be initialized with 0 and shall be incremented by 1 for every subsequent send request. 

When the counter reaches the maximum value(0xFF), then it shall restart with 0 for the next s";
BA_ "Version" SG_ 2214592676 MST_To_UWB_Enc_Data1 "23.01.02";
BA_ "UserSigValidity" SG_ 2214592676 MST_To_UWB_Enc_Data1 0;
BA_ "GenSigSendType" SG_ 2214592676 MST_To_UWB_Enc_Data1 4;
BA_ "Version" SG_ 2533737217 L_UWB_TRNK_FD_Crc7Val "24.07.05";
BA_ "RoutingFactor" SG_ 2533737217 L_UWB_TRNK_FD_Crc7Val 0;
BA_ "UserSigValidity" SG_ 2533737217 L_UWB_TRNK_FD_Crc7Val 3;
BA_ "GenSigStartValue" SG_ 2533737217 L_UWB_TRNK_FD_Crc7Val 65535;
BA_ "GenSigSendType" SG_ 2533737217 L_UWB_TRNK_FD_Crc7Val 2;
BA_ "Description" SG_ 2533737217 L_UWB_TRNK_FD_Crc7Val "The data area for CRC calculation is based on the data length (DLC) of the message DB.

The CRC shall be calculated over the entire data block (excluding the CRC bytes) including the user data, alive counter and Data ID



- CRC Polynomial (0x1021) , Ini";
BA_ "Version" SG_ 2533737217 L_UWB_TRNK_FD_AlvCnt7Val "24.07.05";
BA_ "RoutingFactor" SG_ 2533737217 L_UWB_TRNK_FD_AlvCnt7Val 0;
BA_ "UserSigValidity" SG_ 2533737217 L_UWB_TRNK_FD_AlvCnt7Val 3;
BA_ "GenSigSendType" SG_ 2533737217 L_UWB_TRNK_FD_AlvCnt7Val 2;
BA_ "Description" SG_ 2533737217 L_UWB_TRNK_FD_AlvCnt7Val "For the first transmission request for a data element the counter shall be initialized with 0 and shall be incremented by 1 for every subsequent send request. 

When the counter reaches the maximum value(0xFF), then it shall restart with 0 for the next s";
BA_ "Version" SG_ 2533737217 TRNK_SWID_4_IVD_2 "24.07.05";
BA_ "RoutingFactor" SG_ 2533737217 TRNK_SWID_4_IVD_2 0;
BA_ "UserSigValidity" SG_ 2533737217 TRNK_SWID_4_IVD_2 0;
BA_ "GenSigSendType" SG_ 2533737217 TRNK_SWID_4_IVD_2 2;
BA_ "Version" SG_ 2214592675 L_UWB_BLE_MST_FD_Crc4Val "23.01.02";
BA_ "UserSigValidity" SG_ 2214592675 L_UWB_BLE_MST_FD_Crc4Val 3;
BA_ "GenSigStartValue" SG_ 2214592675 L_UWB_BLE_MST_FD_Crc4Val 65535;
BA_ "GenSigSendType" SG_ 2214592675 L_UWB_BLE_MST_FD_Crc4Val 4;
BA_ "Description" SG_ 2214592675 L_UWB_BLE_MST_FD_Crc4Val "The data area for CRC calculation is based on the data length (DLC) of the message DB.

The CRC shall be calculated over the entire data block (excluding the CRC bytes) including the user data, alive counter and Data ID



- CRC Polynomial (0x1021) , Ini";
BA_ "Version" SG_ 2214592675 L_UWB_BLE_MST_FD_AlvCnt4Val "23.01.02";
BA_ "UserSigValidity" SG_ 2214592675 L_UWB_BLE_MST_FD_AlvCnt4Val 3;
BA_ "GenSigSendType" SG_ 2214592675 L_UWB_BLE_MST_FD_AlvCnt4Val 4;
BA_ "Description" SG_ 2214592675 L_UWB_BLE_MST_FD_AlvCnt4Val "For the first transmission request for a data element the counter shall be initialized with 0 and shall be incremented by 1 for every subsequent send request. 

When the counter reaches the maximum value(0xFF), then it shall restart with 0 for the next s";
BA_ "Version" SG_ 2214592675 MST_RndNum_Trgt "23.04.00";
BA_ "UserSigValidity" SG_ 2214592675 MST_RndNum_Trgt 0;
BA_ "GenSigSendType" SG_ 2214592675 MST_RndNum_Trgt 4;
BA_ "Version" SG_ 2214592675 MST_RndNum_TRCode "23.01.02";
BA_ "UserSigValidity" SG_ 2214592675 MST_RndNum_TRCode 0;
BA_ "GenSigSendType" SG_ 2214592675 MST_RndNum_TRCode 4;
BA_ "Version" SG_ 2214592675 MST_RndNum_Cmd "23.01.02";
BA_ "UserSigValidity" SG_ 2214592675 MST_RndNum_Cmd 0;
BA_ "GenSigSendType" SG_ 2214592675 MST_RndNum_Cmd 4;
BA_ "Version" SG_ 2214592675 MST_RndNum "23.01.02";
BA_ "UserSigValidity" SG_ 2214592675 MST_RndNum 0;
BA_ "GenSigSendType" SG_ 2214592675 MST_RndNum 4;
BA_ "Version" SG_ 2214592674 L_UWB_BLE_MST_FD_Crc3Val "23.01.02";
BA_ "UserSigValidity" SG_ 2214592674 L_UWB_BLE_MST_FD_Crc3Val 3;
BA_ "GenSigStartValue" SG_ 2214592674 L_UWB_BLE_MST_FD_Crc3Val 65535;
BA_ "GenSigSendType" SG_ 2214592674 L_UWB_BLE_MST_FD_Crc3Val 2;
BA_ "Description" SG_ 2214592674 L_UWB_BLE_MST_FD_Crc3Val "The data area for CRC calculation is based on the data length (DLC) of the message DB.

The CRC shall be calculated over the entire data block (excluding the CRC bytes) including the user data, alive counter and Data ID



- CRC Polynomial (0x1021) , Ini";
BA_ "Version" SG_ 2214592674 L_UWB_BLE_MST_FD_AlvCnt3Val "23.01.02";
BA_ "UserSigValidity" SG_ 2214592674 L_UWB_BLE_MST_FD_AlvCnt3Val 3;
BA_ "GenSigSendType" SG_ 2214592674 L_UWB_BLE_MST_FD_AlvCnt3Val 2;
BA_ "Description" SG_ 2214592674 L_UWB_BLE_MST_FD_AlvCnt3Val "For the first transmission request for a data element the counter shall be initialized with 0 and shall be incremented by 1 for every subsequent send request. 

When the counter reaches the maximum value(0xFF), then it shall restart with 0 for the next s";
BA_ "Version" SG_ 2214592674 MST_UWB_Ranging_Enc_Result2 "24.04.06";
BA_ "UserSigValidity" SG_ 2214592674 MST_UWB_Ranging_Enc_Result2 0;
BA_ "GenSigSendType" SG_ 2214592674 MST_UWB_Ranging_Enc_Result2 2;
BA_ "Description" SG_ 2214592674 MST_UWB_Ranging_Enc_Result2 "UWB Ranging Result2(Encrypted Data) with DK";
BA_ "Version" SG_ 2214592674 MST_UWB_Ranging_Enc_Result "23.01.02";
BA_ "UserSigValidity" SG_ 2214592674 MST_UWB_Ranging_Enc_Result 0;
BA_ "GenSigSendType" SG_ 2214592674 MST_UWB_Ranging_Enc_Result 2;
BA_ "Version" SG_ 2214592673 L_UWB_BLE_MST_FD_Crc2Val "23.01.02";
BA_ "UserSigValidity" SG_ 2214592673 L_UWB_BLE_MST_FD_Crc2Val 3;
BA_ "GenSigStartValue" SG_ 2214592673 L_UWB_BLE_MST_FD_Crc2Val 65535;
BA_ "GenSigSendType" SG_ 2214592673 L_UWB_BLE_MST_FD_Crc2Val 4;
BA_ "Description" SG_ 2214592673 L_UWB_BLE_MST_FD_Crc2Val "The data area for CRC calculation is based on the data length (DLC) of the message DB.

The CRC shall be calculated over the entire data block (excluding the CRC bytes) including the user data, alive counter and Data ID



- CRC Polynomial (0x1021) , Ini";
BA_ "Version" SG_ 2214592673 L_UWB_BLE_MST_FD_AlvCnt2Val "23.01.02";
BA_ "UserSigValidity" SG_ 2214592673 L_UWB_BLE_MST_FD_AlvCnt2Val 3;
BA_ "GenSigSendType" SG_ 2214592673 L_UWB_BLE_MST_FD_AlvCnt2Val 4;
BA_ "Description" SG_ 2214592673 L_UWB_BLE_MST_FD_AlvCnt2Val "For the first transmission request for a data element the counter shall be initialized with 0 and shall be incremented by 1 for every subsequent send request. 

When the counter reaches the maximum value(0xFF), then it shall restart with 0 for the next s";
BA_ "Version" SG_ 2214592673 MST_UWB_FOB_RSD_Enc_Result "23.01.02";
BA_ "UserSigValidity" SG_ 2214592673 MST_UWB_FOB_RSD_Enc_Result 0;
BA_ "GenSigSendType" SG_ 2214592673 MST_UWB_FOB_RSD_Enc_Result 4;
BA_ "Version" SG_ 2214592672 L_UWB_BLE_MST_FD_Crc1Val "23.01.02";
BA_ "UserSigValidity" SG_ 2214592672 L_UWB_BLE_MST_FD_Crc1Val 3;
BA_ "GenSigStartValue" SG_ 2214592672 L_UWB_BLE_MST_FD_Crc1Val 65535;
BA_ "GenSigSendType" SG_ 2214592672 L_UWB_BLE_MST_FD_Crc1Val 4;
BA_ "Description" SG_ 2214592672 L_UWB_BLE_MST_FD_Crc1Val "The data area for CRC calculation is based on the data length (DLC) of the message DB.

The CRC shall be calculated over the entire data block (excluding the CRC bytes) including the user data, alive counter and Data ID



- CRC Polynomial (0x1021) , Ini";
BA_ "Version" SG_ 2214592672 L_UWB_BLE_MST_FD_AlvCnt1Val "23.01.02";
BA_ "UserSigValidity" SG_ 2214592672 L_UWB_BLE_MST_FD_AlvCnt1Val 3;
BA_ "GenSigSendType" SG_ 2214592672 L_UWB_BLE_MST_FD_AlvCnt1Val 4;
BA_ "Description" SG_ 2214592672 L_UWB_BLE_MST_FD_AlvCnt1Val "For the first transmission request for a data element the counter shall be initialized with 0 and shall be incremented by 1 for every subsequent send request. 

When the counter reaches the maximum value(0xFF), then it shall restart with 0 for the next s";
BA_ "Version" SG_ 2214592672 MST_BLE_Decrypt_FB "23.01.02";
BA_ "UserSigValidity" SG_ 2214592672 MST_BLE_Decrypt_FB 0;
BA_ "GenSigSendType" SG_ 2214592672 MST_BLE_Decrypt_FB 4;
BA_ "Version" SG_ 2214592672 MST_UWB_Decrypt_FB "23.01.02";
BA_ "UserSigValidity" SG_ 2214592672 MST_UWB_Decrypt_FB 0;
BA_ "GenSigSendType" SG_ 2214592672 MST_UWB_Decrypt_FB 4;
BA_ "Version" SG_ 2214592672 MST_SLV_Decrypt_FB "23.01.02";
BA_ "UserSigValidity" SG_ 2214592672 MST_SLV_Decrypt_FB 0;
BA_ "GenSigSendType" SG_ 2214592672 MST_SLV_Decrypt_FB 4;
BA_ "Version" SG_ 2214592672 MST_OTA_Status "23.01.02";
BA_ "UserSigValidity" SG_ 2214592672 MST_OTA_Status 0;
BA_ "GenSigSendType" SG_ 2214592672 MST_OTA_Status 4;
BA_ "Version" SG_ 2214592672 MST_UWB_IC_Status "24.04.03";
BA_ "UserSigValidity" SG_ 2214592672 MST_UWB_IC_Status 0;
BA_ "GenSigSendType" SG_ 2214592672 MST_UWB_IC_Status 4;
BA_ "Description" SG_ 2214592672 MST_UWB_IC_Status "UWB IC Status Message";
BA_ "Version" SG_ 2525342465 L_UWB_FR_FD_Crc7Val "24.07.05";
BA_ "RoutingFactor" SG_ 2525342465 L_UWB_FR_FD_Crc7Val 0;
BA_ "UserSigValidity" SG_ 2525342465 L_UWB_FR_FD_Crc7Val 3;
BA_ "GenSigStartValue" SG_ 2525342465 L_UWB_FR_FD_Crc7Val 65535;
BA_ "GenSigSendType" SG_ 2525342465 L_UWB_FR_FD_Crc7Val 2;
BA_ "Description" SG_ 2525342465 L_UWB_FR_FD_Crc7Val "The data area for CRC calculation is based on the data length (DLC) of the message DB.

The CRC shall be calculated over the entire data block (excluding the CRC bytes) including the user data, alive counter and Data ID



- CRC Polynomial (0x1021) , Ini";
BA_ "Version" SG_ 2525342465 L_UWB_FR_FD_AlvCnt7Val "24.07.05";
BA_ "RoutingFactor" SG_ 2525342465 L_UWB_FR_FD_AlvCnt7Val 0;
BA_ "UserSigValidity" SG_ 2525342465 L_UWB_FR_FD_AlvCnt7Val 3;
BA_ "GenSigSendType" SG_ 2525342465 L_UWB_FR_FD_AlvCnt7Val 2;
BA_ "Description" SG_ 2525342465 L_UWB_FR_FD_AlvCnt7Val "For the first transmission request for a data element the counter shall be initialized with 0 and shall be incremented by 1 for every subsequent send request. 

When the counter reaches the maximum value(0xFF), then it shall restart with 0 for the next s";
BA_ "Version" SG_ 2525342465 FR_SWID_4_IVD_2 "24.07.05";
BA_ "RoutingFactor" SG_ 2525342465 FR_SWID_4_IVD_2 0;
BA_ "UserSigValidity" SG_ 2525342465 FR_SWID_4_IVD_2 0;
BA_ "GenSigSendType" SG_ 2525342465 FR_SWID_4_IVD_2 2;
BA_ "Version" SG_ 829 SBCM_RR_FD_Crc1Val "22.10.20";
BA_ "UserSigValidity" SG_ 829 SBCM_RR_FD_Crc1Val 3;
BA_ "GenSigStartValue" SG_ 829 SBCM_RR_FD_Crc1Val 65535;
BA_ "GenSigSendType" SG_ 829 SBCM_RR_FD_Crc1Val 4;
BA_ "Description" SG_ 829 SBCM_RR_FD_Crc1Val "The data area for CRC calculation is based on the data length (DLC) of the message DB.

The CRC shall be calculated over the entire data block (excluding the CRC bytes) including the user data, alive counter and Data ID



- CRC Polynomial (0x1021) , Ini";
BA_ "Version" SG_ 829 USM_RRGhostDoorSta_Copy_0 "21.07.07";
BA_ "NetworkRequestHoldingTime" SG_ 829 USM_RRGhostDoorSta_Copy_0 5000;
BA_ "NetworkRequest" SG_ 829 USM_RRGhostDoorSta_Copy_0 0;
BA_ "UserSigValidity" SG_ 829 USM_RRGhostDoorSta_Copy_0 0;
BA_ "GenSigSendType" SG_ 829 USM_RRGhostDoorSta_Copy_0 4;
BA_ "Version" SG_ 829 DoorLock_PDSLkSwSta_RR_Copy_0 "21.09.05";
BA_ "NetworkRequest" SG_ 829 DoorLock_PDSLkSwSta_RR_Copy_0 0;
BA_ "UserSigValidity" SG_ 829 DoorLock_PDSLkSwSta_RR_Copy_0 0;
BA_ "GenSigSendType" SG_ 829 DoorLock_PDSLkSwSta_RR_Copy_0 4;
BA_ "Version" SG_ 829 PDS_TypeOption_RR_Copy_0 "21.07.07";
BA_ "NetworkRequest" SG_ 829 PDS_TypeOption_RR_Copy_0 0;
BA_ "UserSigValidity" SG_ 829 PDS_TypeOption_RR_Copy_0 0;
BA_ "GenSigSendType" SG_ 829 PDS_TypeOption_RR_Copy_0 4;
BA_ "Version" SG_ 829 RR_CrashMRActAlarm_Copy_0 "21.07.07";
BA_ "NetworkRequestHoldingTime" SG_ 829 RR_CrashMRActAlarm_Copy_0 5000;
BA_ "NetworkRequest" SG_ 829 RR_CrashMRActAlarm_Copy_0 0;
BA_ "UserSigValidity" SG_ 829 RR_CrashMRActAlarm_Copy_0 0;
BA_ "GenSigSendType" SG_ 829 RR_CrashMRActAlarm_Copy_0 4;
BA_ "Version" SG_ 829 PwrDRBuzzerOut_RR_Copy_0 "21.07.07";
BA_ "NetworkRequestHoldingTime" SG_ 829 PwrDRBuzzerOut_RR_Copy_0 5000;
BA_ "NetworkRequest" SG_ 829 PwrDRBuzzerOut_RR_Copy_0 0;
BA_ "UserSigValidity" SG_ 829 PwrDRBuzzerOut_RR_Copy_0 0;
BA_ "GenSigSendType" SG_ 829 PwrDRBuzzerOut_RR_Copy_0 4;
BA_ "Version" SG_ 829 PwrDRClosingRRDrSta_Copy_0 "23.07.06";
BA_ "NetworkRequestHoldingTime" SG_ 829 PwrDRClosingRRDrSta_Copy_0 5000;
BA_ "NetworkRequest" SG_ 829 PwrDRClosingRRDrSta_Copy_0 0;
BA_ "UserSigValidity" SG_ 829 PwrDRClosingRRDrSta_Copy_0 0;
BA_ "GenSigSendType" SG_ 829 PwrDRClosingRRDrSta_Copy_0 4;
BA_ "Version" SG_ 829 AFH_RR_FldUnfldSta_Copy_0 "24.07.06";
BA_ "NetworkRequestHoldingTime" SG_ 829 AFH_RR_FldUnfldSta_Copy_0 5000;
BA_ "NetworkRequest" SG_ 829 AFH_RR_FldUnfldSta_Copy_0 0;
BA_ "UserSigValidity" SG_ 829 AFH_RR_FldUnfldSta_Copy_0 0;
BA_ "GenSigSendType" SG_ 829 AFH_RR_FldUnfldSta_Copy_0 4;
BA_ "Version" SG_ 829 SBCM_RR_FD_AlvCnt1Val "22.10.20";
BA_ "UserSigValidity" SG_ 829 SBCM_RR_FD_AlvCnt1Val 3;
BA_ "GenSigSendType" SG_ 829 SBCM_RR_FD_AlvCnt1Val 4;
BA_ "Description" SG_ 829 SBCM_RR_FD_AlvCnt1Val "For the first transmission request for a data element the counter shall be initialized with 0 and shall be incremented by 1 for every subsequent send request. 

When the counter reaches the maximum value(0xFF), then it shall restart with 0 for the next s";
BA_ "Version" SG_ 829 DoorLock_RrRtLkOutSta_SBCM_Copy_ "23.02.09";
BA_ "NetworkRequestHoldingTime" SG_ 829 DoorLock_RrRtLkOutSta_SBCM_Copy_ 5000;
BA_ "NetworkRequest" SG_ 829 DoorLock_RrRtLkOutSta_SBCM_Copy_ 0;
BA_ "UserSigValidity" SG_ 829 DoorLock_RrRtLkOutSta_SBCM_Copy_ 0;
BA_ "GenSigSendType" SG_ 829 DoorLock_RrRtLkOutSta_SBCM_Copy_ 4;
BA_ "Description" SG_ 829 DoorLock_RrRtLkOutSta_SBCM_Copy_ "- Door Lock or Unlock Output State 

0x0 : Off (Door lock/unlock output Off state)

0x1 : On (Door lock/unlock output On state)";
BA_ "SystemSignalLongSymbol" SG_ 829 DoorLock_RrRtLkOutSta_SBCM_Copy_ "DoorLock_RrRtLkOutSta_SBCM_Copy_0";
BA_ "Version" SG_ 829 RrRt_DrLkRetryFail_SBCM_Copy_0 "23.03.00";
BA_ "NetworkRequestHoldingTime" SG_ 829 RrRt_DrLkRetryFail_SBCM_Copy_0 5000;
BA_ "NetworkRequest" SG_ 829 RrRt_DrLkRetryFail_SBCM_Copy_0 0;
BA_ "UserSigValidity" SG_ 829 RrRt_DrLkRetryFail_SBCM_Copy_0 0;
BA_ "TimeoutValue" SG_ 829 RrRt_DrLkRetryFail_SBCM_Copy_0 "0x0";
BA_ "GenSigSendType" SG_ 829 RrRt_DrLkRetryFail_SBCM_Copy_0 4;
BA_ "Version" SG_ 829 RR_DetectObj_warn "23.10.11";
BA_ "NetworkRequestHoldingTime" SG_ 829 RR_DetectObj_warn 5000;
BA_ "NetworkRequest" SG_ 829 RR_DetectObj_warn 0;
BA_ "UserSigValidity" SG_ 829 RR_DetectObj_warn 0;
BA_ "GenSigSendType" SG_ 829 RR_DetectObj_warn 4;
BA_ "Version" SG_ 829 RRRrDrCurtainPosition "23.08.00";
BA_ "NetworkRequestHoldingTime" SG_ 829 RRRrDrCurtainPosition 5000;
BA_ "NetworkRequest" SG_ 829 RRRrDrCurtainPosition 0;
BA_ "UserSigValidity" SG_ 829 RRRrDrCurtainPosition 0;
BA_ "GenSigSendType" SG_ 829 RRRrDrCurtainPosition 4;
BA_ "Version" SG_ 829 RRRrDrCurtainDownInitState "24.01.05";
BA_ "NetworkRequestHoldingTime" SG_ 829 RRRrDrCurtainDownInitState 5000;
BA_ "NetworkRequest" SG_ 829 RRRrDrCurtainDownInitState 0;
BA_ "UserSigValidity" SG_ 829 RRRrDrCurtainDownInitState 0;
BA_ "GenSigSendType" SG_ 829 RRRrDrCurtainDownInitState 4;
BA_ "Version" SG_ 829 PwrDrSta_RrRt "24.01.05";
BA_ "NetworkRequestHoldingTime" SG_ 829 PwrDrSta_RrRt 5000;
BA_ "NetworkRequest" SG_ 829 PwrDrSta_RrRt 0;
BA_ "UserSigValidity" SG_ 829 PwrDrSta_RrRt 0;
BA_ "GenSigSendType" SG_ 829 PwrDrSta_RrRt 4;
BA_ "Version" SG_ 829 PwrDRBuzzerOut_RR_New "24.01.05";
BA_ "NetworkRequestHoldingTime" SG_ 829 PwrDRBuzzerOut_RR_New 5000;
BA_ "NetworkRequest" SG_ 829 PwrDRBuzzerOut_RR_New 0;
BA_ "UserSigValidity" SG_ 829 PwrDRBuzzerOut_RR_New 0;
BA_ "GenSigSendType" SG_ 829 PwrDRBuzzerOut_RR_New 4;
BA_ "Version" SG_ 829 SBCM_RR_SlidePosition "24.01.05";
BA_ "NetworkRequestHoldingTime" SG_ 829 SBCM_RR_SlidePosition 5000;
BA_ "NetworkRequest" SG_ 829 SBCM_RR_SlidePosition 0;
BA_ "UserSigValidity" SG_ 829 SBCM_RR_SlidePosition 0;
BA_ "GenSigStartValue" SG_ 829 SBCM_RR_SlidePosition 255;
BA_ "GenSigSendType" SG_ 829 SBCM_RR_SlidePosition 4;
BA_ "Description" SG_ 829 SBCM_RR_SlidePosition "DHMC_RR_SlidePosition";
BA_ "Version" SG_ 829 SBCM_RR_DoorAngle "24.01.05";
BA_ "NetworkRequestHoldingTime" SG_ 829 SBCM_RR_DoorAngle 5000;
BA_ "NetworkRequest" SG_ 829 SBCM_RR_DoorAngle 0;
BA_ "UserSigValidity" SG_ 829 SBCM_RR_DoorAngle 0;
BA_ "GenSigStartValue" SG_ 829 SBCM_RR_DoorAngle 100;
BA_ "GenSigSendType" SG_ 829 SBCM_RR_DoorAngle 4;
BA_ "Description" SG_ 829 SBCM_RR_DoorAngle "PDSM_RR_DoorAngle";
BA_ "Version" SG_ 829 RRDoorPushAlarm_Copy_0 "21.07.07";
BA_ "NetworkRequestHoldingTime" SG_ 829 RRDoorPushAlarm_Copy_0 5000;
BA_ "NetworkRequest" SG_ 829 RRDoorPushAlarm_Copy_0 0;
BA_ "UserSigValidity" SG_ 829 RRDoorPushAlarm_Copy_0 0;
BA_ "GenSigSendType" SG_ 829 RRDoorPushAlarm_Copy_0 4;
BA_ "Version" SG_ 829 RR_CrashUnlockCmd_Copy_0 "21.07.07";
BA_ "NetworkRequest" SG_ 829 RR_CrashUnlockCmd_Copy_0 0;
BA_ "UserSigValidity" SG_ 829 RR_CrashUnlockCmd_Copy_0 0;
BA_ "GenSigSendType" SG_ 829 RR_CrashUnlockCmd_Copy_0 4;
BA_ "Description" SG_ 829 RR_CrashUnlockCmd_Copy_0 "RearRightCrashUnlockCommand";
BA_ "Version" SG_ 829 Warn_RrRtDrSwSta_SBCM_Copy_0 "21.09.05";
BA_ "NetworkRequest" SG_ 829 Warn_RrRtDrSwSta_SBCM_Copy_0 0;
BA_ "UserSigValidity" SG_ 829 Warn_RrRtDrSwSta_SBCM_Copy_0 0;
BA_ "GenSigSendType" SG_ 829 Warn_RrRtDrSwSta_SBCM_Copy_0 4;
BA_ "Description" SG_ 829 Warn_RrRtDrSwSta_SBCM_Copy_0 "Warning Rear Right Door Switch Status";
BA_ "Version" SG_ 829 DoorLock_RrRtDrUnLkSta_SBCM_Copy "21.07.07";
BA_ "NetworkRequest" SG_ 829 DoorLock_RrRtDrUnLkSta_SBCM_Copy 0;
BA_ "UserSigValidity" SG_ 829 DoorLock_RrRtDrUnLkSta_SBCM_Copy 0;
BA_ "GenSigSendType" SG_ 829 DoorLock_RrRtDrUnLkSta_SBCM_Copy 4;
BA_ "Description" SG_ 829 DoorLock_RrRtDrUnLkSta_SBCM_Copy "Rear Right Door Unlock Status";
BA_ "SystemSignalLongSymbol" SG_ 829 DoorLock_RrRtDrUnLkSta_SBCM_Copy "DoorLock_RrRtDrUnLkSta_SBCM_Copy_0";
BA_ "Version" SG_ 829 RR_SEAActivated_Copy_0 "21.07.07";
BA_ "NetworkRequest" SG_ 829 RR_SEAActivated_Copy_0 0;
BA_ "UserSigValidity" SG_ 829 RR_SEAActivated_Copy_0 0;
BA_ "GenSigSendType" SG_ 829 RR_SEAActivated_Copy_0 4;
BA_ "Description" SG_ 829 RR_SEAActivated_Copy_0 "RearRightSEAActivated";
BA_ "Version" SG_ 829 RR_SEAWarn_Copy_0 "21.07.07";
BA_ "NetworkRequest" SG_ 829 RR_SEAWarn_Copy_0 0;
BA_ "UserSigValidity" SG_ 829 RR_SEAWarn_Copy_0 0;
BA_ "GenSigSendType" SG_ 829 RR_SEAWarn_Copy_0 4;
BA_ "Description" SG_ 829 RR_SEAWarn_Copy_0 "RearRighrSEAWarning";
BA_ "Version" SG_ 829 RR_SEWWarn_Copy_0 "21.07.07";
BA_ "NetworkRequest" SG_ 829 RR_SEWWarn_Copy_0 0;
BA_ "UserSigValidity" SG_ 829 RR_SEWWarn_Copy_0 0;
BA_ "GenSigSendType" SG_ 829 RR_SEWWarn_Copy_0 4;
BA_ "Version" SG_ 829 RR_ReleaseWarn_Copy_0 "21.09.05";
BA_ "NetworkRequestHoldingTime" SG_ 829 RR_ReleaseWarn_Copy_0 5000;
BA_ "NetworkRequest" SG_ 829 RR_ReleaseWarn_Copy_0 0;
BA_ "UserSigValidity" SG_ 829 RR_ReleaseWarn_Copy_0 0;
BA_ "GenSigSendType" SG_ 829 RR_ReleaseWarn_Copy_0 4;
BA_ "Version" SG_ 829 RR_SWFailAlarm_Copy_0 "21.07.07";
BA_ "NetworkRequestHoldingTime" SG_ 829 RR_SWFailAlarm_Copy_0 5000;
BA_ "NetworkRequest" SG_ 829 RR_SWFailAlarm_Copy_0 0;
BA_ "UserSigValidity" SG_ 829 RR_SWFailAlarm_Copy_0 0;
BA_ "GenSigSendType" SG_ 829 RR_SWFailAlarm_Copy_0 4;
BA_ "Version" SG_ 829 RR_ChildLock_ActnFlSta_Copy_0 "21.07.07";
BA_ "NetworkRequestHoldingTime" SG_ 829 RR_ChildLock_ActnFlSta_Copy_0 5000;
BA_ "NetworkRequest" SG_ 829 RR_ChildLock_ActnFlSta_Copy_0 0;
BA_ "UserSigValidity" SG_ 829 RR_ChildLock_ActnFlSta_Copy_0 0;
BA_ "GenSigSendType" SG_ 829 RR_ChildLock_ActnFlSta_Copy_0 4;
BA_ "Version" SG_ 829 RR_MRActivationAlarm_Copy_0 "21.07.07";
BA_ "NetworkRequestHoldingTime" SG_ 829 RR_MRActivationAlarm_Copy_0 5000;
BA_ "NetworkRequest" SG_ 829 RR_MRActivationAlarm_Copy_0 0;
BA_ "UserSigValidity" SG_ 829 RR_MRActivationAlarm_Copy_0 0;
BA_ "GenSigSendType" SG_ 829 RR_MRActivationAlarm_Copy_0 4;
BA_ "Version" SG_ 829 RR_ChildLock_Status_Copy_0 "21.07.07";
BA_ "NetworkRequestHoldingTime" SG_ 829 RR_ChildLock_Status_Copy_0 5000;
BA_ "NetworkRequest" SG_ 829 RR_ChildLock_Status_Copy_0 0;
BA_ "UserSigValidity" SG_ 829 RR_ChildLock_Status_Copy_0 0;
BA_ "GenSigSendType" SG_ 829 RR_ChildLock_Status_Copy_0 4;
BA_REL_ "GenSigTimeoutTime" BU_SG_REL_ L_UWB_BLE_SLV_FD SG_ 2348810498 L_TP_BDC_FD_L_UWB_BLE_SLV_FD_Byt 0;
BA_REL_ "GenSigTimeoutTime" BU_SG_REL_ L_UWB_BLE_SLV_FD SG_ 2348810498 L_TP_BDC_FD_L_UWB_BLE_SLV_F_0000 0;
BA_REL_ "GenSigTimeoutTime" BU_SG_REL_ L_UWB_BLE_SLV_FD SG_ 2348810498 L_TP_BDC_FD_L_UWB_BLE_SLV_F_0001 0;
BA_REL_ "GenSigTimeoutTime" BU_SG_REL_ L_UWB_BLE_SLV_FD SG_ 2348810498 L_TP_BDC_FD_L_UWB_BLE_SLV_F_0002 0;
BA_REL_ "GenSigTimeoutTime" BU_SG_REL_ L_UWB_BLE_SLV_FD SG_ 2348810498 L_TP_BDC_FD_L_UWB_BLE_SLV_F_0003 0;
BA_REL_ "GenSigTimeoutTime" BU_SG_REL_ L_UWB_BLE_SLV_FD SG_ 2348810498 L_TP_BDC_FD_L_UWB_BLE_SLV_F_0004 0;
BA_REL_ "GenSigTimeoutTime" BU_SG_REL_ L_UWB_BLE_SLV_FD SG_ 2348810498 L_TP_BDC_FD_L_UWB_BLE_SLV_F_0005 0;
BA_REL_ "GenSigTimeoutTime" BU_SG_REL_ L_UWB_BLE_SLV_FD SG_ 2348810498 L_TP_BDC_FD_L_UWB_BLE_SLV_F_0006 0;
BA_REL_ "GenSigTimeoutTime" BU_SG_REL_ L_UWB_BLE_SLV_FD SG_ 2348810498 L_TP_BDC_FD_L_UWB_BLE_SLV_F_0007 0;
BA_REL_ "GenSigTimeoutTime" BU_SG_REL_ L_UWB_BLE_SLV_FD SG_ 2348810498 L_TP_BDC_FD_L_UWB_BLE_SLV_F_0008 0;
BA_REL_ "GenSigTimeoutTime" BU_SG_REL_ L_UWB_BLE_SLV_FD SG_ 2348810498 L_TP_BDC_FD_L_UWB_BLE_SLV_F_0009 0;
BA_REL_ "GenSigTimeoutTime" BU_SG_REL_ L_UWB_BLE_SLV_FD SG_ 2348810498 L_TP_BDC_FD_L_UWB_BLE_SLV_F_0010 0;
BA_REL_ "GenSigTimeoutTime" BU_SG_REL_ L_UWB_BLE_SLV_FD SG_ 2348810498 L_TP_BDC_FD_L_UWB_BLE_SLV_F_0011 0;
BA_REL_ "GenSigTimeoutTime" BU_SG_REL_ L_UWB_BLE_SLV_FD SG_ 2348810498 L_TP_BDC_FD_L_UWB_BLE_SLV_F_0012 0;
BA_REL_ "GenSigTimeoutTime" BU_SG_REL_ L_UWB_BLE_SLV_FD SG_ 2348810498 L_TP_BDC_FD_L_UWB_BLE_SLV_F_0013 0;
BA_REL_ "GenSigTimeoutTime" BU_SG_REL_ L_UWB_BLE_SLV_FD SG_ 2348810498 L_TP_BDC_FD_L_UWB_BLE_SLV_F_0014 0;
BA_REL_ "GenSigTimeoutTime" BU_SG_REL_ L_UWB_BLE_SLV_FD SG_ 2348810498 L_TP_BDC_FD_L_UWB_BLE_SLV_F_0015 0;
BA_REL_ "GenSigTimeoutTime" BU_SG_REL_ L_UWB_BLE_SLV_FD SG_ 2348810498 L_TP_BDC_FD_L_UWB_BLE_SLV_F_0016 0;
BA_REL_ "GenSigTimeoutTime" BU_SG_REL_ L_UWB_BLE_SLV_FD SG_ 2348810498 L_TP_BDC_FD_L_UWB_BLE_SLV_F_0017 0;
BA_REL_ "GenSigTimeoutTime" BU_SG_REL_ L_UWB_BLE_SLV_FD SG_ 2348810498 L_TP_BDC_FD_L_UWB_BLE_SLV_F_0018 0;
BA_REL_ "GenSigTimeoutTime" BU_SG_REL_ L_UWB_BLE_SLV_FD SG_ 2348810498 L_TP_BDC_FD_L_UWB_BLE_SLV_F_0019 0;
BA_REL_ "GenSigTimeoutTime" BU_SG_REL_ L_UWB_BLE_SLV_FD SG_ 2348810498 L_TP_BDC_FD_L_UWB_BLE_SLV_F_0020 0;
BA_REL_ "GenSigTimeoutTime" BU_SG_REL_ L_UWB_BLE_SLV_FD SG_ 2348810498 L_TP_BDC_FD_L_UWB_BLE_SLV_F_0021 0;
BA_REL_ "GenSigTimeoutTime" BU_SG_REL_ L_UWB_BLE_SLV_FD SG_ 2348810498 L_TP_BDC_FD_L_UWB_BLE_SLV_F_0022 0;
BA_REL_ "GenSigTimeoutTime" BU_SG_REL_ L_UWB_BLE_SLV_FD SG_ 2348810498 L_TP_BDC_FD_L_UWB_BLE_SLV_F_0023 0;
BA_REL_ "GenSigTimeoutTime" BU_SG_REL_ L_UWB_BLE_SLV_FD SG_ 2348810498 L_TP_BDC_FD_L_UWB_BLE_SLV_F_0024 0;
BA_REL_ "GenSigTimeoutTime" BU_SG_REL_ L_UWB_BLE_SLV_FD SG_ 2348810498 L_TP_BDC_FD_L_UWB_BLE_SLV_F_0025 0;
BA_REL_ "GenSigTimeoutTime" BU_SG_REL_ L_UWB_BLE_SLV_FD SG_ 2348810498 L_TP_BDC_FD_L_UWB_BLE_SLV_F_0026 0;
BA_REL_ "GenSigTimeoutTime" BU_SG_REL_ L_UWB_BLE_SLV_FD SG_ 2348810498 L_TP_BDC_FD_L_UWB_BLE_SLV_F_0027 0;
BA_REL_ "GenSigTimeoutTime" BU_SG_REL_ L_UWB_BLE_SLV_FD SG_ 2348810498 L_TP_BDC_FD_L_UWB_BLE_SLV_F_0028 0;
BA_REL_ "GenSigTimeoutTime" BU_SG_REL_ L_UWB_BLE_SLV_FD SG_ 2348810498 L_TP_BDC_FD_L_UWB_BLE_SLV_F_0029 0;
BA_REL_ "GenSigTimeoutTime" BU_SG_REL_ L_UWB_BLE_SLV_FD SG_ 2348810498 L_TP_BDC_FD_L_UWB_BLE_SLV_F_0030 0;
BA_REL_ "GenSigTimeoutTime" BU_SG_REL_ GW_BDC_FD SG_ 2214592657 DHRR_NFCDetected 0;
BA_REL_ "GenSigTimeoutTime" BU_SG_REL_ GW_BDC_FD SG_ 2214592657 DHRR_WlcmLt_Sta 0;
BA_REL_ "GenSigTimeoutTime" BU_SG_REL_ GW_BDC_FD SG_ 2214592657 DHRR_NFCReset_Sta 0;
BA_REL_ "GenSigTimeoutTime" BU_SG_REL_ GW_BDC_FD SG_ 2348810497 L_TP_L_UWB_BLE_MST_FD_BDC_FD_Byt 0;
BA_REL_ "GenSigTimeoutTime" BU_SG_REL_ GW_BDC_FD SG_ 2348810497 L_TP_L_UWB_BLE_MST_FD_BDC_F_0000 0;
BA_REL_ "GenSigTimeoutTime" BU_SG_REL_ GW_BDC_FD SG_ 2348810497 L_TP_L_UWB_BLE_MST_FD_BDC_F_0001 0;
BA_REL_ "GenSigTimeoutTime" BU_SG_REL_ GW_BDC_FD SG_ 2348810497 L_TP_L_UWB_BLE_MST_FD_BDC_F_0002 0;
BA_REL_ "GenSigTimeoutTime" BU_SG_REL_ GW_BDC_FD SG_ 2348810497 L_TP_L_UWB_BLE_MST_FD_BDC_F_0003 0;
BA_REL_ "GenSigTimeoutTime" BU_SG_REL_ GW_BDC_FD SG_ 2348810497 L_TP_L_UWB_BLE_MST_FD_BDC_F_0004 0;
BA_REL_ "GenSigTimeoutTime" BU_SG_REL_ GW_BDC_FD SG_ 2348810497 L_TP_L_UWB_BLE_MST_FD_BDC_F_0005 0;
BA_REL_ "GenSigTimeoutTime" BU_SG_REL_ GW_BDC_FD SG_ 2348810497 L_TP_L_UWB_BLE_MST_FD_BDC_F_0006 0;
BA_REL_ "GenSigTimeoutTime" BU_SG_REL_ GW_BDC_FD SG_ 2348810497 L_TP_L_UWB_BLE_MST_FD_BDC_F_0007 0;
BA_REL_ "GenSigTimeoutTime" BU_SG_REL_ GW_BDC_FD SG_ 2348810497 L_TP_L_UWB_BLE_MST_FD_BDC_F_0008 0;
BA_REL_ "GenSigTimeoutTime" BU_SG_REL_ GW_BDC_FD SG_ 2348810497 L_TP_L_UWB_BLE_MST_FD_BDC_F_0009 0;
BA_REL_ "GenSigTimeoutTime" BU_SG_REL_ GW_BDC_FD SG_ 2348810497 L_TP_L_UWB_BLE_MST_FD_BDC_F_0010 0;
BA_REL_ "GenSigTimeoutTime" BU_SG_REL_ GW_BDC_FD SG_ 2348810497 L_TP_L_UWB_BLE_MST_FD_BDC_F_0011 0;
BA_REL_ "GenSigTimeoutTime" BU_SG_REL_ GW_BDC_FD SG_ 2348810497 L_TP_L_UWB_BLE_MST_FD_BDC_F_0012 0;
BA_REL_ "GenSigTimeoutTime" BU_SG_REL_ GW_BDC_FD SG_ 2348810497 L_TP_L_UWB_BLE_MST_FD_BDC_F_0013 0;
BA_REL_ "GenSigTimeoutTime" BU_SG_REL_ GW_BDC_FD SG_ 2348810497 L_TP_L_UWB_BLE_MST_FD_BDC_F_0014 0;
BA_REL_ "GenSigTimeoutTime" BU_SG_REL_ GW_BDC_FD SG_ 2348810497 L_TP_L_UWB_BLE_MST_FD_BDC_F_0015 0;
BA_REL_ "GenSigTimeoutTime" BU_SG_REL_ GW_BDC_FD SG_ 2348810497 L_TP_L_UWB_BLE_MST_FD_BDC_F_0016 0;
BA_REL_ "GenSigTimeoutTime" BU_SG_REL_ GW_BDC_FD SG_ 2348810497 L_TP_L_UWB_BLE_MST_FD_BDC_F_0017 0;
BA_REL_ "GenSigTimeoutTime" BU_SG_REL_ GW_BDC_FD SG_ 2348810497 L_TP_L_UWB_BLE_MST_FD_BDC_F_0018 0;
BA_REL_ "GenSigTimeoutTime" BU_SG_REL_ GW_BDC_FD SG_ 2348810497 L_TP_L_UWB_BLE_MST_FD_BDC_F_0019 0;
BA_REL_ "GenSigTimeoutTime" BU_SG_REL_ GW_BDC_FD SG_ 2348810497 L_TP_L_UWB_BLE_MST_FD_BDC_F_0020 0;
BA_REL_ "GenSigTimeoutTime" BU_SG_REL_ GW_BDC_FD SG_ 2348810497 L_TP_L_UWB_BLE_MST_FD_BDC_F_0021 0;
BA_REL_ "GenSigTimeoutTime" BU_SG_REL_ GW_BDC_FD SG_ 2348810497 L_TP_L_UWB_BLE_MST_FD_BDC_F_0022 0;
BA_REL_ "GenSigTimeoutTime" BU_SG_REL_ GW_BDC_FD SG_ 2348810497 L_TP_L_UWB_BLE_MST_FD_BDC_F_0023 0;
BA_REL_ "GenSigTimeoutTime" BU_SG_REL_ GW_BDC_FD SG_ 2348810497 L_TP_L_UWB_BLE_MST_FD_BDC_F_0024 0;
BA_REL_ "GenSigTimeoutTime" BU_SG_REL_ GW_BDC_FD SG_ 2348810497 L_TP_L_UWB_BLE_MST_FD_BDC_F_0025 0;
BA_REL_ "GenSigTimeoutTime" BU_SG_REL_ GW_BDC_FD SG_ 2348810497 L_TP_L_UWB_BLE_MST_FD_BDC_F_0026 0;
BA_REL_ "GenSigTimeoutTime" BU_SG_REL_ GW_BDC_FD SG_ 2348810497 L_TP_L_UWB_BLE_MST_FD_BDC_F_0027 0;
BA_REL_ "GenSigTimeoutTime" BU_SG_REL_ GW_BDC_FD SG_ 2348810497 L_TP_L_UWB_BLE_MST_FD_BDC_F_0028 0;
BA_REL_ "GenSigTimeoutTime" BU_SG_REL_ GW_BDC_FD SG_ 2348810497 L_TP_L_UWB_BLE_MST_FD_BDC_F_0029 0;
BA_REL_ "GenSigTimeoutTime" BU_SG_REL_ GW_BDC_FD SG_ 2348810497 L_TP_L_UWB_BLE_MST_FD_BDC_F_0030 0;
BA_REL_ "GenSigTimeoutTime" BU_SG_REL_ L_UWB_BLE_MST_FD SG_ 2348810496 L_TP_BDC_FD_L_UWB_BLE_MST_FD_Byt 0;
BA_REL_ "GenSigTimeoutTime" BU_SG_REL_ L_UWB_BLE_MST_FD SG_ 2348810496 L_TP_BDC_FD_L_UWB_BLE_MST_F_0000 0;
BA_REL_ "GenSigTimeoutTime" BU_SG_REL_ L_UWB_BLE_MST_FD SG_ 2348810496 L_TP_BDC_FD_L_UWB_BLE_MST_F_0001 0;
BA_REL_ "GenSigTimeoutTime" BU_SG_REL_ L_UWB_BLE_MST_FD SG_ 2348810496 L_TP_BDC_FD_L_UWB_BLE_MST_F_0002 0;
BA_REL_ "GenSigTimeoutTime" BU_SG_REL_ L_UWB_BLE_MST_FD SG_ 2348810496 L_TP_BDC_FD_L_UWB_BLE_MST_F_0003 0;
BA_REL_ "GenSigTimeoutTime" BU_SG_REL_ L_UWB_BLE_MST_FD SG_ 2348810496 L_TP_BDC_FD_L_UWB_BLE_MST_F_0004 0;
BA_REL_ "GenSigTimeoutTime" BU_SG_REL_ L_UWB_BLE_MST_FD SG_ 2348810496 L_TP_BDC_FD_L_UWB_BLE_MST_F_0005 0;
BA_REL_ "GenSigTimeoutTime" BU_SG_REL_ L_UWB_BLE_MST_FD SG_ 2348810496 L_TP_BDC_FD_L_UWB_BLE_MST_F_0006 0;
BA_REL_ "GenSigTimeoutTime" BU_SG_REL_ L_UWB_BLE_MST_FD SG_ 2348810496 L_TP_BDC_FD_L_UWB_BLE_MST_F_0007 0;
BA_REL_ "GenSigTimeoutTime" BU_SG_REL_ L_UWB_BLE_MST_FD SG_ 2348810496 L_TP_BDC_FD_L_UWB_BLE_MST_F_0008 0;
BA_REL_ "GenSigTimeoutTime" BU_SG_REL_ L_UWB_BLE_MST_FD SG_ 2348810496 L_TP_BDC_FD_L_UWB_BLE_MST_F_0009 0;
BA_REL_ "GenSigTimeoutTime" BU_SG_REL_ L_UWB_BLE_MST_FD SG_ 2348810496 L_TP_BDC_FD_L_UWB_BLE_MST_F_0010 0;
BA_REL_ "GenSigTimeoutTime" BU_SG_REL_ L_UWB_BLE_MST_FD SG_ 2348810496 L_TP_BDC_FD_L_UWB_BLE_MST_F_0011 0;
BA_REL_ "GenSigTimeoutTime" BU_SG_REL_ L_UWB_BLE_MST_FD SG_ 2348810496 L_TP_BDC_FD_L_UWB_BLE_MST_F_0012 0;
BA_REL_ "GenSigTimeoutTime" BU_SG_REL_ L_UWB_BLE_MST_FD SG_ 2348810496 L_TP_BDC_FD_L_UWB_BLE_MST_F_0013 0;
BA_REL_ "GenSigTimeoutTime" BU_SG_REL_ L_UWB_BLE_MST_FD SG_ 2348810496 L_TP_BDC_FD_L_UWB_BLE_MST_F_0014 0;
BA_REL_ "GenSigTimeoutTime" BU_SG_REL_ L_UWB_BLE_MST_FD SG_ 2348810496 L_TP_BDC_FD_L_UWB_BLE_MST_F_0015 0;
BA_REL_ "GenSigTimeoutTime" BU_SG_REL_ L_UWB_BLE_MST_FD SG_ 2348810496 L_TP_BDC_FD_L_UWB_BLE_MST_F_0016 0;
BA_REL_ "GenSigTimeoutTime" BU_SG_REL_ L_UWB_BLE_MST_FD SG_ 2348810496 L_TP_BDC_FD_L_UWB_BLE_MST_F_0017 0;
BA_REL_ "GenSigTimeoutTime" BU_SG_REL_ L_UWB_BLE_MST_FD SG_ 2348810496 L_TP_BDC_FD_L_UWB_BLE_MST_F_0018 0;
BA_REL_ "GenSigTimeoutTime" BU_SG_REL_ L_UWB_BLE_MST_FD SG_ 2348810496 L_TP_BDC_FD_L_UWB_BLE_MST_F_0019 0;
BA_REL_ "GenSigTimeoutTime" BU_SG_REL_ L_UWB_BLE_MST_FD SG_ 2348810496 L_TP_BDC_FD_L_UWB_BLE_MST_F_0020 0;
BA_REL_ "GenSigTimeoutTime" BU_SG_REL_ L_UWB_BLE_MST_FD SG_ 2348810496 L_TP_BDC_FD_L_UWB_BLE_MST_F_0021 0;
BA_REL_ "GenSigTimeoutTime" BU_SG_REL_ L_UWB_BLE_MST_FD SG_ 2348810496 L_TP_BDC_FD_L_UWB_BLE_MST_F_0022 0;
BA_REL_ "GenSigTimeoutTime" BU_SG_REL_ L_UWB_BLE_MST_FD SG_ 2348810496 L_TP_BDC_FD_L_UWB_BLE_MST_F_0023 0;
BA_REL_ "GenSigTimeoutTime" BU_SG_REL_ L_UWB_BLE_MST_FD SG_ 2348810496 L_TP_BDC_FD_L_UWB_BLE_MST_F_0024 0;
BA_REL_ "GenSigTimeoutTime" BU_SG_REL_ L_UWB_BLE_MST_FD SG_ 2348810496 L_TP_BDC_FD_L_UWB_BLE_MST_F_0025 0;
BA_REL_ "GenSigTimeoutTime" BU_SG_REL_ L_UWB_BLE_MST_FD SG_ 2348810496 L_TP_BDC_FD_L_UWB_BLE_MST_F_0026 0;
BA_REL_ "GenSigTimeoutTime" BU_SG_REL_ L_UWB_BLE_MST_FD SG_ 2348810496 L_TP_BDC_FD_L_UWB_BLE_MST_F_0027 0;
BA_REL_ "GenSigTimeoutTime" BU_SG_REL_ L_UWB_BLE_MST_FD SG_ 2348810496 L_TP_BDC_FD_L_UWB_BLE_MST_F_0028 0;
BA_REL_ "GenSigTimeoutTime" BU_SG_REL_ L_UWB_BLE_MST_FD SG_ 2348810496 L_TP_BDC_FD_L_UWB_BLE_MST_F_0029 0;
BA_REL_ "GenSigTimeoutTime" BU_SG_REL_ L_UWB_BLE_MST_FD SG_ 2348810496 L_TP_BDC_FD_L_UWB_BLE_MST_F_0030 0;
BA_REL_ "GenSigTimeoutTime" BU_SG_REL_ L_EDT_FD SG_ 2214592645 DHRL_Dvp_Msg 0;
BA_REL_ "GenSigTimeoutTime" BU_SG_REL_ L_EDT_FD SG_ 2214592644 DHL_Dvp_Msg 0;
BA_REL_ "GenSigTimeoutTime" BU_SG_REL_ GW_BDC_FD SG_ 2214592641 DHRL_NFCDetected 0;
BA_REL_ "GenSigTimeoutTime" BU_SG_REL_ GW_BDC_FD SG_ 2214592641 DHRL_WlcmLt_Sta 0;
BA_REL_ "GenSigTimeoutTime" BU_SG_REL_ GW_BDC_FD SG_ 2214592641 DHRL_NFCReset_Sta 0;
BA_REL_ "GenSigTimeoutTime" BU_SG_REL_ GW_BDC_FD SG_ 2214592640 DHL_NFCDetected 0;
BA_REL_ "GenSigTimeoutTime" BU_SG_REL_ GW_BDC_FD SG_ 2214592640 DHL_WlcmLt_Sta 0;
BA_REL_ "GenSigTimeoutTime" BU_SG_REL_ GW_BDC_FD SG_ 2214592640 DHL_NFCReset_Sta 0;
BA_REL_ "GenSigTimeoutTime" BU_SG_REL_ L_UWB_BLE_MST_FD SG_ 2529538305 RL_SWID_3_IVD_2 0;
BA_REL_ "GenSigTimeoutTime" BU_SG_REL_ L_UWB_BLE_MST_FD SG_ 2533736705 TRNK_SWID_3_IVD_2 0;
BA_REL_ "GenSigTimeoutTime" BU_SG_REL_ L_EDT_FD SG_ 2214592703 SLV_Dvp_Data 0;
BA_REL_ "GenSigTimeoutTime" BU_SG_REL_ L_UWB_BLE_MST_FD SG_ 2214592694 SLV_To_MST_Enc_Data4 0;
BA_REL_ "GenSigTimeoutTime" BU_SG_REL_ L_UWB_BLE_MST_FD SG_ 2214592695 SLV_To_MST_Enc_Data5 0;
BA_REL_ "GenSigTimeoutTime" BU_SG_REL_ L_UWB_BLE_MST_FD SG_ 2214592692 SLV_To_MST_Enc_Data2 0;
BA_REL_ "GenSigTimeoutTime" BU_SG_REL_ L_UWB_BLE_MST_FD SG_ 2214592693 SLV_To_MST_Enc_Data3 0;
BA_REL_ "GenSigTimeoutTime" BU_SG_REL_ GW_BDC_FD SG_ 2214592690 SLV_UWB_Ranging_Enc_Result2 0;
BA_REL_ "GenSigTimeoutTime" BU_SG_REL_ L_UWB_BLE_MST_FD SG_ 2214592690 SLV_UWB_Ranging_Enc_Result2 0;
BA_REL_ "GenSigTimeoutTime" BU_SG_REL_ GW_BDC_FD SG_ 2214592690 SLV_UWB_Ranging_Enc_Result 0;
BA_REL_ "GenSigTimeoutTime" BU_SG_REL_ L_UWB_BLE_MST_FD SG_ 2214592690 SLV_UWB_Ranging_Enc_Result 0;
BA_REL_ "GenSigTimeoutTime" BU_SG_REL_ L_UWB_BLE_MST_FD SG_ 2214592691 SLV_To_MST_Enc_Data1 0;
BA_REL_ "GenSigTimeoutTime" BU_SG_REL_ GW_BDC_FD SG_ 2214592688 SLV_BLE_Decrypt_FB 0;
BA_REL_ "GenSigTimeoutTime" BU_SG_REL_ GW_BDC_FD SG_ 2214592688 SLV_UWB_Decrypt_FB 0;
BA_REL_ "GenSigTimeoutTime" BU_SG_REL_ L_UWB_BLE_MST_FD SG_ 2214592688 SLV_MST_Decrypt_FB 0;
BA_REL_ "GenSigTimeoutTime" BU_SG_REL_ L_UWB_BLE_MST_FD SG_ 2214592688 SLV_OTA_Rsp 0;
BA_REL_ "GenSigTimeoutTime" BU_SG_REL_ L_EDT_FD SG_ 2214592688 SLV_UWB_IC_Status 0;
BA_REL_ "GenSigTimeoutTime" BU_SG_REL_ GW_BDC_FD SG_ 2214592689 SLV_UWB_FOB_RSD_Enc_Result 0;
BA_REL_ "GenSigTimeoutTime" BU_SG_REL_ L_EDT_FD SG_ 2214592687 MST_Dvp_Data 0;
BA_REL_ "GenSigTimeoutTime" BU_SG_REL_ L_UWB_BLE_SLV_FD SG_ 2214592686 MST_Download_Data 0;
BA_REL_ "GenSigTimeoutTime" BU_SG_REL_ L_UWB_FL_FD SG_ 2214592686 MST_Download_Data 0;
BA_REL_ "GenSigTimeoutTime" BU_SG_REL_ L_UWB_FRNK_FD SG_ 2214592686 MST_Download_Data 0;
BA_REL_ "GenSigTimeoutTime" BU_SG_REL_ L_UWB_FR_FD SG_ 2214592686 MST_Download_Data 0;
BA_REL_ "GenSigTimeoutTime" BU_SG_REL_ L_UWB_RL_FD SG_ 2214592686 MST_Download_Data 0;
BA_REL_ "GenSigTimeoutTime" BU_SG_REL_ L_UWB_RR_FD SG_ 2214592686 MST_Download_Data 0;
BA_REL_ "GenSigTimeoutTime" BU_SG_REL_ L_UWB_TRNK_FD SG_ 2214592686 MST_Download_Data 0;
BA_REL_ "GenSigTimeoutTime" BU_SG_REL_ L_UWB_BLE_SLV_FD SG_ 2214592685 MST_OTA_Cmd 0;
BA_REL_ "GenSigTimeoutTime" BU_SG_REL_ L_UWB_FL_FD SG_ 2214592685 MST_OTA_Cmd 0;
BA_REL_ "GenSigTimeoutTime" BU_SG_REL_ L_UWB_FRNK_FD SG_ 2214592685 MST_OTA_Cmd 0;
BA_REL_ "GenSigTimeoutTime" BU_SG_REL_ L_UWB_FR_FD SG_ 2214592685 MST_OTA_Cmd 0;
BA_REL_ "GenSigTimeoutTime" BU_SG_REL_ L_UWB_RL_FD SG_ 2214592685 MST_OTA_Cmd 0;
BA_REL_ "GenSigTimeoutTime" BU_SG_REL_ L_UWB_RR_FD SG_ 2214592685 MST_OTA_Cmd 0;
BA_REL_ "GenSigTimeoutTime" BU_SG_REL_ L_UWB_TRNK_FD SG_ 2214592685 MST_OTA_Cmd 0;
BA_REL_ "GenSigTimeoutTime" BU_SG_REL_ GW_BDC_FD SG_ 2214592684 MST_To_BDC_Loc_Enc_Data2 1500;
BA_REL_ "GenSigTimeoutTime" BU_SG_REL_ GW_BDC_FD SG_ 2214592683 MST_To_BDC_Loc_Enc_Data1 1500;
BA_REL_ "GenSigTimeoutTime" BU_SG_REL_ GW_BDC_FD SG_ 2214592682 MST_BLE_To_BDC_Enc_Data2 0;
BA_REL_ "GenSigTimeoutTime" BU_SG_REL_ GW_BDC_FD SG_ 2214592681 MST_BLE_To_BDC_Enc_Data1 0;
BA_REL_ "GenSigTimeoutTime" BU_SG_REL_ L_UWB_BLE_SLV_FD SG_ 2214592680 MST_To_UWB_Enc_Data5 0;
BA_REL_ "GenSigTimeoutTime" BU_SG_REL_ L_UWB_FL_FD SG_ 2214592680 MST_To_UWB_Enc_Data5 0;
BA_REL_ "GenSigTimeoutTime" BU_SG_REL_ L_UWB_FRNK_FD SG_ 2214592680 MST_To_UWB_Enc_Data5 0;
BA_REL_ "GenSigTimeoutTime" BU_SG_REL_ L_UWB_FR_FD SG_ 2214592680 MST_To_UWB_Enc_Data5 0;
BA_REL_ "GenSigTimeoutTime" BU_SG_REL_ L_UWB_RL_FD SG_ 2214592680 MST_To_UWB_Enc_Data5 0;
BA_REL_ "GenSigTimeoutTime" BU_SG_REL_ L_UWB_RR_FD SG_ 2214592680 MST_To_UWB_Enc_Data5 0;
BA_REL_ "GenSigTimeoutTime" BU_SG_REL_ L_UWB_TRNK_FD SG_ 2214592680 MST_To_UWB_Enc_Data5 0;
BA_REL_ "GenSigTimeoutTime" BU_SG_REL_ L_UWB_BLE_SLV_FD SG_ 2214592679 MST_To_UWB_Enc_Data4 0;
BA_REL_ "GenSigTimeoutTime" BU_SG_REL_ L_UWB_FL_FD SG_ 2214592679 MST_To_UWB_Enc_Data4 0;
BA_REL_ "GenSigTimeoutTime" BU_SG_REL_ L_UWB_FRNK_FD SG_ 2214592679 MST_To_UWB_Enc_Data4 0;
BA_REL_ "GenSigTimeoutTime" BU_SG_REL_ L_UWB_FR_FD SG_ 2214592679 MST_To_UWB_Enc_Data4 0;
BA_REL_ "GenSigTimeoutTime" BU_SG_REL_ L_UWB_RL_FD SG_ 2214592679 MST_To_UWB_Enc_Data4 0;
BA_REL_ "GenSigTimeoutTime" BU_SG_REL_ L_UWB_RR_FD SG_ 2214592679 MST_To_UWB_Enc_Data4 0;
BA_REL_ "GenSigTimeoutTime" BU_SG_REL_ L_UWB_TRNK_FD SG_ 2214592679 MST_To_UWB_Enc_Data4 0;
BA_REL_ "GenSigTimeoutTime" BU_SG_REL_ L_UWB_BLE_SLV_FD SG_ 2214592678 MST_To_UWB_Enc_Data3 0;
BA_REL_ "GenSigTimeoutTime" BU_SG_REL_ L_UWB_FL_FD SG_ 2214592678 MST_To_UWB_Enc_Data3 0;
BA_REL_ "GenSigTimeoutTime" BU_SG_REL_ L_UWB_FRNK_FD SG_ 2214592678 MST_To_UWB_Enc_Data3 0;
BA_REL_ "GenSigTimeoutTime" BU_SG_REL_ L_UWB_FR_FD SG_ 2214592678 MST_To_UWB_Enc_Data3 0;
BA_REL_ "GenSigTimeoutTime" BU_SG_REL_ L_UWB_RL_FD SG_ 2214592678 MST_To_UWB_Enc_Data3 0;
BA_REL_ "GenSigTimeoutTime" BU_SG_REL_ L_UWB_RR_FD SG_ 2214592678 MST_To_UWB_Enc_Data3 0;
BA_REL_ "GenSigTimeoutTime" BU_SG_REL_ L_UWB_TRNK_FD SG_ 2214592678 MST_To_UWB_Enc_Data3 0;
BA_REL_ "GenSigTimeoutTime" BU_SG_REL_ L_UWB_BLE_MST_FD SG_ 2529538817 RL_SWID_4_IVD_2 0;
BA_REL_ "GenSigTimeoutTime" BU_SG_REL_ L_UWB_BLE_SLV_FD SG_ 2214592677 MST_To_UWB_Enc_Data2 0;
BA_REL_ "GenSigTimeoutTime" BU_SG_REL_ L_UWB_FL_FD SG_ 2214592677 MST_To_UWB_Enc_Data2 0;
BA_REL_ "GenSigTimeoutTime" BU_SG_REL_ L_UWB_FRNK_FD SG_ 2214592677 MST_To_UWB_Enc_Data2 0;
BA_REL_ "GenSigTimeoutTime" BU_SG_REL_ L_UWB_FR_FD SG_ 2214592677 MST_To_UWB_Enc_Data2 0;
BA_REL_ "GenSigTimeoutTime" BU_SG_REL_ L_UWB_RL_FD SG_ 2214592677 MST_To_UWB_Enc_Data2 0;
BA_REL_ "GenSigTimeoutTime" BU_SG_REL_ L_UWB_RR_FD SG_ 2214592677 MST_To_UWB_Enc_Data2 0;
BA_REL_ "GenSigTimeoutTime" BU_SG_REL_ L_UWB_TRNK_FD SG_ 2214592677 MST_To_UWB_Enc_Data2 0;
BA_REL_ "GenSigTimeoutTime" BU_SG_REL_ L_UWB_BLE_SLV_FD SG_ 2214592676 MST_To_UWB_Enc_Data1 0;
BA_REL_ "GenSigTimeoutTime" BU_SG_REL_ L_UWB_FL_FD SG_ 2214592676 MST_To_UWB_Enc_Data1 0;
BA_REL_ "GenSigTimeoutTime" BU_SG_REL_ L_UWB_FRNK_FD SG_ 2214592676 MST_To_UWB_Enc_Data1 0;
BA_REL_ "GenSigTimeoutTime" BU_SG_REL_ L_UWB_FR_FD SG_ 2214592676 MST_To_UWB_Enc_Data1 0;
BA_REL_ "GenSigTimeoutTime" BU_SG_REL_ L_UWB_RL_FD SG_ 2214592676 MST_To_UWB_Enc_Data1 0;
BA_REL_ "GenSigTimeoutTime" BU_SG_REL_ L_UWB_RR_FD SG_ 2214592676 MST_To_UWB_Enc_Data1 0;
BA_REL_ "GenSigTimeoutTime" BU_SG_REL_ L_UWB_TRNK_FD SG_ 2214592676 MST_To_UWB_Enc_Data1 0;
BA_REL_ "GenSigTimeoutTime" BU_SG_REL_ L_UWB_BLE_MST_FD SG_ 2533737217 TRNK_SWID_4_IVD_2 0;
BA_REL_ "GenSigTimeoutTime" BU_SG_REL_ L_UWB_BLE_SLV_FD SG_ 2214592675 MST_RndNum_Trgt 0;
BA_REL_ "GenSigTimeoutTime" BU_SG_REL_ L_UWB_FL_FD SG_ 2214592675 MST_RndNum_Trgt 0;
BA_REL_ "GenSigTimeoutTime" BU_SG_REL_ L_UWB_FRNK_FD SG_ 2214592675 MST_RndNum_Trgt 0;
BA_REL_ "GenSigTimeoutTime" BU_SG_REL_ L_UWB_FR_FD SG_ 2214592675 MST_RndNum_Trgt 0;
BA_REL_ "GenSigTimeoutTime" BU_SG_REL_ L_UWB_RL_FD SG_ 2214592675 MST_RndNum_Trgt 0;
BA_REL_ "GenSigTimeoutTime" BU_SG_REL_ L_UWB_RR_FD SG_ 2214592675 MST_RndNum_Trgt 0;
BA_REL_ "GenSigTimeoutTime" BU_SG_REL_ L_UWB_TRNK_FD SG_ 2214592675 MST_RndNum_Trgt 0;
BA_REL_ "GenSigTimeoutTime" BU_SG_REL_ L_UWB_BLE_SLV_FD SG_ 2214592675 MST_RndNum_TRCode 0;
BA_REL_ "GenSigTimeoutTime" BU_SG_REL_ L_UWB_FL_FD SG_ 2214592675 MST_RndNum_TRCode 0;
BA_REL_ "GenSigTimeoutTime" BU_SG_REL_ L_UWB_FRNK_FD SG_ 2214592675 MST_RndNum_TRCode 0;
BA_REL_ "GenSigTimeoutTime" BU_SG_REL_ L_UWB_FR_FD SG_ 2214592675 MST_RndNum_TRCode 0;
BA_REL_ "GenSigTimeoutTime" BU_SG_REL_ L_UWB_RL_FD SG_ 2214592675 MST_RndNum_TRCode 0;
BA_REL_ "GenSigTimeoutTime" BU_SG_REL_ L_UWB_RR_FD SG_ 2214592675 MST_RndNum_TRCode 0;
BA_REL_ "GenSigTimeoutTime" BU_SG_REL_ L_UWB_TRNK_FD SG_ 2214592675 MST_RndNum_TRCode 0;
BA_REL_ "GenSigTimeoutTime" BU_SG_REL_ L_UWB_BLE_SLV_FD SG_ 2214592675 MST_RndNum_Cmd 0;
BA_REL_ "GenSigTimeoutTime" BU_SG_REL_ L_UWB_FL_FD SG_ 2214592675 MST_RndNum_Cmd 0;
BA_REL_ "GenSigTimeoutTime" BU_SG_REL_ L_UWB_FRNK_FD SG_ 2214592675 MST_RndNum_Cmd 0;
BA_REL_ "GenSigTimeoutTime" BU_SG_REL_ L_UWB_FR_FD SG_ 2214592675 MST_RndNum_Cmd 0;
BA_REL_ "GenSigTimeoutTime" BU_SG_REL_ L_UWB_RL_FD SG_ 2214592675 MST_RndNum_Cmd 0;
BA_REL_ "GenSigTimeoutTime" BU_SG_REL_ L_UWB_RR_FD SG_ 2214592675 MST_RndNum_Cmd 0;
BA_REL_ "GenSigTimeoutTime" BU_SG_REL_ L_UWB_TRNK_FD SG_ 2214592675 MST_RndNum_Cmd 0;
BA_REL_ "GenSigTimeoutTime" BU_SG_REL_ L_UWB_BLE_SLV_FD SG_ 2214592675 MST_RndNum 0;
BA_REL_ "GenSigTimeoutTime" BU_SG_REL_ L_UWB_FL_FD SG_ 2214592675 MST_RndNum 0;
BA_REL_ "GenSigTimeoutTime" BU_SG_REL_ L_UWB_FRNK_FD SG_ 2214592675 MST_RndNum 0;
BA_REL_ "GenSigTimeoutTime" BU_SG_REL_ L_UWB_FR_FD SG_ 2214592675 MST_RndNum 0;
BA_REL_ "GenSigTimeoutTime" BU_SG_REL_ L_UWB_RL_FD SG_ 2214592675 MST_RndNum 0;
BA_REL_ "GenSigTimeoutTime" BU_SG_REL_ L_UWB_RR_FD SG_ 2214592675 MST_RndNum 0;
BA_REL_ "GenSigTimeoutTime" BU_SG_REL_ L_UWB_TRNK_FD SG_ 2214592675 MST_RndNum 0;
BA_REL_ "GenSigTimeoutTime" BU_SG_REL_ GW_BDC_FD SG_ 2214592674 MST_UWB_Ranging_Enc_Result2 0;
BA_REL_ "GenSigTimeoutTime" BU_SG_REL_ GW_BDC_FD SG_ 2214592674 MST_UWB_Ranging_Enc_Result 0;
BA_REL_ "GenSigTimeoutTime" BU_SG_REL_ GW_BDC_FD SG_ 2214592673 MST_UWB_FOB_RSD_Enc_Result 0;
BA_REL_ "GenSigTimeoutTime" BU_SG_REL_ GW_BDC_FD SG_ 2214592672 MST_BLE_Decrypt_FB 0;
BA_REL_ "GenSigTimeoutTime" BU_SG_REL_ GW_BDC_FD SG_ 2214592672 MST_UWB_Decrypt_FB 0;
BA_REL_ "GenSigTimeoutTime" BU_SG_REL_ L_UWB_BLE_SLV_FD SG_ 2214592672 MST_SLV_Decrypt_FB 0;
BA_REL_ "GenSigTimeoutTime" BU_SG_REL_ GW_BDC_FD SG_ 2214592672 MST_OTA_Status 0;
BA_REL_ "GenSigTimeoutTime" BU_SG_REL_ L_EDT_FD SG_ 2214592672 MST_UWB_IC_Status 0;
BA_REL_ "GenSigTimeoutTime" BU_SG_REL_ L_UWB_BLE_MST_FD SG_ 2525342465 FR_SWID_4_IVD_2 0;
BA_REL_ "GenSigTimeoutTime" BU_SG_REL_ L_UWB_BLE_MST_FD SG_ 829 Warn_RrRtDrSwSta_SBCM_Copy_0 1500;
BA_REL_ "GenSigTimeoutTime" BU_SG_REL_ L_UWB_BLE_MST_FD SG_ 829 DoorLock_RrRtDrUnLkSta_SBCM_Copy 1500;
VAL_ 2214592657 L_DHRR_FD_Crc1Val 0 "0x0x0~0xFFFF:CRCValue" 65535 "0x0x0~0xFFFF:CRCValue" ;
VAL_ 2214592657 L_DHRR_FD_AlvCnt1Val 0 "0x0x0~0xFF:AlvCntValue" 255 "0x0x0~0xFF:AlvCntValue" ;
VAL_ 2214592657 DHRR_NFCDetected 0 "Off" 1 "Detected" ;
VAL_ 2214592657 DHRR_WlcmLt_Sta 0 "Off" 1 "On" ;
VAL_ 2214592657 DHRR_NFCReset_Sta 0 "Default" 1 "Reset Complete" ;
VAL_ 2214592641 L_DHRL_FD_Crc1Val 0 "0x0x0~0xFFFF:CRCValue" 65535 "0x0x0~0xFFFF:CRCValue" ;
VAL_ 2214592641 L_DHRL_FD_AlvCnt1Val 0 "0x0x0~0xFF:AlvCntValue" 255 "0x0x0~0xFF:AlvCntValue" ;
VAL_ 2214592641 DHRL_NFCDetected 0 "Off" 1 "Detected" ;
VAL_ 2214592641 DHRL_WlcmLt_Sta 0 "Off" 1 "On" ;
VAL_ 2214592641 DHRL_NFCReset_Sta 0 "Default" 1 "Reset Complete" ;
VAL_ 2214592640 L_DHL_FD_Crc1Val 0 "0x0x0~0xFFFF:CRCValue" 65535 "0x0x0~0xFFFF:CRCValue" ;
VAL_ 2214592640 L_DHL_FD_AlvCnt1Val 0 "0x0x0~0xFF:AlvCntValue" 255 "0x0x0~0xFF:AlvCntValue" ;
VAL_ 2214592640 DHL_NFCDetected 0 "Off" 1 "Detected" ;
VAL_ 2214592640 DHL_WlcmLt_Sta 0 "Off" 1 "On" ;
VAL_ 2214592640 DHL_NFCReset_Sta 0 "Default" 1 "Reset Complete" ;
VAL_ 2529538305 L_UWB_RL_FD_Crc5Val 0 "0x0x0~0xFFFF:CRCValue" 65535 "0x0x0~0xFFFF:CRCValue" ;
VAL_ 2529538305 L_UWB_RL_FD_AlvCnt5Val 0 "0x0x0~0xFF:AlvCntValue" 255 "0x0x0~0xFF:AlvCntValue" ;
VAL_ 2533736705 L_UWB_TRNK_FD_Crc5Val 0 "0x0x0~0xFFFF:CRCValue" 65535 "0x0x0~0xFFFF:CRCValue" ;
VAL_ 2533736705 L_UWB_TRNK_FD_AlvCnt5Val 0 "0x0x0~0xFF:AlvCntValue" 255 "0x0x0~0xFF:AlvCntValue" ;
VAL_ 2214592694 L_UWB_BLE_SLV_FD_Crc7Val 0 "0x0x0~0xFFFF:CRCValue" 65535 "0x0x0~0xFFFF:CRCValue" ;
VAL_ 2214592694 L_UWB_BLE_SLV_FD_AlvCnt7Val 0 "0x0x0~0xFF:AlvCntValue" 255 "0x0x0~0xFF:AlvCntValue" ;
VAL_ 2214592695 L_UWB_BLE_SLV_FD_Crc8Val 0 "0x0x0~0xFFFF:CRCValue" 65535 "0x0x0~0xFFFF:CRCValue" ;
VAL_ 2214592695 L_UWB_BLE_SLV_FD_AlvCnt8Val 0 "0x0x0~0xFF:AlvCntValue" 255 "0x0x0~0xFF:AlvCntValue" ;
VAL_ 2214592692 L_UWB_BLE_SLV_FD_Crc5Val 0 "0x0x0~0xFFFF:CRCValue" 65535 "0x0x0~0xFFFF:CRCValue" ;
VAL_ 2214592692 L_UWB_BLE_SLV_FD_AlvCnt5Val 0 "0x0x0~0xFF:AlvCntValue" 255 "0x0x0~0xFF:AlvCntValue" ;
VAL_ 2214592693 L_UWB_BLE_SLV_FD_Crc6Val 0 "0x0x0~0xFFFF:CRCValue" 65535 "0x0x0~0xFFFF:CRCValue" ;
VAL_ 2214592693 L_UWB_BLE_SLV_FD_AlvCnt6Val 0 "0x0x0~0xFF:AlvCntValue" 255 "0x0x0~0xFF:AlvCntValue" ;
VAL_ 2214592690 L_UWB_BLE_SLV_FD_Crc3Val 0 "0x0x0~0xFFFF:CRCValue" 65535 "0x0x0~0xFFFF:CRCValue" ;
VAL_ 2214592690 L_UWB_BLE_SLV_FD_AlvCnt3Val 0 "0x0x0~0xFF:AlvCntValue" 255 "0x0x0~0xFF:AlvCntValue" ;
VAL_ 2214592691 L_UWB_BLE_SLV_FD_Crc4Val 0 "0x0x0~0xFFFF:CRCValue" 65535 "0x0x0~0xFFFF:CRCValue" ;
VAL_ 2214592691 L_UWB_BLE_SLV_FD_AlvCnt4Val 0 "0x0x0~0xFF:AlvCntValue" 255 "0x0x0~0xFF:AlvCntValue" ;
VAL_ 2214592688 L_UWB_BLE_SLV_FD_Crc1Val 0 "0x0x0~0xFFFF:CRCValue" 65535 "0x0x0~0xFFFF:CRCValue" ;
VAL_ 2214592688 L_UWB_BLE_SLV_FD_AlvCnt1Val 0 "0x0x0~0xFF:AlvCntValue" 255 "0x0x0~0xFF:AlvCntValue" ;
VAL_ 2214592688 SLV_BLE_Decrypt_FB 0 "Default" 1 "Positive" 2 "Negative" 3 "RESERVED" 4 "RESERVED" 5 "RESERVED" 6 "RESERVED" 7 "RESERVED" 8 "RESERVED" 9 "RESERVED" 10 "RESERVED" 11 "RESERVED" 12 "RESERVED" 13 "RESERVED" 14 "RESERVED" 15 "RESERVED" ;
VAL_ 2214592688 SLV_UWB_Decrypt_FB 0 "Default" 1 "Positive" 2 "Negative" 3 "RESERVED" 4 "RESERVED" 5 "RESERVED" 6 "RESERVED" 7 "RESERVED" 8 "RESERVED" 9 "RESERVED" 10 "RESERVED" 11 "RESERVED" 12 "RESERVED" 13 "RESERVED" 14 "RESERVED" 15 "RESERVED" ;
VAL_ 2214592688 SLV_MST_Decrypt_FB 0 "Default" 1 "Positive" 2 "Negative" 3 "RESERVED" 4 "RESERVED" 5 "RESERVED" 6 "RESERVED" 7 "RESERVED" 8 "RESERVED" 9 "RESERVED" 10 "RESERVED" 11 "RESERVED" 12 "RESERVED" 13 "RESERVED" 14 "RESERVED" 15 "RESERVED" ;
VAL_ 2214592688 SLV_OTA_Rsp 0 "Default" 1 "Request_Success" 2 "Request_Fail" 3 "Erase_Success" 4 "Erase_Fail" 5 "RESERVED" 6 "RESERVED" 7 "Verify_Success" 8 "Verify_Fail" 9 "RESERVED" 10 "RESERVED" 11 "Pause_Response" 12 "RESERVED" 13 "RESERVED" 14 "RESERVED" 15 "RESERVED" ;
VAL_ 2214592688 SLV_UWB_IC_Status 0 "Status_OK" 1 "Status_Rejected" 2 "Status_Failed" 3 "Status_Syntax_Error" 4 "Status_Invalid_Param" 5 "Status_Invalid_Range" 6 "Status_Invalid_Message" 7 "Status_Unknow_GID" 8 "Status_Unknow_OID" 9 "Status_Read_Only" 10 "Status_Com_Retry" 11 "RESERVED" 12 "RESERVED" 13 "RESERVED" 14 "RESERVED" 15 "RESERVED" 17 "Session_Not_Exist" 18 "Session_Duplicate" 19 "Session_Active" 20 "Session_Max" 21 "Session_Not_Config" 22 "Session_Ongonig" 23 "RESERVED" 24 "RESERVED" 25 "RESERVED" 26 "Error_Slot_Len" 27 "Error_Slot_Per_RR" 28 "Error_STS_IDX" 29 "RESERVED" 30 "RESERVED" 31 "RESERVED" 32 "RESERVED" 33 "Init_Rejected" 34 "Init_Failed" 35 "Start_Rejected" 36 "Start_Failed" 37 "0x25~0xFF:" 255 "0x25~0xFF:" ;
VAL_ 2214592689 L_UWB_BLE_SLV_FD_Crc2Val 0 "0x0x0~0xFFFF:CRCValue" 65535 "0x0x0~0xFFFF:CRCValue" ;
VAL_ 2214592689 L_UWB_BLE_SLV_FD_AlvCnt2Val 0 "0x0x0~0xFF:AlvCntValue" 255 "0x0x0~0xFF:AlvCntValue" ;
VAL_ 2214592686 L_UWB_BLE_MST_FD_Crc15Val 0 "0x0x0~0xFFFF:CRCValue" 65535 "0x0x0~0xFFFF:CRCValue" ;
VAL_ 2214592686 L_UWB_BLE_MST_FD_AlvCnt15Val 0 "0x0x0~0xFF:AlvCntValue" 255 "0x0x0~0xFF:AlvCntValue" ;
VAL_ 2214592685 L_UWB_BLE_MST_FD_Crc14Val 0 "0x0x0~0xFFFF:CRCValue" 65535 "0x0x0~0xFFFF:CRCValue" ;
VAL_ 2214592685 L_UWB_BLE_MST_FD_AlvCnt14Val 0 "0x0x0~0xFF:AlvCntValue" 255 "0x0x0~0xFF:AlvCntValue" ;
VAL_ 2214592685 MST_OTA_Cmd 0 "Default" 1 "SLAVE_DownLoad_Request / Pause_Request" 2 "SLAVE_Erase_Memory / IVD_Request" 3 "SLAVE_Signature_Verify" 4 "UWB_MCU_DownLoad_Request" 5 "UWB_MCU_Erase_Memory" 6 "UWB_MCU_Signature_Verify" 7 "BLE_IC_DownLoad_Request" 8 "BLE_IC_Erase_Memory" 9 "BLE_IC_Signature_Verify" 10 "UWB_IC_DownLoad_Request" 11 "UWB_IC_Erase_Memory" 12 "UWB_IC_Signature_Verify" 13 "OTA_Reset_Request" 14 "OTA_Finished" 15 "Invalid" ;
VAL_ 2214592684 L_UWB_BLE_MST_FD_Crc13Val 0 "0x0x0~0xFFFF:CRCValue" 65535 "0x0x0~0xFFFF:CRCValue" ;
VAL_ 2214592684 L_UWB_BLE_MST_FD_AlvCnt13Val 0 "0x0x0~0xFF:AlvCntValue" 255 "0x0x0~0xFF:AlvCntValue" ;
VAL_ 2214592683 L_UWB_BLE_MST_FD_Crc12Val 0 "0x0x0~0xFFFF:CRCValue" 65535 "0x0x0~0xFFFF:CRCValue" ;
VAL_ 2214592683 L_UWB_BLE_MST_FD_AlvCnt12Val 0 "0x0x0~0xFF:AlvCntValue" 255 "0x0x0~0xFF:AlvCntValue" ;
VAL_ 2214592682 L_UWB_BLE_MST_FD_Crc11Val 0 "0x0x0~0xFFFF:CRCValue" 65535 "0x0x0~0xFFFF:CRCValue" ;
VAL_ 2214592682 L_UWB_BLE_MST_FD_AlvCnt11Val 0 "0x0x0~0xFF:AlvCntValue" 255 "0x0x0~0xFF:AlvCntValue" ;
VAL_ 2214592681 L_UWB_BLE_MST_FD_Crc10Val 0 "0x0x0~0xFFFF:CRCValue" 65535 "0x0x0~0xFFFF:CRCValue" ;
VAL_ 2214592681 L_UWB_BLE_MST_FD_AlvCnt10Val 0 "0x0x0~0xFF:AlvCntValue" 255 "0x0x0~0xFF:AlvCntValue" ;
VAL_ 2214592680 L_UWB_BLE_MST_FD_Crc9Val 0 "0x0x0~0xFFFF:CRCValue" 65535 "0x0x0~0xFFFF:CRCValue" ;
VAL_ 2214592680 L_UWB_BLE_MST_FD_AlvCnt9Val 0 "0x0x0~0xFF:AlvCntValue" 255 "0x0x0~0xFF:AlvCntValue" ;
VAL_ 2214592679 L_UWB_BLE_MST_FD_Crc8Val 0 "0x0x0~0xFFFF:CRCValue" 65535 "0x0x0~0xFFFF:CRCValue" ;
VAL_ 2214592679 L_UWB_BLE_MST_FD_AlvCnt8Val 0 "0x0x0~0xFF:AlvCntValue" 255 "0x0x0~0xFF:AlvCntValue" ;
VAL_ 2214592678 L_UWB_BLE_MST_FD_Crc7Val 0 "0x0x0~0xFFFF:CRCValue" 65535 "0x0x0~0xFFFF:CRCValue" ;
VAL_ 2214592678 L_UWB_BLE_MST_FD_AlvCnt7Val 0 "0x0x0~0xFF:AlvCntValue" 255 "0x0x0~0xFF:AlvCntValue" ;
VAL_ 2529538817 L_UWB_RL_FD_Crc7Val 0 "0x0x0~0xFFFF:CRCValue" 65535 "0x0x0~0xFFFF:CRCValue" ;
VAL_ 2529538817 L_UWB_RL_FD_AlvCnt7Val 0 "0x0x0~0xFF:AlvCntValue" 255 "0x0x0~0xFF:AlvCntValue" ;
VAL_ 2214592677 L_UWB_BLE_MST_FD_Crc6Val 0 "0x0x0~0xFFFF:CRCValue" 65535 "0x0x0~0xFFFF:CRCValue" ;
VAL_ 2214592677 L_UWB_BLE_MST_FD_AlvCnt6Val 0 "0x0x0~0xFF:AlvCntValue" 255 "0x0x0~0xFF:AlvCntValue" ;
VAL_ 2214592676 L_UWB_BLE_MST_FD_Crc5Val 0 "0x0x0~0xFFFF:CRCValue" 65535 "0x0x0~0xFFFF:CRCValue" ;
VAL_ 2214592676 L_UWB_BLE_MST_FD_AlvCnt5Val 0 "0x0x0~0xFF:AlvCntValue" 255 "0x0x0~0xFF:AlvCntValue" ;
VAL_ 2533737217 L_UWB_TRNK_FD_Crc7Val 0 "0x0x0~0xFFFF:CRCValue" 65535 "0x0x0~0xFFFF:CRCValue" ;
VAL_ 2533737217 L_UWB_TRNK_FD_AlvCnt7Val 0 "0x0x0~0xFF:AlvCntValue" 255 "0x0x0~0xFF:AlvCntValue" ;
VAL_ 2214592675 L_UWB_BLE_MST_FD_Crc4Val 0 "0x0x0~0xFFFF:CRCValue" 65535 "0x0x0~0xFFFF:CRCValue" ;
VAL_ 2214592675 L_UWB_BLE_MST_FD_AlvCnt4Val 0 "0x0x0~0xFF:AlvCntValue" 255 "0x0x0~0xFF:AlvCntValue" ;
VAL_ 2214592675 MST_RndNum_Trgt 0 "Default" 1 "BLE IC" 2 "UWB IC" 3 "Slave MCU" 4 "UWB MCU" 5 "ALL" 6 "RESERVED" 7 "RESERVED" 8 "RESERVED" 9 "RESERVED" 10 "RESERVED" 11 "RESERVED" 12 "RESERVED" 13 "RESERVED" 14 "RESERVED" 15 "Invalid" ;
VAL_ 2214592675 MST_RndNum_TRCode 0 "Default" 1 "Request for encryptedData" 2 "Request for Receive" 3 "Request for encryptedCMDResult" 4 "Request for Update Auth" 5 "RESERVED" 6 "RESERVED" 7 "RESERVED" 8 "RESERVED" 9 "RESERVED" 10 "RESERVED" 11 "RESERVED" 12 "RESERVED" 13 "RESERVED" 14 "RESERVED" 15 "Invalid" ;
VAL_ 2214592675 MST_RndNum_Cmd 0 "Default" 1 "Reprogramming Auth" 2 "BTAddr IRK" 3 "Kble Intro_Kble OOB Master" 4 "BLE Bonding Data1 Tx" 5 "BLE Bonding Data2 Tx" 6 "BLE Bonding Data3 Tx" 7 "BLE Bonding Data1 Rx" 8 "BLE Bonding Data2 Rx" 9 "BLE Bonding Data3 Rx" 10 "BLE Bonding Data Delete" 11 "RESERVED" 12 "RESERVED" 13 "RESERVED" 14 "RESERVED" 15 "Invalid" ;
VAL_ 2214592674 L_UWB_BLE_MST_FD_Crc3Val 0 "0x0x0~0xFFFF:CRCValue" 65535 "0x0x0~0xFFFF:CRCValue" ;
VAL_ 2214592674 L_UWB_BLE_MST_FD_AlvCnt3Val 0 "0x0x0~0xFF:AlvCntValue" 255 "0x0x0~0xFF:AlvCntValue" ;
VAL_ 2214592673 L_UWB_BLE_MST_FD_Crc2Val 0 "0x0x0~0xFFFF:CRCValue" 65535 "0x0x0~0xFFFF:CRCValue" ;
VAL_ 2214592673 L_UWB_BLE_MST_FD_AlvCnt2Val 0 "0x0x0~0xFF:AlvCntValue" 255 "0x0x0~0xFF:AlvCntValue" ;
VAL_ 2214592672 L_UWB_BLE_MST_FD_Crc1Val 0 "0x0x0~0xFFFF:CRCValue" 65535 "0x0x0~0xFFFF:CRCValue" ;
VAL_ 2214592672 L_UWB_BLE_MST_FD_AlvCnt1Val 0 "0x0x0~0xFF:AlvCntValue" 255 "0x0x0~0xFF:AlvCntValue" ;
VAL_ 2214592672 MST_BLE_Decrypt_FB 0 "Default" 1 "Positive" 2 "Negative" 3 "RESERVED" 4 "RESERVED" 5 "RESERVED" 6 "RESERVED" 7 "RESERVED" 8 "RESERVED" 9 "RESERVED" 10 "RESERVED" 11 "RESERVED" 12 "RESERVED" 13 "RESERVED" 14 "RESERVED" 15 "RESERVED" ;
VAL_ 2214592672 MST_UWB_Decrypt_FB 0 "Default" 1 "Positive" 2 "Negative" 3 "RESERVED" 4 "RESERVED" 5 "RESERVED" 6 "RESERVED" 7 "RESERVED" 8 "RESERVED" 9 "RESERVED" 10 "RESERVED" 11 "RESERVED" 12 "RESERVED" 13 "RESERVED" 14 "RESERVED" 15 "RESERVED" ;
VAL_ 2214592672 MST_SLV_Decrypt_FB 0 "Default" 1 "Positive" 2 "Negative" 3 "RESERVED" 4 "RESERVED" 5 "RESERVED" 6 "RESERVED" 7 "RESERVED" 8 "RESERVED" 9 "RESERVED" 10 "RESERVED" 11 "RESERVED" 12 "RESERVED" 13 "RESERVED" 14 "RESERVED" 15 "RESERVED" ;
VAL_ 2214592672 MST_OTA_Status 0 "Default" 1 "OTA_Start" 2 "OTA_Complete" 3 "Invaild" ;
VAL_ 2214592672 MST_UWB_IC_Status 0 "Status_OK" 1 "Status_Rejected" 2 "Status_Failed" 3 "Status_Syntax_Error" 4 "Status_Invalid_Param" 5 "Status_Invalid_Range" 6 "Status_Invalid_Message" 7 "Status_Unknow_GID" 8 "Status_Unknow_OID" 9 "Status_Read_Only" 10 "Status_Com_Retry" 11 "RESERVED" 12 "RESERVED" 13 "RESERVED" 14 "RESERVED" 15 "RESERVED" 17 "Session_Not_Exist" 18 "Session_Duplicate" 19 "Session_Active" 20 "Session_Max" 21 "Session_Not_Config" 22 "Session_Ongonig" 23 "RESERVED" 24 "RESERVED" 25 "RESERVED" 26 "Error_Slot_Len" 27 "Error_Slot_Per_RR" 28 "Error_STS_IDX" 29 "RESERVED" 30 "RESERVED" 31 "RESERVED" 32 "RESERVED" 33 "Init_Rejected" 34 "Init_Failed" 35 "Start_Rejected" 36 "Start_Failed" 37 "0x25~0xFF:RESERVED" 255 "0x25~0xFF:RESERVED" ;
VAL_ 2525342465 L_UWB_FR_FD_Crc7Val 0 "0x0x0~0xFFFF:CRCValue" 65535 "0x0x0~0xFFFF:CRCValue" ;
VAL_ 2525342465 L_UWB_FR_FD_AlvCnt7Val 0 "0x0x0~0xFF:AlvCntValue" 255 "0x0x0~0xFF:AlvCntValue" ;
VAL_ 829 SBCM_RR_FD_Crc1Val 0 "0x0x0~0xFFFF:CRCValue" 65535 "0x0x0~0xFFFF:CRCValue" ;
VAL_ 829 USM_RRGhostDoorSta_Copy_0 0 "Default" 1 "Off" 2 "On" 3 "RESERVED" ;
VAL_ 829 DoorLock_PDSLkSwSta_RR_Copy_0 0 "Lock" 1 "Unlock" 2 "RESERVED" 3 "Error Indicator" ;
VAL_ 829 PDS_TypeOption_RR_Copy_0 0 "Off" 1 "On" 2 "RESERVED" 3 "Error Indicator" ;
VAL_ 829 RR_CrashMRActAlarm_Copy_0 0 "Off" 1 "On" 2 "RESERVED" 3 "Error Indicator" ;
VAL_ 829 PwrDRBuzzerOut_RR_Copy_0 0 "OFF" 1 "Open" 2 "Close" 3 "Warning" ;
VAL_ 829 PwrDRClosingRRDrSta_Copy_0 0 "Default" 1 "Close" 2 "Open" 3 "Stop(during Close)" 4 "Stop(during Open)" 5 "RESERVED" 6 "RESERVED" 7 "Invalid" ;
VAL_ 829 AFH_RR_FldUnfldSta_Copy_0 0 "Invalid" 1 "Fold" 2 "Unfold" 3 "Inprogress" ;
VAL_ 829 SBCM_RR_FD_AlvCnt1Val 0 "0x0x0~0xFF:AlvCntValue" 255 "0x0x0~0xFF:AlvCntValue" ;
VAL_ 829 DoorLock_RrRtLkOutSta_SBCM_Copy_ 0 "Off" 1 "On" 2 "Not Used" 3 "Error Indicator" ;
VAL_ 829 RrRt_DrLkRetryFail_SBCM_Copy_0 0 "Normal" 1 "Fail" 2 "RESERVED" 3 "RESERVED" ;
VAL_ 829 RR_DetectObj_warn 0 "Detect Warning OFF" 1 "Detect Warning ON" 2 "RESERVED" 3 "RESERVED" ;
VAL_ 829 RRRrDrCurtainPosition 0 "Unkown" 1 "Bottom" 2 "Mid" 3 "Top" ;
VAL_ 829 RRRrDrCurtainDownInitState 0 "Decalibrated" 1 "Calibrated" 2 "RESERVED" 3 "Error Indicator" ;
VAL_ 829 PwrDrSta_RrRt 0 "Unavailable" 1 "Available" 2 "RESERVED" 3 "Error Indicator" ;
VAL_ 829 PwrDRBuzzerOut_RR_New 0 "OFF" 1 "Open" 2 "Close" 3 "Warning1" 4 "Warning2" ;
VAL_ 829 SBCM_RR_SlidePosition 0 "0x0x0~0x64:0% - 100%" 100 "0x0x0~0x64:0% - 100%" 101 "0x65~0xFE:RESERVED" 254 "0x65~0xFE:RESERVED" 255 "Unknown" ;
VAL_ 829 SBCM_RR_DoorAngle 0 "0б╞ - 90б╞" 1 "0б╞ - 90б╞" 2 "0б╞ - 90б╞" 3 "0б╞ - 90б╞" 4 "0б╞ - 90б╞" 5 "0б╞ - 90б╞" 6 "0б╞ - 90б╞" 7 "0б╞ - 90б╞" 8 "0б╞ - 90б╞" 9 "0б╞ - 90б╞" 10 "0б╞ - 90б╞" 11 "0б╞ - 90б╞" 12 "0б╞ - 90б╞" 13 "0б╞ - 90б╞" 14 "0б╞ - 90б╞" 15 "0б╞ - 90б╞" 16 "0б╞ - 90б╞" 17 "0б╞ - 90б╞" 18 "0б╞ - 90б╞" 19 "0б╞ - 90б╞" 20 "0б╞ - 90б╞" 21 "0б╞ - 90б╞" 22 "0б╞ - 90б╞" 23 "0б╞ - 90б╞" 24 "0б╞ - 90б╞" 25 "0б╞ - 90б╞" 26 "0б╞ - 90б╞" 27 "0б╞ - 90б╞" 28 "0б╞ - 90б╞" 29 "0б╞ - 90б╞" 30 "0б╞ - 90б╞" 31 "0б╞ - 90б╞" 32 "0б╞ - 90б╞" 33 "0б╞ - 90б╞" 34 "0б╞ - 90б╞" 35 "0б╞ - 90б╞" 36 "0б╞ - 90б╞" 37 "0б╞ - 90б╞" 38 "0б╞ - 90б╞" 39 "0б╞ - 90б╞" 40 "0б╞ - 90б╞" 41 "0б╞ - 90б╞" 42 "0б╞ - 90б╞" 43 "0б╞ - 90б╞" 44 "0б╞ - 90б╞" 45 "0б╞ - 90б╞" 46 "0б╞ - 90б╞" 47 "0б╞ - 90б╞" 48 "0б╞ - 90б╞" 49 "0б╞ - 90б╞" 50 "0б╞ - 90б╞" 51 "0б╞ - 90б╞" 52 "0б╞ - 90б╞" 53 "0б╞ - 90б╞" 54 "0б╞ - 90б╞" 55 "0б╞ - 90б╞" 56 "0б╞ - 90б╞" 57 "0б╞ - 90б╞" 58 "0б╞ - 90б╞" 59 "0б╞ - 90б╞" 60 "0б╞ - 90б╞" 61 "0б╞ - 90б╞" 62 "0б╞ - 90б╞" 63 "0б╞ - 90б╞" 64 "0б╞ - 90б╞" 65 "0б╞ - 90б╞" 66 "0б╞ - 90б╞" 67 "0б╞ - 90б╞" 68 "0б╞ - 90б╞" 69 "0б╞ - 90б╞" 70 "0б╞ - 90б╞" 71 "0б╞ - 90б╞" 72 "0б╞ - 90б╞" 73 "0б╞ - 90б╞" 74 "0б╞ - 90б╞" 75 "0б╞ - 90б╞" 76 "0б╞ - 90б╞" 77 "0б╞ - 90б╞" 78 "0б╞ - 90б╞" 79 "0б╞ - 90б╞" 80 "0б╞ - 90б╞" 81 "0б╞ - 90б╞" 82 "0б╞ - 90б╞" 83 "0б╞ - 90б╞" 84 "0б╞ - 90б╞" 85 "0б╞ - 90б╞" 86 "0б╞ - 90б╞" 87 "0б╞ - 90б╞" 88 "0б╞ - 90б╞" 89 "0б╞ - 90б╞" 90 "0б╞ - 90б╞" 91 "Invalid" 92 "Invalid" 93 "Invalid" 94 "Invalid" 95 "Invalid" 96 "Invalid" 97 "Invalid" 98 "Invalid" 99 "Invalid" 100 "Unknown" 101 "Invalid" 102 "Invalid" 103 "Invalid" 104 "Invalid" 105 "Invalid" 106 "Invalid" 107 "Invalid" 108 "Invalid" 109 "Invalid" 110 "Invalid" 111 "Invalid" 112 "Invalid" 113 "Invalid" 114 "Invalid" 115 "Invalid" 116 "Invalid" 117 "Invalid" 118 "Invalid" 119 "Invalid" 120 "Invalid" 121 "Invalid" 122 "Invalid" 123 "Invalid" 124 "Invalid" 125 "Invalid" 126 "Invalid" 127 "Invalid" ;
VAL_ 829 RRDoorPushAlarm_Copy_0 0 "Off" 1 "On" 2 "RESERVED" 3 "Error Indicator" ;
VAL_ 829 RR_CrashUnlockCmd_Copy_0 0 "Off" 1 "Unlock (Crash)" ;
VAL_ 829 Warn_RrRtDrSwSta_SBCM_Copy_0 0 "Close" 1 "Open" 2 "RESERVED" 3 "Error Indicator" ;
VAL_ 829 DoorLock_RrRtDrUnLkSta_SBCM_Copy 0 "Lock" 1 "Unlock" 2 "RESERVED" 3 "Error Indicator" ;
VAL_ 829 RR_SEAActivated_Copy_0 0 "InActivated" 1 "Activated" 2 "RESERVED" 3 "Error Indicator" ;
VAL_ 829 RR_SEAWarn_Copy_0 0 "SEA Right Warning OFF" 1 "SEA Right Warning ON" 2 "RESERVED" 3 "RESERVED" ;
VAL_ 829 RR_SEWWarn_Copy_0 0 "SEW Right Warning OFF" 1 "SEW Right Warning ON" 2 "RESERVED" 3 "RESERVED" ;
VAL_ 829 RR_ReleaseWarn_Copy_0 0 "Release Warning OFF" 1 "Release Warning ON" 2 "RESERVED" 3 "RESERVED" ;
VAL_ 829 RR_SWFailAlarm_Copy_0 0 "Off" 1 "On" 2 "RESERVED" 3 "Error Indicator" ;
VAL_ 829 RR_ChildLock_ActnFlSta_Copy_0 0 "OK" 1 "Failed" 2 "RESERVED" 3 "Error Indicator" ;
VAL_ 829 RR_MRActivationAlarm_Copy_0 0 "Off" 1 "On" 2 "RESERVED" 3 "Error Indicator" ;
VAL_ 829 RR_ChildLock_Status_Copy_0 0 "ChildLock On" 1 "ChildLock Off" 2 "RESERVED" 3 "RESERVED" ;
